VERSION "created by canmatrix"

NS_ :

BS_:

BU_: IPD

BO_ 1948 DIAG_DTCInfo_FDR: 8 Vector__XXX
 SG_ IDTCInfomationFDR : 7|56@0+ (1,0) [0|72057594037927935] "null" IPD

BO_ 1949 DIAG_DTCInfo_ICBAD: 8 IPD
 SG_ IDTCInfomationIPD : 7|56@0+ (1,0) [0|72057594037927935] "null" Vector__XXX

BO_ 1319 DKMM_LHBDCANFD_Event_FrS03: 8 Vector__XXX
 SG_ IAIParkngSpcID : 31|5@0+ (1,0) [0|31] "null" IPD

BO_ 2015 Diag_BKPCANFD_FuncReq: 64 Vector__XXX

BO_ 1845 Diag_BKPCANFD_PhyReq_ICBAD: 64 Vector__XXX

BO_ 1853 Diag_BKPCANFD_PhyResp_ICBAD: 64 IPD

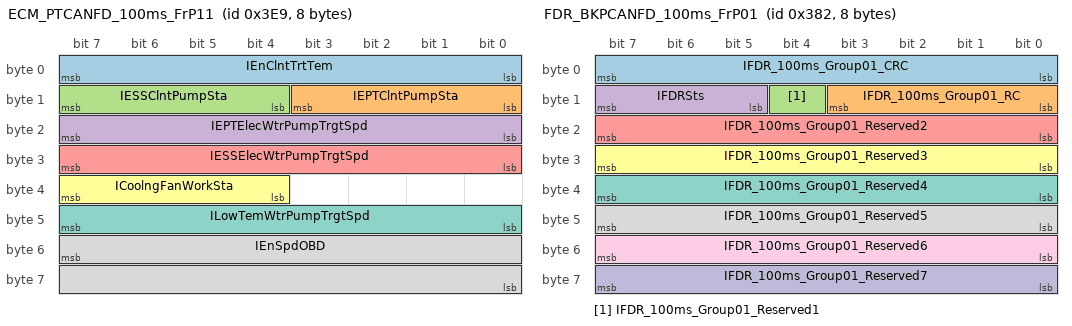
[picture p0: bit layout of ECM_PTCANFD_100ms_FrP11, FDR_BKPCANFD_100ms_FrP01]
BO_ 1001 ECM_PTCANFD_100ms_FrP11: 8 Vector__XXX
 SG_ IEnClntTrtTem : 7|8@0+ (0.5,-40) [-40|87.5] "null" Vector__XXX
 SG_ IEPTClntPumpSta : 11|4@0+ (1,0) [0|15] "null" IPD
 SG_ IESSClntPumpSta : 15|4@0+ (1,0) [0|15] "null" Vector__XXX
 SG_ IEPTElecWtrPumpTrgtSpd : 23|8@0+ (0.4,0) [0|102] "null" Vector__XXX
 SG_ IESSElecWtrPumpTrgtSpd : 31|8@0+ (0.4,0) [0|102] "null" Vector__XXX
 SG_ ICoolngFanWorkSta : 39|4@0+ (1,0) [0|15] "null" Vector__XXX
 SG_ ILowTemWtrPumpTrgtSpd : 47|8@0+ (0.4,0) [0|102] "null" Vector__XXX
 SG_ IEnSpdOBD : 55|16@0+ (0.25,0) [0.00|16383.75] "rpm" Vector__XXX

BO_ 1762 FDR_BKBCANFD_EvtInfo: 8 Vector__XXX
 SG_ IEvtPotclSigFDR : 7|64@0+ (1,0) [0|18446744073709551615] "null" IPD

BO_ 898 FDR_BKPCANFD_100ms_FrP01: 8 Vector__XXX
 SG_ IFDR_100ms_Group01_CRC : 7|8@0+ (1,0) [0|255] "null" IPD
 SG_ IFDR_100ms_Group01_RC : 11|4@0+ (1,0) [0|15] "null" IPD
 SG_ IFDR_100ms_Group01_Reserved1 : 12|1@0+ (1,0) [0|1] "null" IPD
 SG_ IFDRSts : 15|3@0+ (1,0) [0|7] "null" IPD
 SG_ IFDR_100ms_Group01_Reserved2 : 23|8@0+ (1,0) [0|255] "null" IPD
 SG_ IFDR_100ms_Group01_Reserved3 : 31|8@0+ (1,0) [0|255] "null" IPD
 SG_ IFDR_100ms_Group01_Reserved4 : 39|8@0+ (1,0) [0|255] "null" IPD
 SG_ IFDR_100ms_Group01_Reserved5 : 47|8@0+ (1,0) [0|255] "null" IPD
 SG_ IFDR_100ms_Group01_Reserved6 : 55|8@0+ (1,0) [0|255] "null" IPD
 SG_ IFDR_100ms_Group01_Reserved7 : 63|8@0+ (1,0) [0|255] "null" IPD

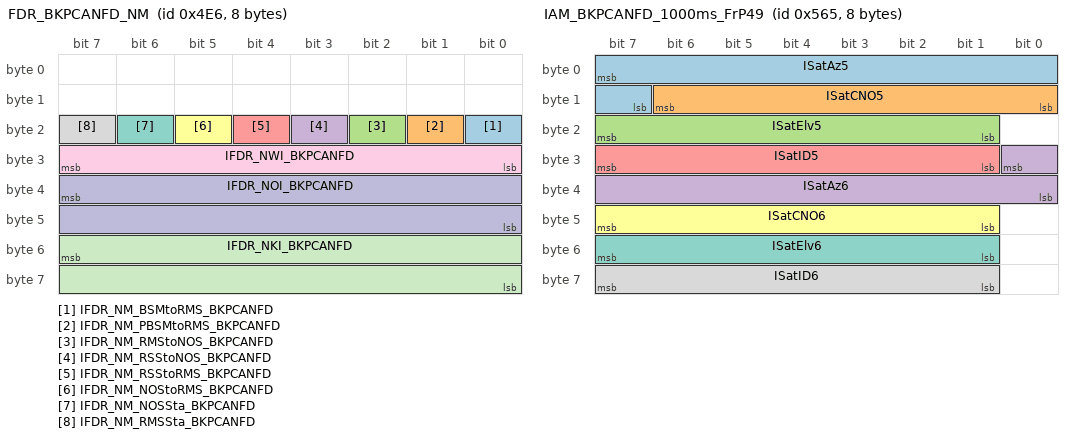
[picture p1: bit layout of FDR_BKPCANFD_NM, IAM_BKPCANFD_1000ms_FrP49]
BO_ 1254 FDR_BKPCANFD_NM: 8 Vector__XXX
 SG_ IFDR_NM_BSMtoRMS_BKPCANFD : 16|1@0+ (1,0) [0|1] "null" IPD
 SG_ IFDR_NM_PBSMtoRMS_BKPCANFD : 17|1@0+ (1,0) [0|1] "null" IPD
 SG_ IFDR_NM_RMStoNOS_BKPCANFD : 18|1@0+ (1,0) [0|1] "null" IPD
 SG_ IFDR_NM_RSStoNOS_BKPCANFD : 19|1@0+ (1,0) [0|1] "null" IPD
 SG_ IFDR_NM_RSStoRMS_BKPCANFD : 20|1@0+ (1,0) [0|1] "null" IPD
 SG_ IFDR_NM_NOStoRMS_BKPCANFD : 21|1@0+ (1,0) [0|1] "null" IPD
 SG_ IFDR_NM_NOSSta_BKPCANFD : 22|1@0+ (1,0) [0|1] "null" IPD
 SG_ IFDR_NM_RMSSta_BKPCANFD : 23|1@0+ (1,0) [0|1] "null" IPD
 SG_ IFDR_NWI_BKPCANFD : 31|8@0+ (1,0) [0|255] "null" IPD
 SG_ IFDR_NOI_BKPCANFD : 39|16@0+ (1,0) [0|65535] "null" IPD
 SG_ IFDR_NKI_BKPCANFD : 55|16@0+ (1,0) [0|65535] "null" IPD

BO_ 139 FDR_SecOC_ComKeyResp: 8 Vector__XXX
 SG_ IFDRTripCtrRstResp : 6|1@0+ (1,0) [0|1] "null" IPD
 SG_ IFDRComKeyEnbResp : 7|1@0+ (1,0) [0|1] "null" IPD

BO_ 958 FVCM_BKPCANFD_100ms_FrP04: 64 IPD
 SG_ IACCConfmSw : 137|2@0+ (1,0) [0|3] "null" Vector__XXX
 SG_ IELKWarning : 191|4@0+ (1,0) [0|15] "null" Vector__XXX
 SG_ IACCDrvrTkovReq : 256|1@0+ (1,0) [0|1] "null" Vector__XXX

BO_ 956 FVCM_BKPCANFD_100ms_FrP05: 64 IPD
 SG_ IPilotSysMsg : 15|4@0+ (1,0) [0|15] "null" Vector__XXX
 SG_ ILane0_C0 : 23|12@0+ (0.00390625,-8) [-8.00000000|7.99609375] "null" Vector__XXX
 SG_ ILane0_C1 : 27|12@0+ (0.00048828125,-1) [-1.00000000000|0.99951171875] "null" Vector__XXX
 SG_ ILane0_C2 : 47|12@0+ (0.000015259,-0.03124285) [-0.031242850|0.031242755] "null" Vector__XXX
 SG_ ILane0_C3 : 51|12@0+ (4.768E-007,-2.3842E-007) [-2.3842E-007|0.00195225758] "null" Vector__XXX
 SG_ ILane1_C0 : 71|12@0+ (0.00390625,-8) [-8.00000000|7.99609375] "null" Vector__XXX
 SG_ ILane1_C1 : 75|12@0+ (0.00048828125,-1) [-1.00000000000|0.99951171875] "null" Vector__XXX
 SG_ ILane1_C2 : 95|12@0+ (0.000015259,-0.03124285) [-0.031242850|0.031242755] "null" Vector__XXX
 SG_ ILane1_C3 : 99|12@0+ (4.768E-007,-2.3842E-007) [-2.3842E-007|0.00195225758] "null" Vector__XXX
 SG_ ILane0_ViewRangeStart : 215|8@0+ (0.25,0) [0.00|63.75] "null" Vector__XXX
 SG_ ILane1_ViewRangeStart : 223|8@0+ (0.25,0) [0.00|63.75] "null" Vector__XXX
 SG_ ILane0_ViewRangeEnd : 247|9@0+ (0.25,0) [0.00|127.75] "null" Vector__XXX
 SG_ ILane1_ViewRangeEnd : 248|9@0+ (0.25,0) [0.00|127.75] "null" Vector__XXX
 SG_ ILane0_ExistPrblty : 254|6@0+ (0.015625,0) [0.000000|0.984375] "null" Vector__XXX
 SG_ ILane1_ExistPrblty : 278|6@0+ (0.015625,0) [0.000000|0.984375] "null" Vector__XXX
 SG_ ILane0_ID : 295|4@0+ (1,0) [0|15] "null" Vector__XXX
 SG_ ILane1_ID : 303|4@0+ (1,0) [0|15] "null" Vector__XXX
 SG_ ITLRMsgReq : 321|2@0+ (1,0) [0|3] "null" Vector__XXX
 SG_ ILane0_location : 327|3@0+ (1,0) [0|7] "null" Vector__XXX
 SG_ ITLRSysSts : 329|2@0+ (1,0) [0|3] "null" Vector__XXX
 SG_ ILane1_location : 332|3@0+ (1,0) [0|7] "null" Vector__XXX
 SG_ ITrgtSpdSrcSts_IPD : 337|2@0+ (1,0) [0|3] "null" Vector__XXX
 SG_ ISLIFWrnngMdResp : 345|2@0+ (1,0) [0|3] "null" Vector__XXX
 SG_ ITLRWarning : 388|3@0+ (1,0) [0|7] "null" Vector__XXX
 SG_ ITLRMdSwDspCmd : 391|3@0+ (1,0) [0|7] "null" Vector__XXX
 SG_ ISpdLmtOfstSetResp : 399|6@0+ (1,-20) [-20|43] "null" Vector__XXX
 SG_ ISLIFAudWrnng_IPD : 472|1@0+ (1,0) [0|1] "null" Vector__XXX
 SG_ ISLIFUpdtIndResp_IPD : 473|1@0+ (1,0) [0|1] "null" Vector__XXX
 SG_ ISLIFUpdtInd_IPD : 500|1@0+ (1,0) [0|1] "null" Vector__XXX
 SG_ ICCSpdVcCmdCnfm : 503|3@0+ (1,0) [0|7] "null" Vector__XXX

BO_ 307 FVCM_BKPCANFD_20ms_FrP02: 16 IPD
 SG_ IFVCM_20ms_Group02_CRC : 7|8@0+ (1,0) [0|255] "null" Vector__XXX
 SG_ IFVCM_20ms_Group02_RC : 11|4@0+ (1,0) [0|15] "null" Vector__XXX
 SG_ IFVCM_20ms_Group02_Reserved1 : 15|4@0+ (1,0) [0|15] "null" Vector__XXX
 SG_ IFVCM_20ms_Group02_Reserved2 : 23|8@0+ (1,0) [0|255] "null" Vector__XXX
 SG_ IFVCM_20ms_Group02_Reserved3 : 31|8@0+ (1,0) [0|255] "null" Vector__XXX
 SG_ IACCDrvrSelTrgtSpd : 39|15@0+ (0.015625,0) [0.000000|511.984375] "ms" Vector__XXX
 SG_ IACCGoNotfr : 40|1@0+ (1,0) [0|1] "null" Vector__XXX
 SG_ IFVCM_20ms_Group02_Reserved4 : 48|1@0+ (1,0) [0|1] "null" Vector__XXX
 SG_ IACCDetObjDistLvl : 51|3@0+ (1,0) [0|7] "null" Vector__XXX
 SG_ IELKSysSts_IPD : 55|4@0+ (1,0) [0|15] "null" Vector__XXX
 SG_ IFVCM_20ms_Group02_Reserved5 : 57|2@0+ (1,0) [0|3] "null" Vector__XXX
 SG_ IACCTJAMdSwDspCmd : 60|3@0+ (1,0) [0|7] "null" Vector__XXX
 SG_ IACCSeldTrgtDistLvl : 63|3@0+ (1,0) [0|7] "null" Vector__XXX
 SG_ IFVCM_20ms_Group02_Reserved6 : 71|8@0+ (1,0) [0|255] "null" Vector__XXX
 SG_ IHandOffStrgWhlDetnSta : 73|2@0+ (1,0) [0|3] "null" Vector__XXX
 SG_ IILCActvnDircnDspCmd : 76|3@0+ (1,0) [0|7] "null" Vector__XXX
 SG_ IFVCM_20ms_Group02_Reserved7 : 79|3@0+ (1,0) [0|7] "null" Vector__XXX
 SG_ IILCSwDspCmd : 81|2@0+ (1,0) [0|3] "null" Vector__XXX
 SG_ IILCSysSts : 84|3@0+ (1,0) [0|7] "null" Vector__XXX
 SG_ IILCActvnVelDspCmd : 87|3@0+ (1,0) [0|7] "null" Vector__XXX
 SG_ IHandOffStrgWhlDetnStaV : 88|1@0+ (1,0) [0|1] "null" Vector__XXX
 SG_ ILDWLKAAudReq : 90|2@0+ (1,0) [0|3] "null" Vector__XXX
 SG_ ILDWAdoWrnngDspCmd : 92|2@0+ (1,0) [0|3] "null" Vector__XXX
 SG_ ILDWLKADspCmd : 95|3@0+ (1,0) [0|7] "null" Vector__XXX
 SG_ IFVCM_20ms_Group02_Reserved8 : 98|3@0+ (1,0) [0|7] "null" Vector__XXX
 SG_ ILKADrvrTkovReq : 99|1@0+ (1,0) [0|1] "null" Vector__XXX
 SG_ ILDWSnstvtLvl : 101|2@0+ (1,0) [0|3] "null" Vector__XXX
 SG_ ILDWLKAHptWrnngDspCmd : 103|2@0+ (1,0) [0|3] "null" Vector__XXX
 SG_ IFVCM_20ms_Group02_Reserved9 : 111|8@0+ (1,0) [0|255] "null" Vector__XXX
 SG_ IFVCM_20ms_Group02_Reserved10 : 114|3@0+ (1,0) [0|7] "null" Vector__XXX
 SG_ IACCMsgReq : 119|5@0+ (1,0) [0|31] "null" Vector__XXX
 SG_ IFVCM_20ms_Group02_Reserved11 : 127|8@0+ (1,0) [0|255] "null" Vector__XXX

BO_ 747 FVCM_BKPCANFD_50ms_FrP03: 12 IPD
 SG_ IFVCM_50ms_Group03_CRC : 7|8@0+ (1,0) [0|255] "null" Vector__XXX
 SG_ IFVCM_50ms_Group03_RC : 11|4@0+ (1,0) [0|15] "null" Vector__XXX
 SG_ IKeepPwrRsnFVCM : 15|4@0+ (1,0) [0|15] "null" Vector__XXX
 SG_ IFVCM_50ms_Group03_Reserved1 : 21|6@0+ (1,0) [0|63] "null" Vector__XXX
 SG_ ITLRTrafficLightsCircleDsp : 23|2@0+ (1,0) [0|3] "null" Vector__XXX
 SG_ IFVCM_50ms_Group03_Reserved2 : 31|8@0+ (1,0) [0|255] "null" Vector__XXX
 SG_ IFVCM_50ms_Group03_Reserved3 : 39|8@0+ (1,0) [0|255] "null" Vector__XXX
 SG_ IFVCM_50ms_Group03_Reserved4 : 47|8@0+ (1,0) [0|255] "null" Vector__XXX
 SG_ IFVCM_50ms_Group03_Reserved5 : 55|8@0+ (1,0) [0|255] "null" Vector__XXX
 SG_ IFVCM_50ms_Group03_Reserved6 : 63|8@0+ (1,0) [0|255] "null" Vector__XXX
 SG_ IFVCM_50ms_Group03_Reserved7 : 71|8@0+ (1,0) [0|255] "null" Vector__XXX
 SG_ IFVCM_50ms_Group03_Reserved8 : 79|8@0+ (1,0) [0|255] "null" Vector__XXX
 SG_ IFVCM_50ms_Group03_Reserved9 : 87|8@0+ (1,0) [0|255] "null" Vector__XXX
 SG_ IFVCM_50ms_Group03_Reserved10 : 95|8@0+ (1,0) [0|255] "null" Vector__XXX

BO_ 1381 IAM_BKPCANFD_1000ms_FrP49: 8 Vector__XXX
 SG_ ISatAz5 : 7|9@0+ (1,0) [0|511] "Degree" IPD
 SG_ ISatCNO5 : 14|7@0+ (1,0) [0|127] "dB" IPD
 SG_ ISatElv5 : 23|7@0+ (1,0) [0|127] "Degree" IPD
 SG_ ISatAz6 : 24|9@0+ (1,0) [0|511] "Degree" IPD
 SG_ ISatID5 : 31|7@0+ (1,0) [0|127] "null" IPD
 SG_ ISatCNO6 : 47|7@0+ (1,0) [0|127] "dB" IPD
 SG_ ISatElv6 : 55|7@0+ (1,0) [0|127] "Degree" IPD
 SG_ ISatID6 : 63|7@0+ (1,0) [0|127] "null" IPD

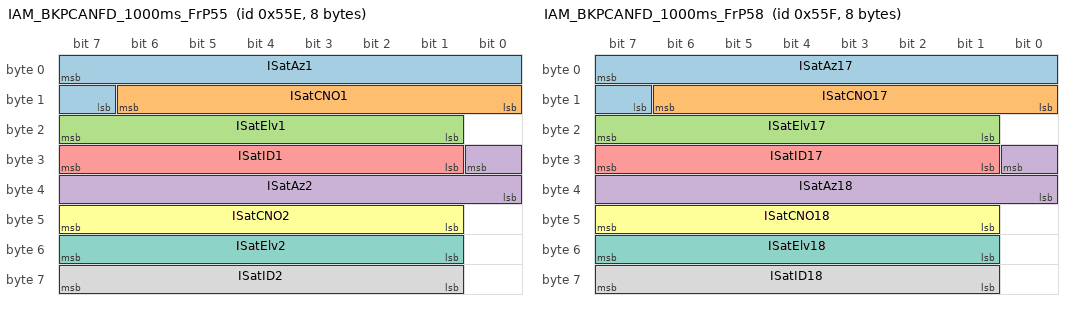
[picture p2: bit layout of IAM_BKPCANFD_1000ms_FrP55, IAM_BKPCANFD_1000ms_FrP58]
BO_ 1374 IAM_BKPCANFD_1000ms_FrP55: 8 Vector__XXX
 SG_ ISatAz1 : 7|9@0+ (1,0) [0|511] "Degree" IPD
 SG_ ISatCNO1 : 14|7@0+ (1,0) [0|127] "dB" IPD
 SG_ ISatElv1 : 23|7@0+ (1,0) [0|127] "Degree" IPD
 SG_ ISatAz2 : 24|9@0+ (1,0) [0|511] "Degree" IPD
 SG_ ISatID1 : 31|7@0+ (1,0) [0|127] "null" IPD
 SG_ ISatCNO2 : 47|7@0+ (1,0) [0|127] "dB" IPD
 SG_ ISatElv2 : 55|7@0+ (1,0) [0|127] "Degree" IPD
 SG_ ISatID2 : 63|7@0+ (1,0) [0|127] "null" IPD

BO_ 1375 IAM_BKPCANFD_1000ms_FrP58: 8 Vector__XXX
 SG_ ISatAz17 : 7|9@0+ (1,0) [0|511] "Degree" IPD
 SG_ ISatCNO17 : 14|7@0+ (1,0) [0|127] "dB" IPD
 SG_ ISatElv17 : 23|7@0+ (1,0) [0|127] "Degree" IPD
 SG_ ISatAz18 : 24|9@0+ (1,0) [0|511] "Degree" IPD
 SG_ ISatID17 : 31|7@0+ (1,0) [0|127] "null" IPD
 SG_ ISatCNO18 : 47|7@0+ (1,0) [0|127] "dB" IPD
 SG_ ISatElv18 : 55|7@0+ (1,0) [0|127] "Degree" IPD
 SG_ ISatID18 : 63|7@0+ (1,0) [0|127] "null" IPD

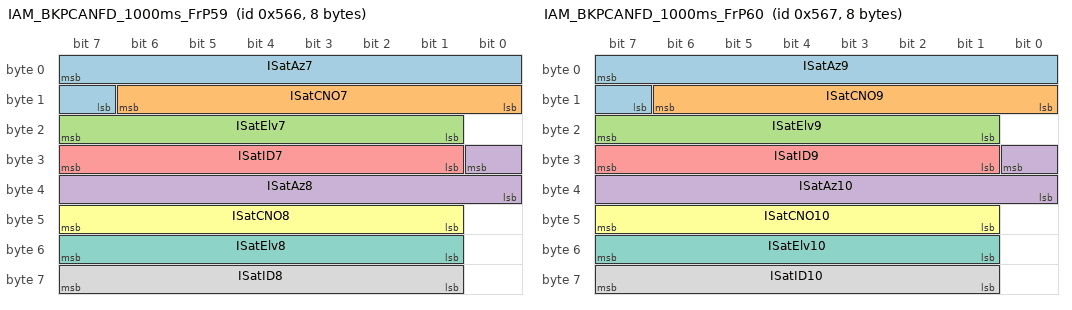
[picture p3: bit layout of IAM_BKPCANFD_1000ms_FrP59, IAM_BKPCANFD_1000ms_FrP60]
BO_ 1382 IAM_BKPCANFD_1000ms_FrP59: 8 Vector__XXX
 SG_ ISatAz7 : 7|9@0+ (1,0) [0|511] "Degree" IPD
 SG_ ISatCNO7 : 14|7@0+ (1,0) [0|127] "dB" IPD
 SG_ ISatElv7 : 23|7@0+ (1,0) [0|127] "Degree" IPD
 SG_ ISatAz8 : 24|9@0+ (1,0) [0|511] "Degree" IPD
 SG_ ISatID7 : 31|7@0+ (1,0) [0|127] "null" IPD
 SG_ ISatCNO8 : 47|7@0+ (1,0) [0|127] "dB" IPD
 SG_ ISatElv8 : 55|7@0+ (1,0) [0|127] "Degree" IPD
 SG_ ISatID8 : 63|7@0+ (1,0) [0|127] "null" IPD

BO_ 1383 IAM_BKPCANFD_1000ms_FrP60: 8 Vector__XXX
 SG_ ISatAz9 : 7|9@0+ (1,0) [0|511] "Degree" IPD
 SG_ ISatCNO9 : 14|7@0+ (1,0) [0|127] "dB" IPD
 SG_ ISatElv9 : 23|7@0+ (1,0) [0|127] "Degree" IPD
 SG_ ISatAz10 : 24|9@0+ (1,0) [0|511] "Degree" IPD
 SG_ ISatID9 : 31|7@0+ (1,0) [0|127] "null" IPD
 SG_ ISatCNO10 : 47|7@0+ (1,0) [0|127] "dB" IPD
 SG_ ISatElv10 : 55|7@0+ (1,0) [0|127] "Degree" IPD
 SG_ ISatID10 : 63|7@0+ (1,0) [0|127] "null" IPD

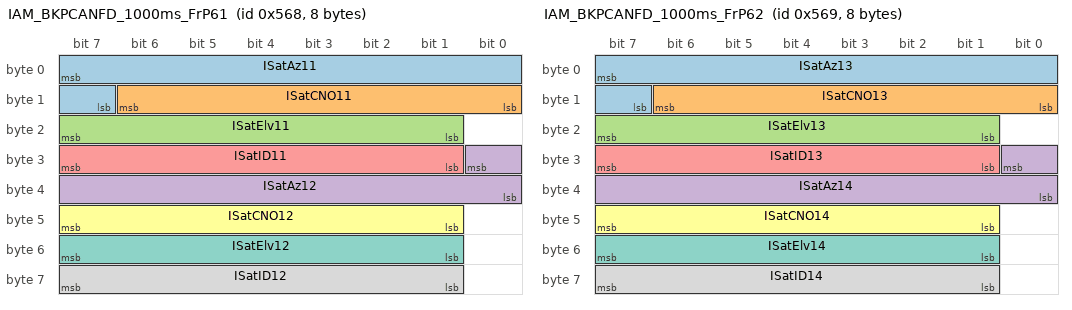
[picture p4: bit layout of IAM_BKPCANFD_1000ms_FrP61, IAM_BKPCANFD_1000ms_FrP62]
BO_ 1384 IAM_BKPCANFD_1000ms_FrP61: 8 Vector__XXX
 SG_ ISatAz11 : 7|9@0+ (1,0) [0|511] "Degree" IPD
 SG_ ISatCNO11 : 14|7@0+ (1,0) [0|127] "dB" IPD
 SG_ ISatElv11 : 23|7@0+ (1,0) [0|127] "Degree" IPD
 SG_ ISatAz12 : 24|9@0+ (1,0) [0|511] "Degree" IPD
 SG_ ISatID11 : 31|7@0+ (1,0) [0|127] "null" IPD
 SG_ ISatCNO12 : 47|7@0+ (1,0) [0|127] "dB" IPD
 SG_ ISatElv12 : 55|7@0+ (1,0) [0|127] "Degree" IPD
 SG_ ISatID12 : 63|7@0+ (1,0) [0|127] "null" IPD

BO_ 1385 IAM_BKPCANFD_1000ms_FrP62: 8 Vector__XXX
 SG_ ISatAz13 : 7|9@0+ (1,0) [0|511] "Degree" IPD
 SG_ ISatCNO13 : 14|7@0+ (1,0) [0|127] "dB" IPD
 SG_ ISatElv13 : 23|7@0+ (1,0) [0|127] "Degree" IPD
 SG_ ISatAz14 : 24|9@0+ (1,0) [0|511] "Degree" IPD
 SG_ ISatID13 : 31|7@0+ (1,0) [0|127] "null" IPD
 SG_ ISatCNO14 : 47|7@0+ (1,0) [0|127] "dB" IPD
 SG_ ISatElv14 : 55|7@0+ (1,0) [0|127] "Degree" IPD
 SG_ ISatID14 : 63|7@0+ (1,0) [0|127] "null" IPD

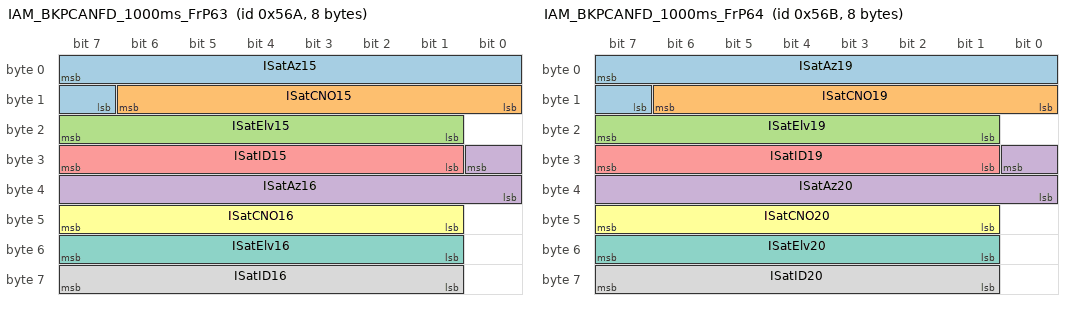
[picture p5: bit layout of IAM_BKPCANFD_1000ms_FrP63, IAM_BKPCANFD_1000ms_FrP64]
BO_ 1386 IAM_BKPCANFD_1000ms_FrP63: 8 Vector__XXX
 SG_ ISatAz15 : 7|9@0+ (1,0) [0|511] "Degree" IPD
 SG_ ISatCNO15 : 14|7@0+ (1,0) [0|127] "dB" IPD
 SG_ ISatElv15 : 23|7@0+ (1,0) [0|127] "Degree" IPD
 SG_ ISatAz16 : 24|9@0+ (1,0) [0|511] "Degree" IPD
 SG_ ISatID15 : 31|7@0+ (1,0) [0|127] "null" IPD
 SG_ ISatCNO16 : 47|7@0+ (1,0) [0|127] "dB" IPD
 SG_ ISatElv16 : 55|7@0+ (1,0) [0|127] "Degree" IPD
 SG_ ISatID16 : 63|7@0+ (1,0) [0|127] "null" IPD

BO_ 1387 IAM_BKPCANFD_1000ms_FrP64: 8 Vector__XXX
 SG_ ISatAz19 : 7|9@0+ (1,0) [0|511] "Degree" IPD
 SG_ ISatCNO19 : 14|7@0+ (1,0) [0|127] "dB" IPD
 SG_ ISatElv19 : 23|7@0+ (1,0) [0|127] "Degree" IPD
 SG_ ISatAz20 : 24|9@0+ (1,0) [0|511] "Degree" IPD
 SG_ ISatID19 : 31|7@0+ (1,0) [0|127] "null" IPD
 SG_ ISatCNO20 : 47|7@0+ (1,0) [0|127] "dB" IPD
 SG_ ISatElv20 : 55|7@0+ (1,0) [0|127] "Degree" IPD
 SG_ ISatID20 : 63|7@0+ (1,0) [0|127] "null" IPD

BO_ 1388 IAM_BKPCANFD_1000ms_FrP65: 8 Vector__XXX
 SG_ ISatNum : 7|7@0+ (1,0) [0|127] "null" IPD
 SG_ ISvGroup : 15|8@0+ (1,0) [0|255] "null" IPD

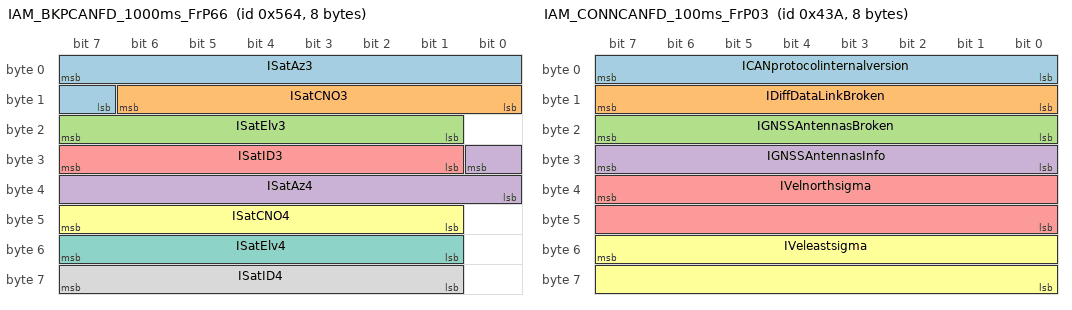
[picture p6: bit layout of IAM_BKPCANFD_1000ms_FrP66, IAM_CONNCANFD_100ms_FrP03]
BO_ 1380 IAM_BKPCANFD_1000ms_FrP66: 8 Vector__XXX
 SG_ ISatAz3 : 7|9@0+ (1,0) [0|511] "Degree" IPD
 SG_ ISatCNO3 : 14|7@0+ (1,0) [0|127] "dB" IPD
 SG_ ISatElv3 : 23|7@0+ (1,0) [0|127] "Degree" IPD
 SG_ ISatAz4 : 24|9@0+ (1,0) [0|511] "Degree" IPD
 SG_ ISatID3 : 31|7@0+ (1,0) [0|127] "null" IPD
 SG_ ISatCNO4 : 47|7@0+ (1,0) [0|127] "dB" IPD
 SG_ ISatElv4 : 55|7@0+ (1,0) [0|127] "Degree" IPD
 SG_ ISatID4 : 63|7@0+ (1,0) [0|127] "null" IPD

BO_ 298 IAM_BKPCANFD_20ms_FrP10: 8 Vector__XXX
 SG_ IP2PExeAvlblV : 14|1@0+ (1,0) [0|1] "null" IPD
 SG_ IP2PExeAvlbl : 15|1@0+ (1,0) [0|1] "null" IPD

BO_ 1082 IAM_CONNCANFD_100ms_FrP03: 8 Vector__XXX
 SG_ ICANprotocolinternalversion : 7|8@0+ (1,0) [0|255] "null" IPD
 SG_ IDiffDataLinkBroken : 15|8@0+ (1,0) [0|255] "null" IPD
 SG_ IGNSSAntennasBroken : 23|8@0+ (1,0) [0|255] "null" IPD
 SG_ IGNSSAntennasInfo : 31|8@0+ (1,0) [0|255] "null" IPD
 SG_ IVelnorthsigma : 39|16@0+ (0.001,0) [0.000|65.535] "null" IPD
 SG_ IVeleastsigma : 55|16@0+ (0.001,0) [0.000|65.535] "null" IPD

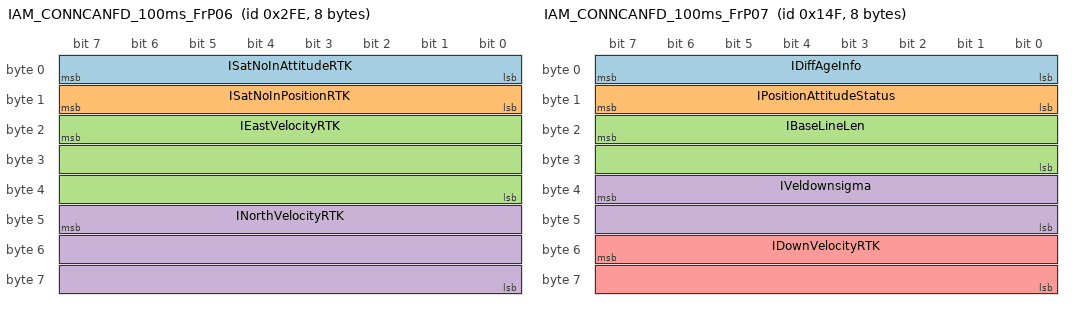
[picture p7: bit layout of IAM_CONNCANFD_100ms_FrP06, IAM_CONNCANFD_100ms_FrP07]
BO_ 766 IAM_CONNCANFD_100ms_FrP06: 8 Vector__XXX
 SG_ ISatNoInAttitudeRTK : 7|8@0+ (1,0) [0|255] "null" IPD
 SG_ ISatNoInPositionRTK : 15|8@0+ (1,0) [0|255] "null" IPD
 SG_ IEastVelocityRTK : 23|24@0- (0.001,0) [-8388.608|8388.607] "null" IPD
 SG_ INorthVelocityRTK : 47|24@0- (0.001,0) [-8388.608|8388.607] "null" IPD

BO_ 335 IAM_CONNCANFD_100ms_FrP07: 8 Vector__XXX
 SG_ IDiffAgeInfo : 7|8@0+ (1,0) [0|255] "null" IPD
 SG_ IPositionAttitudeStatus : 15|8@0+ (1,0) [0|255] "null" IPD
 SG_ IBaseLineLen : 23|16@0+ (0.001,0) [0.000|65.535] "null" IPD
 SG_ IVeldownsigma : 39|16@0+ (0.001,0) [0.000|65.535] "null" IPD
 SG_ IDownVelocityRTK : 55|16@0- (0.001,0) [-32.768|32.767] "null" IPD

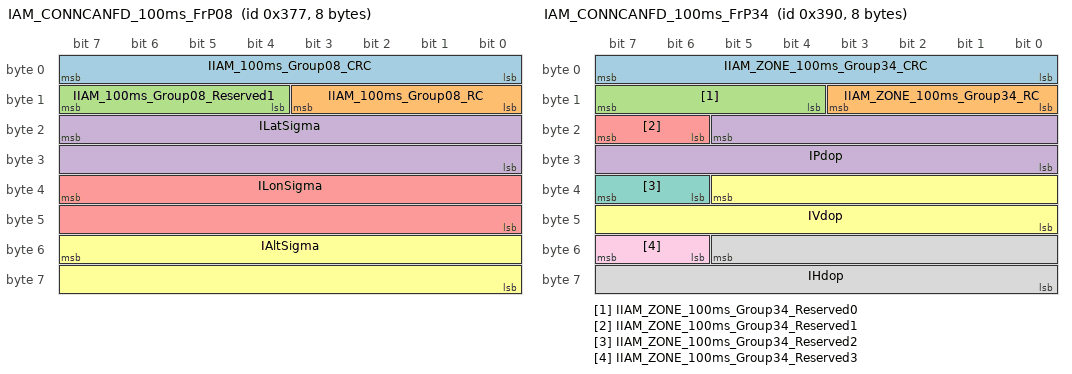
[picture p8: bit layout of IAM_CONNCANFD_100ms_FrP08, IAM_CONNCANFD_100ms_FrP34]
BO_ 887 IAM_CONNCANFD_100ms_FrP08: 8 Vector__XXX
 SG_ IIAM_100ms_Group08_CRC : 7|8@0+ (1,0) [0|255] "null" IPD
 SG_ IIAM_100ms_Group08_RC : 11|4@0+ (1,0) [0|15] "null" IPD
 SG_ IIAM_100ms_Group08_Reserved1 : 15|4@0+ (1,0) [0|15] "null" IPD
 SG_ ILatSigma : 23|16@0+ (0.001,0) [0.000|65.535] "null" IPD
 SG_ ILonSigma : 39|16@0+ (0.001,0) [0.000|65.535] "null" IPD
 SG_ IAltSigma : 55|16@0+ (0.001,0) [0.000|65.535] "null" IPD

BO_ 700 IAM_CONNCANFD_100ms_FrP19: 32 Vector__XXX
 SG_ IIAMtoIPD_Rsrv01 : 1|2@0+ (1,0) [0|3] "null" IPD
 SG_ IIAMtoIPD_Rsrv05 : 4|3@0+ (1,0) [0|7] "null" IPD
 SG_ IIAMtoIPD_Rsrv04 : 7|3@0+ (1,0) [0|7] "null" IPD
 SG_ IIAMtoIPD_Rsrv02 : 9|2@0+ (1,0) [0|3] "null" IPD
 SG_ IIAMtoIPD_Rsrv07 : 12|3@0+ (1,0) [0|7] "null" IPD
 SG_ IIAMtoIPD_Rsrv06 : 15|3@0+ (1,0) [0|7] "null" IPD
 SG_ IIAMtoIPD_Rsrv09 : 19|4@0+ (1,0) [0|15] "null" IPD
 SG_ IIAMtoIPD_Rsrv08 : 23|4@0+ (1,0) [0|15] "null" IPD
 SG_ IIAMtoIPD_Rsrv10 : 31|8@0+ (1,0) [0|255] "null" IPD
 SG_ IIAMtoIPD_Rsrv11 : 39|8@0+ (1,0) [0|255] "null" IPD
 SG_ IIAMtoIPD_Rsrv12 : 47|16@0+ (1,0) [0|65535] "null" IPD
 SG_ IIAMtoIPD_Rsrv03 : 63|2@0+ (1,0) [0|3] "null" IPD
 SG_ IIAMtoIPDResv15 : 71|16@0+ (1,0) [0|65535] "null" IPD
 SG_ IIAMtoIPDResv13 : 127|8@0+ (1,0) [0|255] "null" IPD
 SG_ IIAMtoIPDResv14 : 135|8@0+ (1,0) [0|255] "null" IPD

BO_ 912 IAM_CONNCANFD_100ms_FrP34: 8 Vector__XXX
 SG_ IIAM_ZONE_100ms_Group34_CRC : 7|8@0+ (1,0) [0|255] "null" IPD
 SG_ IIAM_ZONE_100ms_Group34_RC : 11|4@0+ (1,0) [0|15] "null" IPD
 SG_ IIAM_ZONE_100ms_Group34_Reserved0 : 15|4@0+ (1,0) [0|15] "null" IPD
 SG_ IPdop : 21|14@0+ (0.01,0) [0.00|163.83] "null" IPD
 SG_ IIAM_ZONE_100ms_Group34_Reserved1 : 23|2@0+ (1,0) [0|3] "null" IPD
 SG_ IVdop : 37|14@0+ (0.01,0) [0.00|163.83] "null" IPD
 SG_ IIAM_ZONE_100ms_Group34_Reserved2 : 39|2@0+ (1,0) [0|3] "null" IPD
 SG_ IHdop : 53|14@0+ (0.01,0) [0.00|163.83] "null" IPD
 SG_ IIAM_ZONE_100ms_Group34_Reserved3 : 55|2@0+ (1,0) [0|3] "null" IPD

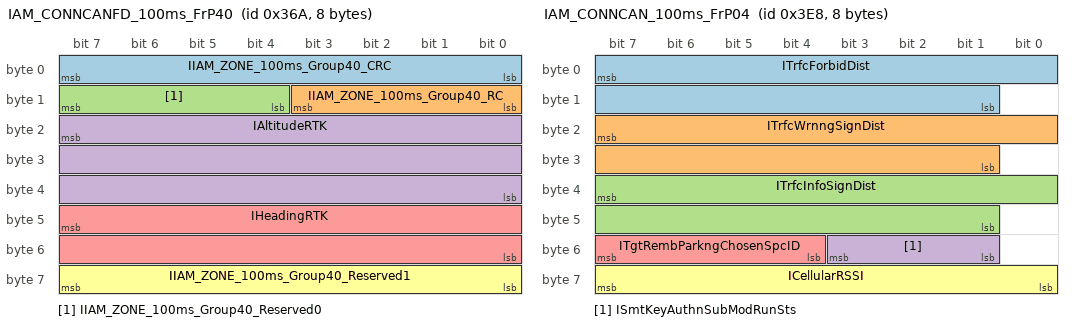
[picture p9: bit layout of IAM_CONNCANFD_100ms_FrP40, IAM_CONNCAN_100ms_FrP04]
BO_ 874 IAM_CONNCANFD_100ms_FrP40: 8 Vector__XXX
 SG_ IIAM_ZONE_100ms_Group40_CRC : 7|8@0+ (1,0) [0|255] "null" IPD
 SG_ IIAM_ZONE_100ms_Group40_RC : 11|4@0+ (1,0) [0|15] "null" IPD
 SG_ IIAM_ZONE_100ms_Group40_Reserved0 : 15|4@0+ (1,0) [0|15] "null" IPD
 SG_ IAltitudeRTK : 23|24@0- (0.001,0) [-8388.608|8388.607] "null" IPD
 SG_ IHeadingRTK : 47|16@0+ (0.01,0) [0.00|655.35] "null" IPD
 SG_ IIAM_ZONE_100ms_Group40_Reserved1 : 63|8@0+ (1,0) [0|255] "null" IPD

BO_ 336 IAM_CONNCANFD_20ms_FrP32: 16 Vector__XXX
 SG_ IIAM_20ms_Group32_CRC : 7|8@0+ (1,0) [0|255] "null" IPD
 SG_ IIAM_20ms_Group32_RC : 11|4@0+ (1,0) [0|15] "null" IPD
 SG_ IRmtParkngAstParkngOutDircnSeln : 15|4@0+ (1,0) [0|15] "null" IPD
 SG_ IRmtParkngAstBtnSts : 16|1@0+ (1,0) [0|1] "null" IPD
 SG_ IVehFwdSwReq : 18|2@0+ (1,0) [0|3] "null" IPD
 SG_ IVehBkwdSwReq : 20|2@0+ (1,0) [0|3] "null" IPD
 SG_ IRmtParkngAstDvcSts : 23|3@0+ (1,0) [0|7] "null" IPD
 SG_ IIAM_20ms_Group32_Reserved1 : 31|8@0+ (1,0) [0|255] "null" IPD
 SG_ IIAM_20ms_Group32_Reserved2 : 39|8@0+ (1,0) [0|255] "null" IPD
 SG_ IIAM_20ms_Group32_Reserved3 : 47|8@0+ (1,0) [0|255] "null" IPD
 SG_ IIAM_20ms_Group32_Reserved4 : 55|8@0+ (1,0) [0|255] "null" IPD
 SG_ IIAM_20ms_Group32_Reserved5 : 63|8@0+ (1,0) [0|255] "null" IPD
 SG_ IIAM_20ms_Group32_Reserved6 : 71|8@0+ (1,0) [0|255] "null" IPD
 SG_ IIAM_20ms_Group32_Reserved7 : 79|8@0+ (1,0) [0|255] "null" IPD
 SG_ IIAM_20ms_Group32_Reserved8 : 87|8@0+ (1,0) [0|255] "null" IPD
 SG_ IIAM_20ms_Group32_Reserved9 : 95|8@0+ (1,0) [0|255] "null" IPD
 SG_ IIAM_20ms_Group32_Reserved10 : 103|8@0+ (1,0) [0|255] "null" IPD
 SG_ IIAM_20ms_Group32_Reserved11 : 111|8@0+ (1,0) [0|255] "null" IPD
 SG_ IIAM_20ms_Group32_Reserved12 : 119|8@0+ (1,0) [0|255] "null" IPD
 SG_ IIAM_20ms_Group32_Reserved13 : 127|8@0+ (1,0) [0|255] "null" IPD

BO_ 89 IAM_CONNCANFD_Event_FrS04: 16 Vector__XXX
 SG_ IPkUpPntID : 6|4@0+ (1,0) [0|15] "null" IPD
 SG_ IIAMReststs : 33|2@0+ (1,0) [0|3] "null" IPD

BO_ 1000 IAM_CONNCAN_100ms_FrP04: 8 Vector__XXX
 SG_ ITrfcForbidDist : 7|15@0+ (0.0156,-256) [-256.0000|255.1652] "null" IPD
 SG_ ITrfcWrnngSignDist : 23|15@0+ (0.0156,-256) [-256.0000|255.1652] "null" IPD
 SG_ ITrfcInfoSignDist : 39|15@0+ (0.0156,-256) [-256.0000|255.1652] "null" IPD
 SG_ ISmtKeyAuthnSubModRunSts : 51|3@0+ (1,0) [0|7] "null" Vector__XXX
 SG_ ITgtRembParkngChosenSpcID : 55|4@0+ (1,0) [0|15] "null" IPD
 SG_ ICellularRSSI : 63|8@0+ (1,-256) [-256|-1] "db" IPD

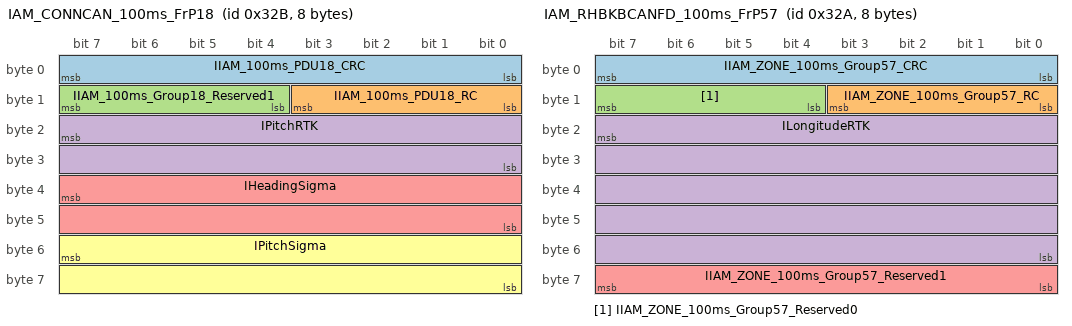
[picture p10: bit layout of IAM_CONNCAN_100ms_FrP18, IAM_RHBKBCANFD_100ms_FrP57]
BO_ 811 IAM_CONNCAN_100ms_FrP18: 8 Vector__XXX
 SG_ IIAM_100ms_PDU18_CRC : 7|8@0+ (1,0) [0|255] "null" IPD
 SG_ IIAM_100ms_PDU18_RC : 11|4@0+ (1,0) [0|15] "null" IPD
 SG_ IIAM_100ms_Group18_Reserved1 : 15|4@0+ (1,0) [0|15] "null" IPD
 SG_ IPitchRTK : 23|16@0- (0.01,0) [-327.68|327.67] "null" IPD
 SG_ IHeadingSigma : 39|16@0+ (0.001,0) [0.000|65.535] "null" IPD
 SG_ IPitchSigma : 55|16@0+ (0.001,0) [0.000|65.535] "null" IPD

BO_ 1358 IAM_CONNCAN_Event_FrS21: 8 Vector__XXX
 SG_ IKeyDeleResp : 43|4@0+ (1,0) [0|15] "null" Vector__XXX
 SG_ IAIParkngReq : 55|8@0+ (1,0) [0|255] "null" IPD

BO_ 810 IAM_RHBKBCANFD_100ms_FrP57: 8 Vector__XXX
 SG_ IIAM_ZONE_100ms_Group57_CRC : 7|8@0+ (1,0) [0|255] "null" IPD
 SG_ IIAM_ZONE_100ms_Group57_RC : 11|4@0+ (1,0) [0|15] "null" IPD
 SG_ IIAM_ZONE_100ms_Group57_Reserved0 : 15|4@0+ (1,0) [0|15] "null" IPD
 SG_ ILongitudeRTK : 23|40@0- (1.0E-009,0) [-549.7558138880|549.7558138870] "null" IPD
 SG_ IIAM_ZONE_100ms_Group57_Reserved1 : 63|8@0+ (1,0) [0|255] "null" IPD

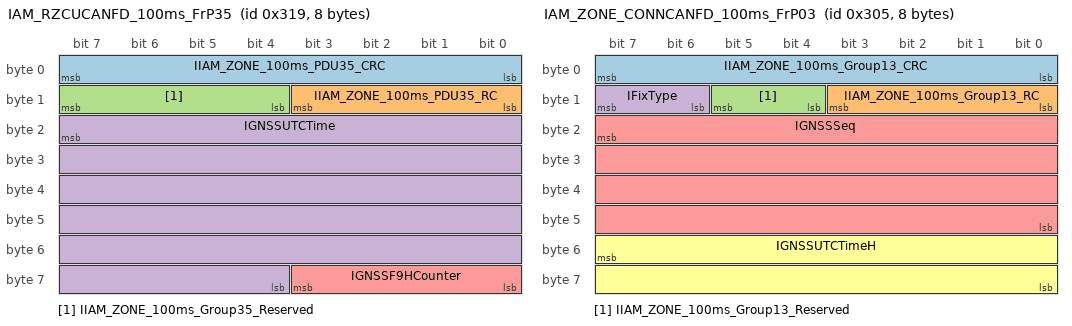
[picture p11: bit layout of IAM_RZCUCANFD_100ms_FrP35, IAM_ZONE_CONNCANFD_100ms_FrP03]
BO_ 793 IAM_RZCUCANFD_100ms_FrP35: 8 Vector__XXX
 SG_ IIAM_ZONE_100ms_PDU35_CRC : 7|8@0+ (1,0) [0|255] "null" IPD
 SG_ IIAM_ZONE_100ms_PDU35_RC : 11|4@0+ (1,0) [0|15] "null" IPD
 SG_ IIAM_ZONE_100ms_Group35_Reserved : 15|4@0+ (1,0) [0|15] "null" IPD
 SG_ IGNSSUTCTime : 23|44@0+ (1,0) [0|17592186044415] "null" IPD
 SG_ IGNSSF9HCounter : 59|4@0+ (1,0) [0|15] "null" IPD

BO_ 773 IAM_ZONE_CONNCANFD_100ms_FrP03: 8 Vector__XXX
 SG_ IIAM_ZONE_100ms_Group13_CRC : 7|8@0+ (1,0) [0|255] "null" IPD
 SG_ IIAM_ZONE_100ms_Group13_RC : 11|4@0+ (1,0) [0|15] "null" IPD
 SG_ IIAM_ZONE_100ms_Group13_Reserved : 13|2@0+ (1,0) [0|3] "null" IPD
 SG_ IFixType : 15|2@0+ (1,0) [0|3] "null" IPD
 SG_ IGNSSSeq : 23|32@0+ (1,0) [0|4294967295] "null" IPD
 SG_ IGNSSUTCTimeH : 55|16@0+ (1,0) [0|65535] "null" IPD

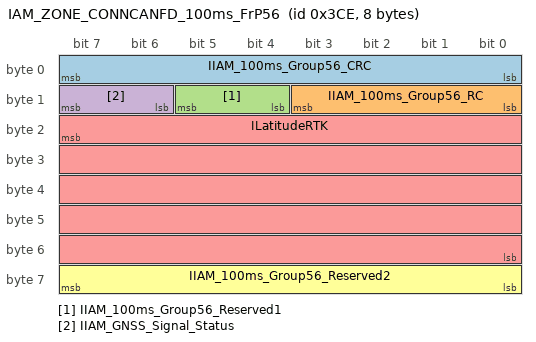
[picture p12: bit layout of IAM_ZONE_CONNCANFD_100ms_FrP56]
BO_ 974 IAM_ZONE_CONNCANFD_100ms_FrP56: 8 Vector__XXX
 SG_ IIAM_100ms_Group56_CRC : 7|8@0+ (1,0) [0|255] "null" IPD
 SG_ IIAM_100ms_Group56_RC : 11|4@0+ (1,0) [0|15] "null" IPD
 SG_ IIAM_100ms_Group56_Reserved1 : 13|2@0+ (1,0) [0|3] "null" IPD
 SG_ IIAM_GNSS_Signal_Status : 15|2@0+ (1,0) [0|3] "null" IPD
 SG_ ILatitudeRTK : 23|40@0- (1.0E-009,0) [-549.7558138880|549.7558138870] "null" IPD
 SG_ IIAM_100ms_Group56_Reserved2 : 63|8@0+ (1,0) [0|255] "null" IPD

BO_ 179 IAM_ZONE_CONNCANFD_Event_FrS01: 48 Vector__XXX
 SG_ IAPPPlnngPathLongdP1 : 7|32@0+ (1.0E-007,0) [0E-008|429.49672950] "null" IPD
 SG_ IAPPPlnngPathLatdP1 : 39|32@0+ (1.0E-007,0) [0E-008|429.49672950] "null" IPD
 SG_ IAPPPlnngPathLongdP2 : 71|32@0+ (1.0E-007,0) [0E-008|429.49672950] "null" IPD
 SG_ IAPPPlnngPathLatdP2 : 103|32@0+ (1.0E-007,0) [0E-008|429.49672950] "null" IPD
 SG_ IAPPPlnngPathLongdP3 : 135|32@0+ (1.0E-007,0) [0E-008|429.49672950] "null" IPD
 SG_ IAPPPlnngPathLatdP3 : 167|32@0+ (1.0E-007,0) [0E-008|429.49672950] "null" IPD
 SG_ IAPPPlnngPathLongdP4 : 199|32@0+ (1.0E-007,0) [0E-008|429.49672950] "null" IPD
 SG_ IAPPPlnngPathLatdP4 : 231|32@0+ (1.0E-007,0) [0E-008|429.49672950] "null" IPD
 SG_ IAPPPlnngPathLongdP5 : 263|32@0+ (1.0E-007,0) [0E-008|429.49672950] "null" IPD
 SG_ IAPPPlnngPathLatdP5 : 295|32@0+ (1.0E-007,0) [0E-008|429.49672950] "null" IPD

BO_ 159 IAM_ZONE_CONNCANFD_Event_FrS02: 48 Vector__XXX
 SG_ IAPPPlnngPathLongdP6 : 7|32@0+ (1.0E-007,0) [0E-008|429.49672950] "null" IPD
 SG_ IAPPPlnngPathLatdP6 : 39|32@0+ (1.0E-007,0) [0E-008|429.49672950] "null" IPD
 SG_ IAPPPlnngPathLongdP7 : 71|32@0+ (1.0E-007,0) [0E-008|429.49672950] "null" IPD
 SG_ IAPPPlnngPathLatdP7 : 103|32@0+ (1.0E-007,0) [0E-008|429.49672950] "null" IPD
 SG_ IAPPPlnngPathLongdP8 : 135|32@0+ (1.0E-007,0) [0E-008|429.49672950] "null" IPD
 SG_ IAPPPlnngPathLatdP8 : 167|32@0+ (1.0E-007,0) [0E-008|429.49672950] "null" IPD
 SG_ IAPPPlnngPathLatdP9 : 199|32@0+ (1.0E-007,0) [0E-008|429.49672950] "null" IPD
 SG_ IAPPPlnngPathLongdP9 : 231|32@0+ (1.0E-007,0) [0E-008|429.49672950] "null" IPD
 SG_ IAPPPlnngPathLongdP10 : 263|32@0+ (1.0E-007,0) [0E-008|429.49672950] "null" IPD
 SG_ IAPPPlnngPathLatdP10 : 295|32@0+ (1.0E-007,0) [0E-008|429.49672950] "null" IPD

BO_ 125 IAM_ZONE_CONNCANFD_Event_FrS03: 16 Vector__XXX
 SG_ ISumnLoctnLatd : 7|32@0+ (1.0E-007,0) [0E-008|429.49672950] "null" IPD
 SG_ IAutodDrvngSysCtrlReq : 39|8@0+ (1,0) [0|255] "null" IPD
 SG_ ISumnLoctnLongd : 47|32@0+ (1.0E-007,0) [0E-008|429.49672950] "null" IPD

BO_ 348 ICBAD_BKPCANFD_100ms_FrP27: 12 IPD
 SG_ IFCWSnstvtLvl : 15|3@0+ (1,0) [0|7] "null" Vector__XXX
 SG_ IAEBDspCmd : 19|2@0+ (1,0) [0|3] "null" Vector__XXX
 SG_ IAEBMsgReq : 23|4@0+ (1,0) [0|15] "null" Vector__XXX
 SG_ IFCWDspCmd : 25|2@0+ (1,0) [0|3] "null" Vector__XXX
 SG_ IFCWSysFltSts : 28|3@0+ (1,0) [0|7] "null" Vector__XXX
 SG_ IFCWrnngSts : 31|3@0+ (1,0) [0|7] "null" Vector__XXX
 SG_ IRembMapBldngQnty : 37|2@0+ (1,0) [0|3] "null" Vector__XXX
 SG_ IRembMapBldngReq : 39|2@0+ (1,0) [0|3] "null" Vector__XXX
 SG_ IRembParkngPrgs : 47|7@0+ (0.01,0) [0.00|1.27] "null" Vector__XXX
 SG_ IMapListResp : 55|10@0+ (1,0) [0|1023] "null" Vector__XXX
 SG_ IAvlblMaps : 68|10@0+ (1,0) [0|1023] "null" Vector__XXX
 SG_ IRembBldMapReq : 72|2@0+ (1,0) [0|3] "null" Vector__XXX
 SG_ IFCTSysFltSts : 81|2@0+ (1,0) [0|3] "null" Vector__XXX
 SG_ IFCTSwSts : 86|3@0+ (1,0) [0|7] "null" Vector__XXX
 SG_ ILFCTWrnng : 92|3@0+ (1,0) [0|7] "null" Vector__XXX
 SG_ IRFCTWrnng : 95|3@0+ (1,0) [0|7] "null" Vector__XXX

BO_ 917 ICBAD_BKPCANFD_100ms_FrP29: 12 IPD
 SG_ IAIPiloTIntervQuit : 47|6@0+ (1,0) [0|63] "null" Vector__XXX
 SG_ IAIParkngDsp : 55|8@0+ (1,0) [0|255] "null" Vector__XXX
 SG_ IAIParkngSts : 63|8@0+ (1,0) [0|255] "null" Vector__XXX

CM_ BU_ IPD "Tbox->IBox->iCD->IAM(20200706)
DRE ->20200915->20201126
-";

BA_DEF_ BO_ "FrameTriggeringName" STRING;
BA_DEF_ BO_ "GenMsgCycleTime" INT 0 65535;
BA_DEF_ BO_ "GenMsgDelayTime" INT 0 65535;
BA_DEF_ BO_ "GenMsgSendType" ENUM  "cyclicX","spontanX","cyclicIfActiveX","spontanWithDelay","cyclicAndSpontanX","cyclicAndSpontanWithDelay","spontanWithRepitition","cyclicIfActiveAndSpontanWD","cyclicIfActiveFast","cyclicWithRepeatOnDemand","none";
BA_DEF_ BO_ "GenMsgStartValue" STRING;
BA_DEF_ BO_ "PduName" STRING;
BA_DEF_ BO_ "VFrameFormat" ENUM  "StandardCAN","ExtendedCAN","reserved","reserved","reserved","reserved","reserved","reserved","reserved","reserved","reserved","reserved","reserved","reserved","StandardCAN_FD","ExtendedCAN_FD";
BA_DEF_ SG_ "CompuMethodName" STRING;
BA_DEF_ SG_ "GenSigStartValue" FLOAT 0 100000000000;
BA_DEF_ SG_ "ISignalName" STRING;
BA_DEF_ SG_ "LongName" STRING;
BA_DEF_ SG_ "SysSignalName" STRING;
BA_DEF_ SG_ "SystemSignalLongSymbol" STRING;
BA_DEF_ BU_ "NWM-Knoten" ENUM  "nein","ja";
BA_DEF_ BU_ "NWM-Stationsadresse" HEX 0 63;
BA_DEF_  "BusType" STRING;
BA_ "NWM-Knoten" BU_ IPD 0;
BA_ "NWM-Stationsadresse" BU_ IPD 0;

BA_ "BusType"   "CAN FD";

BA_ "FrameTriggeringName" BO_ 1948 "DIAG_DTCInfo_FDR";
BA_ "GenMsgSendType" BO_ 1948 1;
BA_ "GenMsgStartValue" BO_ 1948 "0000000000000000";
BA_ "PduName" BO_ 1948 "DIAG_DTCInfo_FDR";
BA_ "VFrameFormat" BO_ 1948 14;
BA_ "FrameTriggeringName" BO_ 1949 "DIAG_DTCInfo_ICBAD";
BA_ "GenMsgSendType" BO_ 1949 1;
BA_ "GenMsgStartValue" BO_ 1949 "0000000000000000";
BA_ "PduName" BO_ 1949 "DIAG_DTCInfo_ICBAD";
BA_ "VFrameFormat" BO_ 1949 14;
BA_ "FrameTriggeringName" BO_ 1319 "DKMM_LHBDCANFD_Event_FrS03";
BA_ "GenMsgDelayTime" BO_ 1319 10;
BA_ "GenMsgSendType" BO_ 1319 1;
BA_ "GenMsgStartValue" BO_ 1319 "0000000000000000";
BA_ "PduName" BO_ 1319 "DKMM_Sporadic_PDU03";
BA_ "VFrameFormat" BO_ 1319 14;
BA_ "FrameTriggeringName" BO_ 2015 "Diag_BKPCANFD_FuncReq_BKPCANFD";
BA_ "GenMsgSendType" BO_ 2015 1;
BA_ "GenMsgStartValue" BO_ 2015 "00000000000000000000000000000000000000000000000000000000000000000000000000000000000000000000000000000000000000000000000000000000";
BA_ "PduName" BO_ 2015 "Diag_BKPCANFD_FuncReq";
BA_ "VFrameFormat" BO_ 2015 14;
BA_ "FrameTriggeringName" BO_ 1845 "Diag_BKPCANFD_PhyReq_ICBAD_BKPCANFD";
BA_ "GenMsgSendType" BO_ 1845 1;
BA_ "GenMsgStartValue" BO_ 1845 "00000000000000000000000000000000000000000000000000000000000000000000000000000000000000000000000000000000000000000000000000000000";
BA_ "PduName" BO_ 1845 "Diag_BKPCANFD_PhyReq_ICBAD";
BA_ "VFrameFormat" BO_ 1845 14;
BA_ "FrameTriggeringName" BO_ 1853 "Diag_BKPCANFD_PhyResp_ICBAD_BKPCANFD";
BA_ "GenMsgSendType" BO_ 1853 1;
BA_ "GenMsgStartValue" BO_ 1853 "00000000000000000000000000000000000000000000000000000000000000000000000000000000000000000000000000000000000000000000000000000000";
BA_ "PduName" BO_ 1853 "Diag_BKPCANFD_PhyResp_ICBAD";
BA_ "VFrameFormat" BO_ 1853 14;
BA_ "FrameTriggeringName" BO_ 1001 "ECM_PTCANFD_100ms_FrP11";
BA_ "GenMsgCycleTime" BO_ 1001 100;
BA_ "GenMsgSendType" BO_ 1001 0;
BA_ "GenMsgStartValue" BO_ 1001 "00fffffff0ff0000";
BA_ "PduName" BO_ 1001 "ECM_100ms_PDU11";
BA_ "VFrameFormat" BO_ 1001 14;
BA_ "FrameTriggeringName" BO_ 1762 "FDR_BKBCANFD_EvtInfo";
BA_ "GenMsgSendType" BO_ 1762 1;
BA_ "GenMsgStartValue" BO_ 1762 "0000000000000000";
BA_ "PduName" BO_ 1762 "FDR_BKBCANFD_EvtInfo";
BA_ "VFrameFormat" BO_ 1762 14;
BA_ "FrameTriggeringName" BO_ 898 "FDR_BKPCANFD_100ms_FrP01";
BA_ "GenMsgCycleTime" BO_ 898 100;
BA_ "GenMsgSendType" BO_ 898 0;
BA_ "GenMsgStartValue" BO_ 898 "0010ffffffffffff";
BA_ "PduName" BO_ 898 "FDR_100ms_PDU01";
BA_ "VFrameFormat" BO_ 898 14;
BA_ "FrameTriggeringName" BO_ 1254 "FDR_BKPCANFD_NM";
BA_ "GenMsgSendType" BO_ 1254 1;
BA_ "GenMsgStartValue" BO_ 1254 "0000000000000000";
BA_ "PduName" BO_ 1254 "NmPDU_BKPCANFD_FDR";
BA_ "VFrameFormat" BO_ 1254 14;
BA_ "FrameTriggeringName" BO_ 139 "FDR_SecOC_ComKeyResp";
BA_ "GenMsgSendType" BO_ 139 1;
BA_ "GenMsgStartValue" BO_ 139 "0000000000000000";
BA_ "PduName" BO_ 139 "FDR_SecOCComKeyResp_PDU01";
BA_ "VFrameFormat" BO_ 139 14;
BA_ "FrameTriggeringName" BO_ 958 "FVCM_BKPCANFD_100ms_FrP04";
BA_ "GenMsgCycleTime" BO_ 958 100;
BA_ "GenMsgSendType" BO_ 958 0;
BA_ "GenMsgStartValue" BO_ 958 "00000000000000000000000000000000000000000000006000000000000000000000000000000000000000000000000000000000000000000000000000000000";
BA_ "PduName" BO_ 958 "FVCM_100ms_PDU04";
BA_ "VFrameFormat" BO_ 958 14;
BA_ "FrameTriggeringName" BO_ 956 "FVCM_BKPCANFD_100ms_FrP05";
BA_ "GenMsgCycleTime" BO_ 956 100;
BA_ "GenMsgSendType" BO_ 956 0;
BA_ "GenMsgStartValue" BO_ 956 "00000000000000000000000000000000000000000000000000000000000000000000000000000000000000000000000000500000000000000000000000000000";
BA_ "PduName" BO_ 956 "FVCM_100ms_PDU05";
BA_ "VFrameFormat" BO_ 956 14;
BA_ "FrameTriggeringName" BO_ 307 "FVCM_BKPCANFD_20ms_FrP02";
BA_ "GenMsgCycleTime" BO_ 307 20;
BA_ "GenMsgSendType" BO_ 307 0;
BA_ "GenMsgStartValue" BO_ 307 "00f0ffff00000163ffe00030a7ff07ff";
BA_ "PduName" BO_ 307 "FVCM_20ms_PDU02";
BA_ "VFrameFormat" BO_ 307 14;
BA_ "FrameTriggeringName" BO_ 747 "FVCM_BKPCANFD_50ms_FrP03";
BA_ "GenMsgCycleTime" BO_ 747 50;
BA_ "GenMsgSendType" BO_ 747 0;
BA_ "GenMsgStartValue" BO_ 747 "00003fffffffffffffffffff";
BA_ "PduName" BO_ 747 "FVCM_50ms_PDU03";
BA_ "VFrameFormat" BO_ 747 14;
BA_ "FrameTriggeringName" BO_ 1381 "IAM_BKPCANFD_1000ms_FrP49";
BA_ "GenMsgCycleTime" BO_ 1381 1000;
BA_ "GenMsgSendType" BO_ 1381 0;
BA_ "GenMsgStartValue" BO_ 1381 "0000000000000000";
BA_ "PduName" BO_ 1381 "IAM_ZONE_1000ms_PDU49";
BA_ "VFrameFormat" BO_ 1381 14;
BA_ "FrameTriggeringName" BO_ 1374 "IAM_BKPCANFD_1000ms_FrP55";
BA_ "GenMsgCycleTime" BO_ 1374 1000;
BA_ "GenMsgSendType" BO_ 1374 0;
BA_ "GenMsgStartValue" BO_ 1374 "0000000000000000";
BA_ "PduName" BO_ 1374 "IAM_ZONE_1000ms_PDU55";
BA_ "VFrameFormat" BO_ 1374 14;
BA_ "FrameTriggeringName" BO_ 1375 "IAM_BKPCANFD_1000ms_FrP58";
BA_ "GenMsgCycleTime" BO_ 1375 1000;
BA_ "GenMsgSendType" BO_ 1375 0;
BA_ "GenMsgStartValue" BO_ 1375 "0000000000000000";
BA_ "PduName" BO_ 1375 "IAM_ZONE_1000ms_PDU58";
BA_ "VFrameFormat" BO_ 1375 14;
BA_ "FrameTriggeringName" BO_ 1382 "IAM_BKPCANFD_1000ms_FrP59";
BA_ "GenMsgCycleTime" BO_ 1382 1000;
BA_ "GenMsgSendType" BO_ 1382 0;
BA_ "GenMsgStartValue" BO_ 1382 "0000000000000000";
BA_ "PduName" BO_ 1382 "IAM_ZONE_1000ms_PDU59";
BA_ "VFrameFormat" BO_ 1382 14;
BA_ "FrameTriggeringName" BO_ 1383 "IAM_BKPCANFD_1000ms_FrP60";
BA_ "GenMsgCycleTime" BO_ 1383 1000;
BA_ "GenMsgSendType" BO_ 1383 0;
BA_ "GenMsgStartValue" BO_ 1383 "0000000000000000";
BA_ "PduName" BO_ 1383 "IAM_ZONE_1000ms_PDU60";
BA_ "VFrameFormat" BO_ 1383 14;
BA_ "FrameTriggeringName" BO_ 1384 "IAM_BKPCANFD_1000ms_FrP61";
BA_ "GenMsgCycleTime" BO_ 1384 1000;
BA_ "GenMsgSendType" BO_ 1384 0;
BA_ "GenMsgStartValue" BO_ 1384 "0000000000000000";
BA_ "PduName" BO_ 1384 "IAM_ZONE_1000ms_PDU61";
BA_ "VFrameFormat" BO_ 1384 14;
BA_ "FrameTriggeringName" BO_ 1385 "IAM_BKPCANFD_1000ms_FrP62";
BA_ "GenMsgCycleTime" BO_ 1385 1000;
BA_ "GenMsgSendType" BO_ 1385 0;
BA_ "GenMsgStartValue" BO_ 1385 "0000000000000000";
BA_ "PduName" BO_ 1385 "IAM_ZONE_1000ms_PDU62";
BA_ "VFrameFormat" BO_ 1385 14;
BA_ "FrameTriggeringName" BO_ 1386 "IAM_BKPCANFD_1000ms_FrP63";
BA_ "GenMsgCycleTime" BO_ 1386 1000;
BA_ "GenMsgSendType" BO_ 1386 0;
BA_ "GenMsgStartValue" BO_ 1386 "0000000000000000";
BA_ "PduName" BO_ 1386 "IAM_ZONE_1000ms_PDU63";
BA_ "VFrameFormat" BO_ 1386 14;
BA_ "FrameTriggeringName" BO_ 1387 "IAM_BKPCANFD_1000ms_FrP64";
BA_ "GenMsgCycleTime" BO_ 1387 1000;
BA_ "GenMsgSendType" BO_ 1387 0;
BA_ "GenMsgStartValue" BO_ 1387 "0000000000000000";
BA_ "PduName" BO_ 1387 "IAM_ZONE_1000ms_PDU64";
BA_ "VFrameFormat" BO_ 1387 14;
BA_ "FrameTriggeringName" BO_ 1388 "IAM_BKPCANFD_1000ms_FrP65";
BA_ "GenMsgCycleTime" BO_ 1388 1000;
BA_ "GenMsgSendType" BO_ 1388 0;
BA_ "GenMsgStartValue" BO_ 1388 "0000000000000000";
BA_ "PduName" BO_ 1388 "IAM_ZONE_1000ms_PDU65";
BA_ "VFrameFormat" BO_ 1388 14;
BA_ "FrameTriggeringName" BO_ 1380 "IAM_BKPCANFD_1000ms_FrP66";
BA_ "GenMsgCycleTime" BO_ 1380 1000;
BA_ "GenMsgSendType" BO_ 1380 0;
BA_ "GenMsgStartValue" BO_ 1380 "0000000000000000";
BA_ "PduName" BO_ 1380 "IAM_ZONE_1000ms_PDU66";
BA_ "VFrameFormat" BO_ 1380 14;
BA_ "FrameTriggeringName" BO_ 298 "IAM_BKPCANFD_20ms_FrP10";
BA_ "GenMsgCycleTime" BO_ 298 20;
BA_ "GenMsgSendType" BO_ 298 0;
BA_ "GenMsgStartValue" BO_ 298 "0000000000000000";
BA_ "PduName" BO_ 298 "IAM_ZONE_20ms_PDU10";
BA_ "VFrameFormat" BO_ 298 14;
BA_ "FrameTriggeringName" BO_ 1082 "IAM_CONNCANFD_100ms_FrP03";
BA_ "GenMsgCycleTime" BO_ 1082 100;
BA_ "GenMsgSendType" BO_ 1082 0;
BA_ "GenMsgStartValue" BO_ 1082 "0000000000000000";
BA_ "PduName" BO_ 1082 "IAM_100ms_PDU03";
BA_ "VFrameFormat" BO_ 1082 14;
BA_ "FrameTriggeringName" BO_ 766 "IAM_CONNCANFD_100ms_FrP06";
BA_ "GenMsgCycleTime" BO_ 766 100;
BA_ "GenMsgSendType" BO_ 766 0;
BA_ "GenMsgStartValue" BO_ 766 "0000000000000000";
BA_ "PduName" BO_ 766 "IAM_100ms_PDU06";
BA_ "VFrameFormat" BO_ 766 14;
BA_ "FrameTriggeringName" BO_ 335 "IAM_CONNCANFD_100ms_FrP07";
BA_ "GenMsgCycleTime" BO_ 335 100;
BA_ "GenMsgSendType" BO_ 335 0;
BA_ "GenMsgStartValue" BO_ 335 "0000000000000000";
BA_ "PduName" BO_ 335 "IAM_100ms_PDU07";
BA_ "VFrameFormat" BO_ 335 14;
BA_ "FrameTriggeringName" BO_ 887 "IAM_CONNCANFD_100ms_FrP08";
BA_ "GenMsgCycleTime" BO_ 887 100;
BA_ "GenMsgSendType" BO_ 887 0;
BA_ "GenMsgStartValue" BO_ 887 "00f0000000000000";
BA_ "PduName" BO_ 887 "IAM_100ms_PDU08";
BA_ "VFrameFormat" BO_ 887 14;
BA_ "FrameTriggeringName" BO_ 700 "IAM_CONNCANFD_100ms_FrP19";
BA_ "GenMsgCycleTime" BO_ 700 100;
BA_ "GenMsgSendType" BO_ 700 0;
BA_ "GenMsgStartValue" BO_ 700 "0000000000000000000000000000000000000000000000000000000000000000";
BA_ "PduName" BO_ 700 "IAM_100ms_PDU19";
BA_ "VFrameFormat" BO_ 700 14;
BA_ "FrameTriggeringName" BO_ 912 "IAM_CONNCANFD_100ms_FrP34";
BA_ "GenMsgCycleTime" BO_ 912 100;
BA_ "GenMsgSendType" BO_ 912 0;
BA_ "GenMsgStartValue" BO_ 912 "00f0c000c000c000";
BA_ "PduName" BO_ 912 "IAM_ZONE_100ms_PDU34";
BA_ "VFrameFormat" BO_ 912 14;
BA_ "FrameTriggeringName" BO_ 874 "IAM_CONNCANFD_100ms_FrP40";
BA_ "GenMsgCycleTime" BO_ 874 100;
BA_ "GenMsgSendType" BO_ 874 0;
BA_ "GenMsgStartValue" BO_ 874 "00f00000000000ff";
BA_ "PduName" BO_ 874 "IAM_ZONE_100ms_PDU40";
BA_ "VFrameFormat" BO_ 874 14;
BA_ "FrameTriggeringName" BO_ 336 "IAM_CONNCANFD_20ms_FrP32";
BA_ "GenMsgCycleTime" BO_ 336 20;
BA_ "GenMsgSendType" BO_ 336 0;
BA_ "GenMsgStartValue" BO_ 336 "000000ffffffffffffffffffffffffff";
BA_ "PduName" BO_ 336 "IAM_20ms_PDU32";
BA_ "VFrameFormat" BO_ 336 14;
BA_ "FrameTriggeringName" BO_ 89 "IAM_CONNCANFD_Event_FrS04";
BA_ "GenMsgSendType" BO_ 89 1;
BA_ "GenMsgStartValue" BO_ 89 "00000000000000000000000000000000";
BA_ "PduName" BO_ 89 "IAM_Sporadic_PDU04";
BA_ "VFrameFormat" BO_ 89 14;
BA_ "FrameTriggeringName" BO_ 1000 "IAM_CONNCAN_100ms_FrP04";
BA_ "GenMsgCycleTime" BO_ 1000 100;
BA_ "GenMsgSendType" BO_ 1000 0;
BA_ "GenMsgStartValue" BO_ 1000 "0000000000000000";
BA_ "PduName" BO_ 1000 "IAM_100ms_PDU04";
BA_ "VFrameFormat" BO_ 1000 14;
BA_ "FrameTriggeringName" BO_ 811 "IAM_CONNCAN_100ms_FrP18";
BA_ "GenMsgCycleTime" BO_ 811 100;
BA_ "GenMsgSendType" BO_ 811 0;
BA_ "GenMsgStartValue" BO_ 811 "00f0000000000000";
BA_ "PduName" BO_ 811 "IAM_100ms_PDU18";
BA_ "VFrameFormat" BO_ 811 14;
BA_ "FrameTriggeringName" BO_ 1358 "IAM_CONNCAN_Event_FrS21";
BA_ "GenMsgSendType" BO_ 1358 1;
BA_ "GenMsgStartValue" BO_ 1358 "0000000000000000";
BA_ "PduName" BO_ 1358 "IAM_Sporadic_PDU21";
BA_ "VFrameFormat" BO_ 1358 14;
BA_ "FrameTriggeringName" BO_ 810 "IAM_RHBKBCANFD_100ms_FrP57";
BA_ "GenMsgCycleTime" BO_ 810 100;
BA_ "GenMsgSendType" BO_ 810 0;
BA_ "GenMsgStartValue" BO_ 810 "00f00000000000ff";
BA_ "PduName" BO_ 810 "IAM_ZONE_100ms_PDU57";
BA_ "VFrameFormat" BO_ 810 14;
BA_ "FrameTriggeringName" BO_ 793 "IAM_RZCUCANFD_100ms_FrP35";
BA_ "GenMsgCycleTime" BO_ 793 100;
BA_ "GenMsgSendType" BO_ 793 0;
BA_ "GenMsgStartValue" BO_ 793 "00f0000000000000";
BA_ "PduName" BO_ 793 "IAM_ZONE_100ms_PDU35";
BA_ "VFrameFormat" BO_ 793 14;
BA_ "FrameTriggeringName" BO_ 773 "IAM_ZONE_CONNCANFD_100ms_FrP03";
BA_ "GenMsgCycleTime" BO_ 773 100;
BA_ "GenMsgSendType" BO_ 773 0;
BA_ "GenMsgStartValue" BO_ 773 "0030000000000000";
BA_ "PduName" BO_ 773 "IAM_ZONE_100ms_PDU13";
BA_ "VFrameFormat" BO_ 773 14;
BA_ "FrameTriggeringName" BO_ 974 "IAM_ZONE_CONNCANFD_100ms_FrP56";
BA_ "GenMsgCycleTime" BO_ 974 100;
BA_ "GenMsgSendType" BO_ 974 0;
BA_ "GenMsgStartValue" BO_ 974 "00300000000000ff";
BA_ "PduName" BO_ 974 "IAM_ZONE_100ms_PDU56";
BA_ "VFrameFormat" BO_ 974 14;
BA_ "FrameTriggeringName" BO_ 179 "IAM_ZONE_CONNCANFD_Event_FrS01";
BA_ "GenMsgSendType" BO_ 179 1;
BA_ "GenMsgStartValue" BO_ 179 "000000000000000000000000000000000000000000000000000000000000000000000000000000000000000000000000";
BA_ "PduName" BO_ 179 "IAM_ZONE_Sporadic_PDU01";
BA_ "VFrameFormat" BO_ 179 14;
BA_ "FrameTriggeringName" BO_ 159 "IAM_ZONE_CONNCANFD_Event_FrS02";
BA_ "GenMsgSendType" BO_ 159 1;
BA_ "GenMsgStartValue" BO_ 159 "000000000000000000000000000000000000000000000000000000000000000000000000000000000000000000000000";
BA_ "PduName" BO_ 159 "IAM_ZONE_Sporadic_PDU02";
BA_ "VFrameFormat" BO_ 159 14;
BA_ "FrameTriggeringName" BO_ 125 "IAM_ZONE_CONNCANFD_Event_FrS03";
BA_ "GenMsgSendType" BO_ 125 1;
BA_ "GenMsgStartValue" BO_ 125 "00000000000000000000000000000000";
BA_ "PduName" BO_ 125 "IAM_ZONE_Sporadic_PDU03";
BA_ "VFrameFormat" BO_ 125 14;
BA_ "FrameTriggeringName" BO_ 348 "ICBAD_BKPCANFD_100ms_FrP27";
BA_ "GenMsgCycleTime" BO_ 348 100;
BA_ "GenMsgSendType" BO_ 348 0;
BA_ "GenMsgStartValue" BO_ 348 "004008020000000000001000";
BA_ "PduName" BO_ 348 "ICBAD_100ms_PDU27";
BA_ "VFrameFormat" BO_ 348 14;
BA_ "FrameTriggeringName" BO_ 917 "ICBAD_BKPCANFD_100ms_FrP29";
BA_ "GenMsgCycleTime" BO_ 917 100;
BA_ "GenMsgSendType" BO_ 917 0;
BA_ "GenMsgStartValue" BO_ 917 "000000000000000000000000";
BA_ "PduName" BO_ 917 "ICBAD_100ms_PDU29";
BA_ "VFrameFormat" BO_ 917 14;

BA_ "CompuMethodName" SG_ 1948 IDTCInfomationFDR "DTCInfomationFDR";
BA_ "ISignalName" SG_ 1948 IDTCInfomationFDR "IDTCInfomationFDR";
BA_ "LongName" SG_ 1948 IDTCInfomationFDR "Diagnostic Trouble Code Information FDR";
BA_ "SysSignalName" SG_ 1948 IDTCInfomationFDR "DTCInfomationFDR";
BA_ "CompuMethodName" SG_ 1949 IDTCInfomationIPD "DTCInfomationIPD";
BA_ "ISignalName" SG_ 1949 IDTCInfomationIPD "IDTCInfomationIPD";
BA_ "LongName" SG_ 1949 IDTCInfomationIPD "DTC Infomation IPD";
BA_ "SysSignalName" SG_ 1949 IDTCInfomationIPD "DTCInfomationIPD";
BA_ "CompuMethodName" SG_ 1319 IAIParkngSpcID "AIParkngSpcID";
BA_ "ISignalName" SG_ 1319 IAIParkngSpcID "IAIParkngSpcID";
BA_ "LongName" SG_ 1319 IAIParkngSpcID "AI_Parking_Space_ID";
BA_ "SysSignalName" SG_ 1319 IAIParkngSpcID "AIParkngSpcID";
BA_ "CompuMethodName" SG_ 1001 IEnClntTrtTem "EnClntTrtTem";
BA_ "ISignalName" SG_ 1001 IEnClntTrtTem "IEnClntTrtTem";
BA_ "LongName" SG_ 1001 IEnClntTrtTem "Engine Coolant Target Temp";
BA_ "SysSignalName" SG_ 1001 IEnClntTrtTem "EnClntTrtTem";
BA_ "CompuMethodName" SG_ 1001 IEPTClntPumpSta "EPTClntPumpSta";
BA_ "GenSigStartValue" SG_ 1001 IEPTClntPumpSta 15;
BA_ "ISignalName" SG_ 1001 IEPTClntPumpSta "IEPTClntPumpSta";
BA_ "LongName" SG_ 1001 IEPTClntPumpSta "EPT ClntPump Work Status";
BA_ "SysSignalName" SG_ 1001 IEPTClntPumpSta "EPTClntPumpSta";
BA_ "CompuMethodName" SG_ 1001 IESSClntPumpSta "ESSClntPumpSta";
BA_ "GenSigStartValue" SG_ 1001 IESSClntPumpSta 15;
BA_ "ISignalName" SG_ 1001 IESSClntPumpSta "IESSClntPumpSta";
BA_ "LongName" SG_ 1001 IESSClntPumpSta "ESSClntPump Work Status";
BA_ "SysSignalName" SG_ 1001 IESSClntPumpSta "ESSClntPumpSta";
BA_ "CompuMethodName" SG_ 1001 IEPTElecWtrPumpTrgtSpd "EPTElecWtrPumpTrgtSpd";
BA_ "GenSigStartValue" SG_ 1001 IEPTElecWtrPumpTrgtSpd 255;
BA_ "ISignalName" SG_ 1001 IEPTElecWtrPumpTrgtSpd "IEPTElecWtrPumpTrgtSpd";
BA_ "LongName" SG_ 1001 IEPTElecWtrPumpTrgtSpd "Ept Electric Water Pump Target Speed";
BA_ "SysSignalName" SG_ 1001 IEPTElecWtrPumpTrgtSpd "EPTElecWtrPumpTrgtSpd";
BA_ "CompuMethodName" SG_ 1001 IESSElecWtrPumpTrgtSpd "ESSElecWtrPumpTrgtSpd";
BA_ "GenSigStartValue" SG_ 1001 IESSElecWtrPumpTrgtSpd 255;
BA_ "ISignalName" SG_ 1001 IESSElecWtrPumpTrgtSpd "IESSElecWtrPumpTrgtSpd";
BA_ "LongName" SG_ 1001 IESSElecWtrPumpTrgtSpd "Ess Electric Water Pump Target Speed";
BA_ "SysSignalName" SG_ 1001 IESSElecWtrPumpTrgtSpd "ESSElecWtrPumpTrgtSpd";
BA_ "CompuMethodName" SG_ 1001 ICoolngFanWorkSta "CoolngFanWorkSta";
BA_ "GenSigStartValue" SG_ 1001 ICoolngFanWorkSta 15;
BA_ "ISignalName" SG_ 1001 ICoolngFanWorkSta "ICoolngFanWorkSta";
BA_ "LongName" SG_ 1001 ICoolngFanWorkSta "Cooling Fan Work Status";
BA_ "SysSignalName" SG_ 1001 ICoolngFanWorkSta "CoolngFanWorkSta";
BA_ "CompuMethodName" SG_ 1001 ILowTemWtrPumpTrgtSpd "LowTemWtrPumpTrgtSpd";
BA_ "GenSigStartValue" SG_ 1001 ILowTemWtrPumpTrgtSpd 255;
BA_ "ISignalName" SG_ 1001 ILowTemWtrPumpTrgtSpd "ILowTemWtrPumpTrgtSpd";
BA_ "LongName" SG_ 1001 ILowTemWtrPumpTrgtSpd "ECM Ept Electric Water Pump Target Speed";
BA_ "SysSignalName" SG_ 1001 ILowTemWtrPumpTrgtSpd "LowTemWtrPumpTrgtSpd";
BA_ "CompuMethodName" SG_ 1001 IEnSpdOBD "EnSpdOBD";
BA_ "ISignalName" SG_ 1001 IEnSpdOBD "IEnSpdOBD";
BA_ "LongName" SG_ 1001 IEnSpdOBD "Engine Speed On Board Diagnostics";
BA_ "SysSignalName" SG_ 1001 IEnSpdOBD "EnSpdOBD";
BA_ "CompuMethodName" SG_ 1762 IEvtPotclSigFDR "EvtPotclSigFDR";
BA_ "ISignalName" SG_ 1762 IEvtPotclSigFDR "IEvtPotclSigFDR";
BA_ "LongName" SG_ 1762 IEvtPotclSigFDR "Event_Protocol_Signal_FDR";
BA_ "SysSignalName" SG_ 1762 IEvtPotclSigFDR "EvtPotclSigFDR";
BA_ "CompuMethodName" SG_ 898 IFDR_100ms_Group01_CRC "FDR_100ms_Group01_CRC";
BA_ "ISignalName" SG_ 898 IFDR_100ms_Group01_CRC "IFDR_100ms_Group01_CRC";
BA_ "SysSignalName" SG_ 898 IFDR_100ms_Group01_CRC "FDR_100ms_Group01_CRC";
BA_ "CompuMethodName" SG_ 898 IFDR_100ms_Group01_RC "FDR_100ms_Group01_RC";
BA_ "ISignalName" SG_ 898 IFDR_100ms_Group01_RC "IFDR_100ms_Group01_RC";
BA_ "SysSignalName" SG_ 898 IFDR_100ms_Group01_RC "FDR_100ms_Group01_RC";
BA_ "CompuMethodName" SG_ 898 IFDR_100ms_Group01_Reserved1 "FDR_100ms_Group01_Reserved1";
BA_ "GenSigStartValue" SG_ 898 IFDR_100ms_Group01_Reserved1 1;
BA_ "ISignalName" SG_ 898 IFDR_100ms_Group01_Reserved1 "IFDR_100ms_Group01_Reserved1";
BA_ "SysSignalName" SG_ 898 IFDR_100ms_Group01_Reserved1 "FDR_100ms_Group01_Reserved1";
BA_ "CompuMethodName" SG_ 898 IFDRSts "FDRSts";
BA_ "ISignalName" SG_ 898 IFDRSts "IFDRSts";
BA_ "LongName" SG_ 898 IFDRSts "FDR Status";
BA_ "SysSignalName" SG_ 898 IFDRSts "FDRSts";
BA_ "CompuMethodName" SG_ 898 IFDR_100ms_Group01_Reserved2 "FDR_100ms_Group01_Reserved2";
BA_ "GenSigStartValue" SG_ 898 IFDR_100ms_Group01_Reserved2 255;
BA_ "ISignalName" SG_ 898 IFDR_100ms_Group01_Reserved2 "IFDR_100ms_Group01_Reserved2";
BA_ "SysSignalName" SG_ 898 IFDR_100ms_Group01_Reserved2 "FDR_100ms_Group01_Reserved2";
BA_ "CompuMethodName" SG_ 898 IFDR_100ms_Group01_Reserved3 "FDR_100ms_Group01_Reserved3";
BA_ "GenSigStartValue" SG_ 898 IFDR_100ms_Group01_Reserved3 255;
BA_ "ISignalName" SG_ 898 IFDR_100ms_Group01_Reserved3 "IFDR_100ms_Group01_Reserved3";
BA_ "SysSignalName" SG_ 898 IFDR_100ms_Group01_Reserved3 "FDR_100ms_Group01_Reserved3";
BA_ "CompuMethodName" SG_ 898 IFDR_100ms_Group01_Reserved4 "FDR_100ms_Group01_Reserved4";
BA_ "GenSigStartValue" SG_ 898 IFDR_100ms_Group01_Reserved4 255;
BA_ "ISignalName" SG_ 898 IFDR_100ms_Group01_Reserved4 "IFDR_100ms_Group01_Reserved4";
BA_ "SysSignalName" SG_ 898 IFDR_100ms_Group01_Reserved4 "FDR_100ms_Group01_Reserved4";
BA_ "CompuMethodName" SG_ 898 IFDR_100ms_Group01_Reserved5 "FDR_100ms_Group01_Reserved5";
BA_ "GenSigStartValue" SG_ 898 IFDR_100ms_Group01_Reserved5 255;
BA_ "ISignalName" SG_ 898 IFDR_100ms_Group01_Reserved5 "IFDR_100ms_Group01_Reserved5";
BA_ "SysSignalName" SG_ 898 IFDR_100ms_Group01_Reserved5 "FDR_100ms_Group01_Reserved5";
BA_ "CompuMethodName" SG_ 898 IFDR_100ms_Group01_Reserved6 "FDR_100ms_Group01_Reserved6";
BA_ "GenSigStartValue" SG_ 898 IFDR_100ms_Group01_Reserved6 255;
BA_ "ISignalName" SG_ 898 IFDR_100ms_Group01_Reserved6 "IFDR_100ms_Group01_Reserved6";
BA_ "SysSignalName" SG_ 898 IFDR_100ms_Group01_Reserved6 "FDR_100ms_Group01_Reserved6";
BA_ "CompuMethodName" SG_ 898 IFDR_100ms_Group01_Reserved7 "FDR_100ms_Group01_Reserved7";
BA_ "GenSigStartValue" SG_ 898 IFDR_100ms_Group01_Reserved7 255;
BA_ "ISignalName" SG_ 898 IFDR_100ms_Group01_Reserved7 "IFDR_100ms_Group01_Reserved7";
BA_ "SysSignalName" SG_ 898 IFDR_100ms_Group01_Reserved7 "FDR_100ms_Group01_Reserved7";
BA_ "CompuMethodName" SG_ 1254 IFDR_NM_BSMtoRMS_BKPCANFD "FDR_NM_BSMtoRMS_BKPCANFD";
BA_ "ISignalName" SG_ 1254 IFDR_NM_BSMtoRMS_BKPCANFD "IFDR_NM_BSMtoRMS_BKPCANFD";
BA_ "LongName" SG_ 1254 IFDR_NM_BSMtoRMS_BKPCANFD "FDR NM BSMtoRMS BKPCANFD";
BA_ "SysSignalName" SG_ 1254 IFDR_NM_BSMtoRMS_BKPCANFD "FDR_NM_BSMtoRMS_BKPCANFD";
BA_ "CompuMethodName" SG_ 1254 IFDR_NM_PBSMtoRMS_BKPCANFD "FDR_NM_PBSMtoRMS_BKPCANFD";
BA_ "ISignalName" SG_ 1254 IFDR_NM_PBSMtoRMS_BKPCANFD "IFDR_NM_PBSMtoRMS_BKPCANFD";
BA_ "LongName" SG_ 1254 IFDR_NM_PBSMtoRMS_BKPCANFD "FDR NM PBSMtoRMS BKPCANFD";
BA_ "SysSignalName" SG_ 1254 IFDR_NM_PBSMtoRMS_BKPCANFD "FDR_NM_PBSMtoRMS_BKPCANFD";
BA_ "CompuMethodName" SG_ 1254 IFDR_NM_RMStoNOS_BKPCANFD "FDR_NM_RMStoNOS_BKPCANFD";
BA_ "ISignalName" SG_ 1254 IFDR_NM_RMStoNOS_BKPCANFD "IFDR_NM_RMStoNOS_BKPCANFD";
BA_ "LongName" SG_ 1254 IFDR_NM_RMStoNOS_BKPCANFD "FDR NM RMStoNOS BKPCANFD";
BA_ "SysSignalName" SG_ 1254 IFDR_NM_RMStoNOS_BKPCANFD "FDR_NM_RMStoNOS_BKPCANFD";
BA_ "CompuMethodName" SG_ 1254 IFDR_NM_RSStoNOS_BKPCANFD "FDR_NM_RSStoNOS_BKPCANFD";
BA_ "ISignalName" SG_ 1254 IFDR_NM_RSStoNOS_BKPCANFD "IFDR_NM_RSStoNOS_BKPCANFD";
BA_ "LongName" SG_ 1254 IFDR_NM_RSStoNOS_BKPCANFD "FDR NM RSStoNOS BKPCANFD";
BA_ "SysSignalName" SG_ 1254 IFDR_NM_RSStoNOS_BKPCANFD "FDR_NM_RSStoNOS_BKPCANFD";
BA_ "CompuMethodName" SG_ 1254 IFDR_NM_RSStoRMS_BKPCANFD "FDR_NM_RSStoRMS_BKPCANFD";
BA_ "ISignalName" SG_ 1254 IFDR_NM_RSStoRMS_BKPCANFD "IFDR_NM_RSStoRMS_BKPCANFD";
BA_ "LongName" SG_ 1254 IFDR_NM_RSStoRMS_BKPCANFD "FDR NM RSStoRMS BKPCANFD";
BA_ "SysSignalName" SG_ 1254 IFDR_NM_RSStoRMS_BKPCANFD "FDR_NM_RSStoRMS_BKPCANFD";
BA_ "CompuMethodName" SG_ 1254 IFDR_NM_NOStoRMS_BKPCANFD "FDR_NM_NOStoRMS_BKPCANFD";
BA_ "ISignalName" SG_ 1254 IFDR_NM_NOStoRMS_BKPCANFD "IFDR_NM_NOStoRMS_BKPCANFD";
BA_ "LongName" SG_ 1254 IFDR_NM_NOStoRMS_BKPCANFD "FDR NM NOStoRMS BKPCANFD";
BA_ "SysSignalName" SG_ 1254 IFDR_NM_NOStoRMS_BKPCANFD "FDR_NM_NOStoRMS_BKPCANFD";
BA_ "CompuMethodName" SG_ 1254 IFDR_NM_NOSSta_BKPCANFD "FDR_NM_NOSSta_BKPCANFD";
BA_ "ISignalName" SG_ 1254 IFDR_NM_NOSSta_BKPCANFD "IFDR_NM_NOSSta_BKPCANFD";
BA_ "LongName" SG_ 1254 IFDR_NM_NOSSta_BKPCANFD "FDR NM NOSSta BKPCANFD";
BA_ "SysSignalName" SG_ 1254 IFDR_NM_NOSSta_BKPCANFD "FDR_NM_NOSSta_BKPCANFD";
BA_ "CompuMethodName" SG_ 1254 IFDR_NM_RMSSta_BKPCANFD "FDR_NM_RMSSta_BKPCANFD";
BA_ "ISignalName" SG_ 1254 IFDR_NM_RMSSta_BKPCANFD "IFDR_NM_RMSSta_BKPCANFD";
BA_ "LongName" SG_ 1254 IFDR_NM_RMSSta_BKPCANFD "FDR NM RMSSta BKPCANFD";
BA_ "SysSignalName" SG_ 1254 IFDR_NM_RMSSta_BKPCANFD "FDR_NM_RMSSta_BKPCANFD";
BA_ "CompuMethodName" SG_ 1254 IFDR_NWI_BKPCANFD "FDR_NWI_BKPCANFD";
BA_ "ISignalName" SG_ 1254 IFDR_NWI_BKPCANFD "IFDR_NWI_BKPCANFD";
BA_ "LongName" SG_ 1254 IFDR_NWI_BKPCANFD "FDR BKPCANFD Network_Wakeup_Indication";
BA_ "SysSignalName" SG_ 1254 IFDR_NWI_BKPCANFD "FDR_NWI_BKPCANFD";
BA_ "CompuMethodName" SG_ 1254 IFDR_NOI_BKPCANFD "FDR_NOI_BKPCANFD";
BA_ "ISignalName" SG_ 1254 IFDR_NOI_BKPCANFD "IFDR_NOI_BKPCANFD";
BA_ "LongName" SG_ 1254 IFDR_NOI_BKPCANFD "FDR BKPCANFD Network Operation Indication";
BA_ "SysSignalName" SG_ 1254 IFDR_NOI_BKPCANFD "FDR_NOI_BKPCANFD";
BA_ "CompuMethodName" SG_ 1254 IFDR_NKI_BKPCANFD "FDR_NKI_BKPCANFD";
BA_ "ISignalName" SG_ 1254 IFDR_NKI_BKPCANFD "IFDR_NKI_BKPCANFD";
BA_ "LongName" SG_ 1254 IFDR_NKI_BKPCANFD "Front Detection Radar Network Keep Indication";
BA_ "SysSignalName" SG_ 1254 IFDR_NKI_BKPCANFD "FDR_NKI_BKPCANFD";
BA_ "CompuMethodName" SG_ 139 IFDRTripCtrRstResp "FDRTripCtrRstResp";
BA_ "ISignalName" SG_ 139 IFDRTripCtrRstResp "IFDRTripCtrRstResp";
BA_ "LongName" SG_ 139 IFDRTripCtrRstResp "Fdr Trip Counter Reset Response";
BA_ "SysSignalName" SG_ 139 IFDRTripCtrRstResp "FDRTripCtrRstResp";
BA_ "CompuMethodName" SG_ 139 IFDRComKeyEnbResp "FDRComKeyEnbResp";
BA_ "ISignalName" SG_ 139 IFDRComKeyEnbResp "IFDRComKeyEnbResp";
BA_ "LongName" SG_ 139 IFDRComKeyEnbResp "Fdr Communication Key Enable Response";
BA_ "SysSignalName" SG_ 139 IFDRComKeyEnbResp "FDRComKeyEnbResp";
BA_ "CompuMethodName" SG_ 958 IACCConfmSw "ACCConfmSw";
BA_ "ISignalName" SG_ 958 IACCConfmSw "IACCConfmSw";
BA_ "LongName" SG_ 958 IACCConfmSw "ACC confirm  switch";
BA_ "SysSignalName" SG_ 958 IACCConfmSw "ACCConfmSw";
BA_ "CompuMethodName" SG_ 958 IELKWarning "ELKWarning";
BA_ "GenSigStartValue" SG_ 958 IELKWarning 6;
BA_ "ISignalName" SG_ 958 IELKWarning "IELKWarning";
BA_ "LongName" SG_ 958 IELKWarning "ELK Warning";
BA_ "SysSignalName" SG_ 958 IELKWarning "ELKWarning";
BA_ "CompuMethodName" SG_ 958 IACCDrvrTkovReq "ACCDrvrTkovReq";
BA_ "ISignalName" SG_ 958 IACCDrvrTkovReq "IACCDrvrTkovReq";
BA_ "LongName" SG_ 958 IACCDrvrTkovReq "Adaptive_Cruise_Control_Driver_Takeover_Request";
BA_ "SysSignalName" SG_ 958 IACCDrvrTkovReq "ACCDrvrTkovReq";
BA_ "CompuMethodName" SG_ 956 IPilotSysMsg "PilotSysMsg";
BA_ "ISignalName" SG_ 956 IPilotSysMsg "IPilotSysMsg";
BA_ "LongName" SG_ 956 IPilotSysMsg "Pilot System Message";
BA_ "SysSignalName" SG_ 956 IPilotSysMsg "PilotSysMsg";
BA_ "CompuMethodName" SG_ 956 ILane0_C0 "Lane0_C0";
BA_ "ISignalName" SG_ 956 ILane0_C0 "ILane0_C0";
BA_ "LongName" SG_ 956 ILane0_C0 "Lane_0_Curve_Parameter_C0";
BA_ "SysSignalName" SG_ 956 ILane0_C0 "Lane0_C0";
BA_ "CompuMethodName" SG_ 956 ILane0_C1 "Lane0_C1";
BA_ "ISignalName" SG_ 956 ILane0_C1 "ILane0_C1";
BA_ "LongName" SG_ 956 ILane0_C1 "Lane_0_Curve_Parameter_C1";
BA_ "SysSignalName" SG_ 956 ILane0_C1 "Lane0_C1";
BA_ "CompuMethodName" SG_ 956 ILane0_C2 "Lane0_C2";
BA_ "ISignalName" SG_ 956 ILane0_C2 "ILane0_C2";
BA_ "LongName" SG_ 956 ILane0_C2 "Lane_0_Curve_Parameter_C2";
BA_ "SysSignalName" SG_ 956 ILane0_C2 "Lane0_C2";
BA_ "CompuMethodName" SG_ 956 ILane0_C3 "Lane0_C3";
BA_ "ISignalName" SG_ 956 ILane0_C3 "ILane0_C3";
BA_ "LongName" SG_ 956 ILane0_C3 "Lane_0_Curve_Parameter_C3";
BA_ "SysSignalName" SG_ 956 ILane0_C3 "Lane0_C3";
BA_ "CompuMethodName" SG_ 956 ILane1_C0 "Lane1_C0";
BA_ "ISignalName" SG_ 956 ILane1_C0 "ILane1_C0";
BA_ "LongName" SG_ 956 ILane1_C0 "Lane_1_Curve_Parameter_C0";
BA_ "SysSignalName" SG_ 956 ILane1_C0 "Lane1_C0";
BA_ "CompuMethodName" SG_ 956 ILane1_C1 "Lane1_C1";
BA_ "ISignalName" SG_ 956 ILane1_C1 "ILane1_C1";
BA_ "LongName" SG_ 956 ILane1_C1 "Lane_1_Curve_Parameter_C1";
BA_ "SysSignalName" SG_ 956 ILane1_C1 "Lane1_C1";
BA_ "CompuMethodName" SG_ 956 ILane1_C2 "Lane1_C2";
BA_ "ISignalName" SG_ 956 ILane1_C2 "ILane1_C2";
BA_ "LongName" SG_ 956 ILane1_C2 "Lane_1_Curve_Parameter_C2";
BA_ "SysSignalName" SG_ 956 ILane1_C2 "Lane1_C2";
BA_ "CompuMethodName" SG_ 956 ILane1_C3 "Lane1_C3";
BA_ "ISignalName" SG_ 956 ILane1_C3 "ILane1_C3";
BA_ "LongName" SG_ 956 ILane1_C3 "Lane_1_Curve_Parameter_C3";
BA_ "SysSignalName" SG_ 956 ILane1_C3 "Lane1_C3";
BA_ "CompuMethodName" SG_ 956 ILane0_ViewRangeStart "Lane0_ViewRangeStart";
BA_ "ISignalName" SG_ 956 ILane0_ViewRangeStart "ILane0_ViewRangeStart";
BA_ "LongName" SG_ 956 ILane0_ViewRangeStart "Lane_0_Curve_Longitudinal_Distance_Start";
BA_ "SysSignalName" SG_ 956 ILane0_ViewRangeStart "Lane0_ViewRangeStart";
BA_ "CompuMethodName" SG_ 956 ILane1_ViewRangeStart "Lane1_ViewRangeStart";
BA_ "ISignalName" SG_ 956 ILane1_ViewRangeStart "ILane1_ViewRangeStart";
BA_ "LongName" SG_ 956 ILane1_ViewRangeStart "Lane_1_Curve_Longitudinal_Distance_Start";
BA_ "SysSignalName" SG_ 956 ILane1_ViewRangeStart "Lane1_ViewRangeStart";
BA_ "CompuMethodName" SG_ 956 ILane0_ViewRangeEnd "Lane0_ViewRangeEnd";
BA_ "ISignalName" SG_ 956 ILane0_ViewRangeEnd "ILane0_ViewRangeEnd";
BA_ "LongName" SG_ 956 ILane0_ViewRangeEnd "Lane_0_Curve_Longitudinal_Distance_Stop";
BA_ "SysSignalName" SG_ 956 ILane0_ViewRangeEnd "Lane0_ViewRangeEnd";
BA_ "CompuMethodName" SG_ 956 ILane1_ViewRangeEnd "Lane1_ViewRangeEnd";
BA_ "ISignalName" SG_ 956 ILane1_ViewRangeEnd "ILane1_ViewRangeEnd";
BA_ "LongName" SG_ 956 ILane1_ViewRangeEnd "Lane_1_Curve_Longitudinal_Distance_Stop";
BA_ "SysSignalName" SG_ 956 ILane1_ViewRangeEnd "Lane1_ViewRangeEnd";
BA_ "CompuMethodName" SG_ 956 ILane0_ExistPrblty "Lane0_ExistPrblty";
BA_ "ISignalName" SG_ 956 ILane0_ExistPrblty "ILane0_ExistPrblty";
BA_ "LongName" SG_ 956 ILane0_ExistPrblty "Lane_0_Exist_Probability";
BA_ "SysSignalName" SG_ 956 ILane0_ExistPrblty "Lane0_ExistPrblty";
BA_ "CompuMethodName" SG_ 956 ILane1_ExistPrblty "Lane1_ExistPrblty";
BA_ "ISignalName" SG_ 956 ILane1_ExistPrblty "ILane1_ExistPrblty";
BA_ "LongName" SG_ 956 ILane1_ExistPrblty "Lane_1_Exist_Probability";
BA_ "SysSignalName" SG_ 956 ILane1_ExistPrblty "Lane1_ExistPrblty";
BA_ "CompuMethodName" SG_ 956 ILane0_ID "Lane0_ID";
BA_ "ISignalName" SG_ 956 ILane0_ID "ILane0_ID";
BA_ "LongName" SG_ 956 ILane0_ID "Lane_0_Identifier";
BA_ "SysSignalName" SG_ 956 ILane0_ID "Lane0_ID";
BA_ "CompuMethodName" SG_ 956 ILane1_ID "Lane1_ID";
BA_ "ISignalName" SG_ 956 ILane1_ID "ILane1_ID";
BA_ "LongName" SG_ 956 ILane1_ID "Lane_1_Identifier";
BA_ "SysSignalName" SG_ 956 ILane1_ID "Lane1_ID";
BA_ "CompuMethodName" SG_ 956 ITLRMsgReq "TLRMsgReq";
BA_ "ISignalName" SG_ 956 ITLRMsgReq "ITLRMsgReq";
BA_ "LongName" SG_ 956 ITLRMsgReq "Traffic_lights_recognition_Message_Request";
BA_ "SysSignalName" SG_ 956 ITLRMsgReq "TLRMsgReq";
BA_ "CompuMethodName" SG_ 956 ILane0_location "Lane0_location";
BA_ "ISignalName" SG_ 956 ILane0_location "ILane0_location";
BA_ "LongName" SG_ 956 ILane0_location "Lane_0_Position";
BA_ "SysSignalName" SG_ 956 ILane0_location "Lane0_location";
BA_ "CompuMethodName" SG_ 956 ITLRSysSts "TLRSysSts";
BA_ "ISignalName" SG_ 956 ITLRSysSts "ITLRSysSts";
BA_ "LongName" SG_ 956 ITLRSysSts "Traffic_lights_recognition_System_Status";
BA_ "SysSignalName" SG_ 956 ITLRSysSts "TLRSysSts";
BA_ "CompuMethodName" SG_ 956 ILane1_location "Lane1_location";
BA_ "ISignalName" SG_ 956 ILane1_location "ILane1_location";
BA_ "LongName" SG_ 956 ILane1_location "Lane_1_Position";
BA_ "SysSignalName" SG_ 956 ILane1_location "Lane1_location";
BA_ "CompuMethodName" SG_ 956 ITrgtSpdSrcSts_IPD "TrgtSpdSrcSts_IPD";
BA_ "ISignalName" SG_ 956 ITrgtSpdSrcSts_IPD "ITrgtSpdSrcSts_IPD";
BA_ "LongName" SG_ 956 ITrgtSpdSrcSts_IPD "Target Speed Source Status";
BA_ "SysSignalName" SG_ 956 ITrgtSpdSrcSts_IPD "TrgtSpdSrcSts_IPD";
BA_ "CompuMethodName" SG_ 956 ISLIFWrnngMdResp "SLIFWrnngMdResp";
BA_ "ISignalName" SG_ 956 ISLIFWrnngMdResp "ISLIFWrnngMdResp";
BA_ "LongName" SG_ 956 ISLIFWrnngMdResp "Speed Limit Information Function Warning Mode Response";
BA_ "SysSignalName" SG_ 956 ISLIFWrnngMdResp "SLIFWrnngMdResp";
BA_ "CompuMethodName" SG_ 956 ITLRWarning "TLRWarning";
BA_ "ISignalName" SG_ 956 ITLRWarning "ITLRWarning";
BA_ "LongName" SG_ 956 ITLRWarning "Traffic_lights_recognition_Warning";
BA_ "SysSignalName" SG_ 956 ITLRWarning "TLRWarning";
BA_ "CompuMethodName" SG_ 956 ITLRMdSwDspCmd "TLRMdSwDspCmd";
BA_ "ISignalName" SG_ 956 ITLRMdSwDspCmd "ITLRMdSwDspCmd";
BA_ "LongName" SG_ 956 ITLRMdSwDspCmd "Traffic_lights_recognition_Mode_Switch_Display_Command";
BA_ "SysSignalName" SG_ 956 ITLRMdSwDspCmd "TLRMdSwDspCmd";
BA_ "CompuMethodName" SG_ 956 ISpdLmtOfstSetResp "SpdLmtOfstSetResp";
BA_ "GenSigStartValue" SG_ 956 ISpdLmtOfstSetResp 20;
BA_ "ISignalName" SG_ 956 ISpdLmtOfstSetResp "ISpdLmtOfstSetResp";
BA_ "LongName" SG_ 956 ISpdLmtOfstSetResp "Speed Limit Offset Set Response";
BA_ "SysSignalName" SG_ 956 ISpdLmtOfstSetResp "SpdLmtOfstSetResp";
BA_ "CompuMethodName" SG_ 956 ISLIFAudWrnng_IPD "SLIFAudWrnng_IPD";
BA_ "ISignalName" SG_ 956 ISLIFAudWrnng_IPD "ISLIFAudWrnng_IPD";
BA_ "LongName" SG_ 956 ISLIFAudWrnng_IPD "Speed Limit Information Function Audible Warning";
BA_ "SysSignalName" SG_ 956 ISLIFAudWrnng_IPD "SLIFAudWrnng_IPD";
BA_ "CompuMethodName" SG_ 956 ISLIFUpdtIndResp_IPD "SLIFUpdtIndResp_IPD";
BA_ "ISignalName" SG_ 956 ISLIFUpdtIndResp_IPD "ISLIFUpdtIndResp_IPD";
BA_ "LongName" SG_ 956 ISLIFUpdtIndResp_IPD "Speed Limit Information Function Update Indication Response";
BA_ "SysSignalName" SG_ 956 ISLIFUpdtIndResp_IPD "SLIFUpdtIndResp_IPD";
BA_ "CompuMethodName" SG_ 956 ISLIFUpdtInd_IPD "SLIFUpdtInd_IPD";
BA_ "ISignalName" SG_ 956 ISLIFUpdtInd_IPD "ISLIFUpdtInd_IPD";
BA_ "LongName" SG_ 956 ISLIFUpdtInd_IPD "Speed Limit Information Function Update Indication";
BA_ "SysSignalName" SG_ 956 ISLIFUpdtInd_IPD "SLIFUpdtInd_IPD";
BA_ "CompuMethodName" SG_ 956 ICCSpdVcCmdCnfm "CCSpdVcCmdCnfm";
BA_ "ISignalName" SG_ 956 ICCSpdVcCmdCnfm "ICCSpdVcCmdCnfm";
BA_ "LongName" SG_ 956 ICCSpdVcCmdCnfm "Cruise_Control_Speed_Voice_Command_Confirm";
BA_ "SysSignalName" SG_ 956 ICCSpdVcCmdCnfm "CCSpdVcCmdCnfm";
BA_ "CompuMethodName" SG_ 307 IFVCM_20ms_Group02_CRC "FVCM_20ms_Group02_CRC";
BA_ "ISignalName" SG_ 307 IFVCM_20ms_Group02_CRC "IFVCM_20ms_Group02_CRC";
BA_ "SysSignalName" SG_ 307 IFVCM_20ms_Group02_CRC "FVCM_20ms_Group02_CRC";
BA_ "CompuMethodName" SG_ 307 IFVCM_20ms_Group02_RC "FVCM_20ms_Group02_RC";
BA_ "ISignalName" SG_ 307 IFVCM_20ms_Group02_RC "IFVCM_20ms_Group02_RC";
BA_ "SysSignalName" SG_ 307 IFVCM_20ms_Group02_RC "FVCM_20ms_Group02_RC";
BA_ "CompuMethodName" SG_ 307 IFVCM_20ms_Group02_Reserved1 "FVCM_20ms_Group02_Reserved1";
BA_ "GenSigStartValue" SG_ 307 IFVCM_20ms_Group02_Reserved1 15;
BA_ "ISignalName" SG_ 307 IFVCM_20ms_Group02_Reserved1 "IFVCM_20ms_Group02_Reserved1";
BA_ "SysSignalName" SG_ 307 IFVCM_20ms_Group02_Reserved1 "FVCM_20ms_Group02_Reserved1";
BA_ "CompuMethodName" SG_ 307 IFVCM_20ms_Group02_Reserved2 "FVCM_20ms_Group02_Reserved2";
BA_ "GenSigStartValue" SG_ 307 IFVCM_20ms_Group02_Reserved2 255;
BA_ "ISignalName" SG_ 307 IFVCM_20ms_Group02_Reserved2 "IFVCM_20ms_Group02_Reserved2";
BA_ "SysSignalName" SG_ 307 IFVCM_20ms_Group02_Reserved2 "FVCM_20ms_Group02_Reserved2";
BA_ "CompuMethodName" SG_ 307 IFVCM_20ms_Group02_Reserved3 "FVCM_20ms_Group02_Reserved3";
BA_ "GenSigStartValue" SG_ 307 IFVCM_20ms_Group02_Reserved3 255;
BA_ "ISignalName" SG_ 307 IFVCM_20ms_Group02_Reserved3 "IFVCM_20ms_Group02_Reserved3";
BA_ "SysSignalName" SG_ 307 IFVCM_20ms_Group02_Reserved3 "FVCM_20ms_Group02_Reserved3";
BA_ "CompuMethodName" SG_ 307 IACCDrvrSelTrgtSpd "ACCDrvrSelTrgtSpd";
BA_ "ISignalName" SG_ 307 IACCDrvrSelTrgtSpd "IACCDrvrSelTrgtSpd";
BA_ "LongName" SG_ 307 IACCDrvrSelTrgtSpd "Adaptive_Cruise_Control_Driver_Select_Target_Speed";
BA_ "SysSignalName" SG_ 307 IACCDrvrSelTrgtSpd "ACCDrvrSelTrgtSpd";
BA_ "CompuMethodName" SG_ 307 IACCGoNotfr "ACCGoNotfr";
BA_ "ISignalName" SG_ 307 IACCGoNotfr "IACCGoNotfr";
BA_ "LongName" SG_ 307 IACCGoNotfr "Adaptive_Cruise_Control_Go_Notifier";
BA_ "SysSignalName" SG_ 307 IACCGoNotfr "ACCGoNotfr";
BA_ "CompuMethodName" SG_ 307 IFVCM_20ms_Group02_Reserved4 "FVCM_20ms_Group02_Reserved4";
BA_ "GenSigStartValue" SG_ 307 IFVCM_20ms_Group02_Reserved4 1;
BA_ "ISignalName" SG_ 307 IFVCM_20ms_Group02_Reserved4 "IFVCM_20ms_Group02_Reserved4";
BA_ "SysSignalName" SG_ 307 IFVCM_20ms_Group02_Reserved4 "FVCM_20ms_Group02_Reserved4";
BA_ "CompuMethodName" SG_ 307 IACCDetObjDistLvl "ACCDetObjDistLvl";
BA_ "ISignalName" SG_ 307 IACCDetObjDistLvl "IACCDetObjDistLvl";
BA_ "LongName" SG_ 307 IACCDetObjDistLvl "Adaptive Cruise Control Detected Object Distance Level";
BA_ "SysSignalName" SG_ 307 IACCDetObjDistLvl "ACCDetObjDistLvl";
BA_ "CompuMethodName" SG_ 307 IELKSysSts_IPD "ELKSysSts_IPD";
BA_ "ISignalName" SG_ 307 IELKSysSts_IPD "IELKSysSts_IPD";
BA_ "LongName" SG_ 307 IELKSysSts_IPD "ELK System status";
BA_ "SysSignalName" SG_ 307 IELKSysSts_IPD "ELKSysSts_IPD";
BA_ "CompuMethodName" SG_ 307 IFVCM_20ms_Group02_Reserved5 "FVCM_20ms_Group02_Reserved5";
BA_ "GenSigStartValue" SG_ 307 IFVCM_20ms_Group02_Reserved5 3;
BA_ "ISignalName" SG_ 307 IFVCM_20ms_Group02_Reserved5 "IFVCM_20ms_Group02_Reserved5";
BA_ "SysSignalName" SG_ 307 IFVCM_20ms_Group02_Reserved5 "FVCM_20ms_Group02_Reserved5";
BA_ "CompuMethodName" SG_ 307 IACCTJAMdSwDspCmd "ACCTJAMdSwDspCmd";
BA_ "ISignalName" SG_ 307 IACCTJAMdSwDspCmd "IACCTJAMdSwDspCmd";
BA_ "LongName" SG_ 307 IACCTJAMdSwDspCmd "Adaptive_Cruise_Control_Traffic_Jam_Assist_Mode_Switch_Display_Command";
BA_ "SysSignalName" SG_ 307 IACCTJAMdSwDspCmd "ACCTJAMdSwDspCmd";
BA_ "CompuMethodName" SG_ 307 IACCSeldTrgtDistLvl "ACCSeldTrgtDistLvl";
BA_ "GenSigStartValue" SG_ 307 IACCSeldTrgtDistLvl 3;
BA_ "ISignalName" SG_ 307 IACCSeldTrgtDistLvl "IACCSeldTrgtDistLvl";
BA_ "LongName" SG_ 307 IACCSeldTrgtDistLvl "Adaptive_Cruise_Control_Selected_Target_Distance_Level";
BA_ "SysSignalName" SG_ 307 IACCSeldTrgtDistLvl "ACCSeldTrgtDistLvl";
BA_ "CompuMethodName" SG_ 307 IFVCM_20ms_Group02_Reserved6 "FVCM_20ms_Group02_Reserved6";
BA_ "GenSigStartValue" SG_ 307 IFVCM_20ms_Group02_Reserved6 255;
BA_ "ISignalName" SG_ 307 IFVCM_20ms_Group02_Reserved6 "IFVCM_20ms_Group02_Reserved6";
BA_ "SysSignalName" SG_ 307 IFVCM_20ms_Group02_Reserved6 "FVCM_20ms_Group02_Reserved6";
BA_ "CompuMethodName" SG_ 307 IHandOffStrgWhlDetnSta "HandOffStrgWhlDetnSta";
BA_ "ISignalName" SG_ 307 IHandOffStrgWhlDetnSta "IHandOffStrgWhlDetnSta";
BA_ "LongName" SG_ 307 IHandOffStrgWhlDetnSta "Hand_Off_Steering_Wheel_Detection_State";
BA_ "SysSignalName" SG_ 307 IHandOffStrgWhlDetnSta "HandOffStrgWhlDetnSta";
BA_ "CompuMethodName" SG_ 307 IILCActvnDircnDspCmd "ILCActvnDircnDspCmd";
BA_ "ISignalName" SG_ 307 IILCActvnDircnDspCmd "IILCActvnDircnDspCmd";
BA_ "LongName" SG_ 307 IILCActvnDircnDspCmd "Intelligent_Lateral_Control_Activation_Direction_Display_Command";
BA_ "SysSignalName" SG_ 307 IILCActvnDircnDspCmd "ILCActvnDircnDspCmd";
BA_ "CompuMethodName" SG_ 307 IFVCM_20ms_Group02_Reserved7 "FVCM_20ms_Group02_Reserved7";
BA_ "GenSigStartValue" SG_ 307 IFVCM_20ms_Group02_Reserved7 7;
BA_ "ISignalName" SG_ 307 IFVCM_20ms_Group02_Reserved7 "IFVCM_20ms_Group02_Reserved7";
BA_ "SysSignalName" SG_ 307 IFVCM_20ms_Group02_Reserved7 "FVCM_20ms_Group02_Reserved7";
BA_ "CompuMethodName" SG_ 307 IILCSwDspCmd "ILCSwDspCmd";
BA_ "ISignalName" SG_ 307 IILCSwDspCmd "IILCSwDspCmd";
BA_ "LongName" SG_ 307 IILCSwDspCmd "Intelligent_Lateral_Control_Switch_Display_Command";
BA_ "SysSignalName" SG_ 307 IILCSwDspCmd "ILCSwDspCmd";
BA_ "CompuMethodName" SG_ 307 IILCSysSts "ILCSysSts";
BA_ "ISignalName" SG_ 307 IILCSysSts "IILCSysSts";
BA_ "LongName" SG_ 307 IILCSysSts "Intelligent_Lateral_Control_System_Status";
BA_ "SysSignalName" SG_ 307 IILCSysSts "ILCSysSts";
BA_ "CompuMethodName" SG_ 307 IILCActvnVelDspCmd "ILCActvnVelDspCmd";
BA_ "ISignalName" SG_ 307 IILCActvnVelDspCmd "IILCActvnVelDspCmd";
BA_ "LongName" SG_ 307 IILCActvnVelDspCmd "Intelligent_Longitudinal_Control_Activation_Velocity_Display_Command";
BA_ "SysSignalName" SG_ 307 IILCActvnVelDspCmd "ILCActvnVelDspCmd";
BA_ "CompuMethodName" SG_ 307 IHandOffStrgWhlDetnStaV "HandOffStrgWhlDetnStaV";
BA_ "ISignalName" SG_ 307 IHandOffStrgWhlDetnStaV "IHandOffStrgWhlDetnStaV";
BA_ "LongName" SG_ 307 IHandOffStrgWhlDetnStaV "Hand Off Steering Wheel Detection State Validity";
BA_ "SysSignalName" SG_ 307 IHandOffStrgWhlDetnStaV "HandOffStrgWhlDetnStaV";
BA_ "CompuMethodName" SG_ 307 ILDWLKAAudReq "LDWLKAAudReq";
BA_ "ISignalName" SG_ 307 ILDWLKAAudReq "ILDWLKAAudReq";
BA_ "LongName" SG_ 307 ILDWLKAAudReq "Lane_Departure_Warning_Lane_Keeping_Assist_Audible_Request";
BA_ "SysSignalName" SG_ 307 ILDWLKAAudReq "LDWLKAAudReq";
BA_ "CompuMethodName" SG_ 307 ILDWAdoWrnngDspCmd "LDWAdoWrnngDspCmd";
BA_ "GenSigStartValue" SG_ 307 ILDWAdoWrnngDspCmd 2;
BA_ "ISignalName" SG_ 307 ILDWAdoWrnngDspCmd "ILDWAdoWrnngDspCmd";
BA_ "LongName" SG_ 307 ILDWAdoWrnngDspCmd "Lane_Departure_Warning_Audio_Warning_Display_Command";
BA_ "SysSignalName" SG_ 307 ILDWAdoWrnngDspCmd "LDWAdoWrnngDspCmd";
BA_ "CompuMethodName" SG_ 307 ILDWLKADspCmd "LDWLKADspCmd";
BA_ "GenSigStartValue" SG_ 307 ILDWLKADspCmd 1;
BA_ "ISignalName" SG_ 307 ILDWLKADspCmd "ILDWLKADspCmd";
BA_ "LongName" SG_ 307 ILDWLKADspCmd "Lane_Departure_Warning_Lane_Keeping_Assist_Display_Command";
BA_ "SysSignalName" SG_ 307 ILDWLKADspCmd "LDWLKADspCmd";
BA_ "CompuMethodName" SG_ 307 IFVCM_20ms_Group02_Reserved8 "FVCM_20ms_Group02_Reserved8";
BA_ "GenSigStartValue" SG_ 307 IFVCM_20ms_Group02_Reserved8 7;
BA_ "ISignalName" SG_ 307 IFVCM_20ms_Group02_Reserved8 "IFVCM_20ms_Group02_Reserved8";
BA_ "SysSignalName" SG_ 307 IFVCM_20ms_Group02_Reserved8 "FVCM_20ms_Group02_Reserved8";
BA_ "CompuMethodName" SG_ 307 ILKADrvrTkovReq "LKADrvrTkovReq";
BA_ "ISignalName" SG_ 307 ILKADrvrTkovReq "ILKADrvrTkovReq";
BA_ "LongName" SG_ 307 ILKADrvrTkovReq "Lane_Keeping_Assist_Driver_Takeover_Request";
BA_ "SysSignalName" SG_ 307 ILKADrvrTkovReq "LKADrvrTkovReq";
BA_ "CompuMethodName" SG_ 307 ILDWSnstvtLvl "LDWSnstvtLvl";
BA_ "GenSigStartValue" SG_ 307 ILDWSnstvtLvl 2;
BA_ "ISignalName" SG_ 307 ILDWSnstvtLvl "ILDWSnstvtLvl";
BA_ "LongName" SG_ 307 ILDWSnstvtLvl "Lane_Departure_Warning_Sensitivity_Level";
BA_ "SysSignalName" SG_ 307 ILDWSnstvtLvl "LDWSnstvtLvl";
BA_ "CompuMethodName" SG_ 307 ILDWLKAHptWrnngDspCmd "LDWLKAHptWrnngDspCmd";
BA_ "GenSigStartValue" SG_ 307 ILDWLKAHptWrnngDspCmd 2;
BA_ "ISignalName" SG_ 307 ILDWLKAHptWrnngDspCmd "ILDWLKAHptWrnngDspCmd";
BA_ "LongName" SG_ 307 ILDWLKAHptWrnngDspCmd "Lane_Departure_Warning_Lane_Keeping_Assist_Haptic_Warning_Display_Command";
BA_ "SysSignalName" SG_ 307 ILDWLKAHptWrnngDspCmd "LDWLKAHptWrnngDspCmd";
BA_ "CompuMethodName" SG_ 307 IFVCM_20ms_Group02_Reserved9 "FVCM_20ms_Group02_Reserved9";
BA_ "GenSigStartValue" SG_ 307 IFVCM_20ms_Group02_Reserved9 255;
BA_ "ISignalName" SG_ 307 IFVCM_20ms_Group02_Reserved9 "IFVCM_20ms_Group02_Reserved9";
BA_ "SysSignalName" SG_ 307 IFVCM_20ms_Group02_Reserved9 "FVCM_20ms_Group02_Reserved9";
BA_ "CompuMethodName" SG_ 307 IFVCM_20ms_Group02_Reserved10 "FVCM_20ms_Group02_Reserved10";
BA_ "GenSigStartValue" SG_ 307 IFVCM_20ms_Group02_Reserved10 7;
BA_ "ISignalName" SG_ 307 IFVCM_20ms_Group02_Reserved10 "IFVCM_20ms_Group02_Reserved10";
BA_ "SysSignalName" SG_ 307 IFVCM_20ms_Group02_Reserved10 "FVCM_20ms_Group02_Reserved10";
BA_ "CompuMethodName" SG_ 307 IACCMsgReq "ACCMsgReq";
BA_ "ISignalName" SG_ 307 IACCMsgReq "IACCMsgReq";
BA_ "LongName" SG_ 307 IACCMsgReq "Adaptive_Cruise_Control_Message_Request";
BA_ "SysSignalName" SG_ 307 IACCMsgReq "ACCMsgReq";
BA_ "CompuMethodName" SG_ 307 IFVCM_20ms_Group02_Reserved11 "FVCM_20ms_Group02_Reserved11";
BA_ "GenSigStartValue" SG_ 307 IFVCM_20ms_Group02_Reserved11 255;
BA_ "ISignalName" SG_ 307 IFVCM_20ms_Group02_Reserved11 "IFVCM_20ms_Group02_Reserved11";
BA_ "SysSignalName" SG_ 307 IFVCM_20ms_Group02_Reserved11 "FVCM_20ms_Group02_Reserved11";
BA_ "CompuMethodName" SG_ 747 IFVCM_50ms_Group03_CRC "FVCM_50ms_Group03_CRC";
BA_ "ISignalName" SG_ 747 IFVCM_50ms_Group03_CRC "IFVCM_50ms_Group03_CRC";
BA_ "LongName" SG_ 747 IFVCM_50ms_Group03_CRC "FVCM_50ms_Group03_CRC";
BA_ "SysSignalName" SG_ 747 IFVCM_50ms_Group03_CRC "FVCM_50ms_Group03_CRC";
BA_ "CompuMethodName" SG_ 747 IFVCM_50ms_Group03_RC "FVCM_50ms_Group03_RC";
BA_ "ISignalName" SG_ 747 IFVCM_50ms_Group03_RC "IFVCM_50ms_Group03_RC";
BA_ "LongName" SG_ 747 IFVCM_50ms_Group03_RC "FVCM_50ms_Group03_RC";
BA_ "SysSignalName" SG_ 747 IFVCM_50ms_Group03_RC "FVCM_50ms_Group03_RC";
BA_ "CompuMethodName" SG_ 747 IKeepPwrRsnFVCM "KeepPwrRsnFVCM";
BA_ "ISignalName" SG_ 747 IKeepPwrRsnFVCM "IKeepPwrRsnFVCM";
BA_ "LongName" SG_ 747 IKeepPwrRsnFVCM "Keep Power Reason FVCM";
BA_ "SysSignalName" SG_ 747 IKeepPwrRsnFVCM "KeepPwrRsnFVCM";
BA_ "CompuMethodName" SG_ 747 IFVCM_50ms_Group03_Reserved1 "FVCM_50ms_Group03_Reserved1";
BA_ "GenSigStartValue" SG_ 747 IFVCM_50ms_Group03_Reserved1 63;
BA_ "ISignalName" SG_ 747 IFVCM_50ms_Group03_Reserved1 "IFVCM_50ms_Group03_Reserved1";
BA_ "SysSignalName" SG_ 747 IFVCM_50ms_Group03_Reserved1 "FVCM_50ms_Group03_Reserved1";
BA_ "CompuMethodName" SG_ 747 ITLRTrafficLightsCircleDsp "TLRTrafficLightsCircleDsp";
BA_ "ISignalName" SG_ 747 ITLRTrafficLightsCircleDsp "ITLRTrafficLightsCircleDsp";
BA_ "LongName" SG_ 747 ITLRTrafficLightsCircleDsp "Traffic_lights_status_circle_display";
BA_ "SysSignalName" SG_ 747 ITLRTrafficLightsCircleDsp "TLRTrafficLightsCircleDsp";
BA_ "CompuMethodName" SG_ 747 IFVCM_50ms_Group03_Reserved2 "FVCM_50ms_Group03_Reserved2";
BA_ "GenSigStartValue" SG_ 747 IFVCM_50ms_Group03_Reserved2 255;
BA_ "ISignalName" SG_ 747 IFVCM_50ms_Group03_Reserved2 "IFVCM_50ms_Group03_Reserved2";
BA_ "SysSignalName" SG_ 747 IFVCM_50ms_Group03_Reserved2 "FVCM_50ms_Group03_Reserved2";
BA_ "CompuMethodName" SG_ 747 IFVCM_50ms_Group03_Reserved3 "FVCM_50ms_Group03_Reserved3";
BA_ "GenSigStartValue" SG_ 747 IFVCM_50ms_Group03_Reserved3 255;
BA_ "ISignalName" SG_ 747 IFVCM_50ms_Group03_Reserved3 "IFVCM_50ms_Group03_Reserved3";
BA_ "SysSignalName" SG_ 747 IFVCM_50ms_Group03_Reserved3 "FVCM_50ms_Group03_Reserved3";
BA_ "CompuMethodName" SG_ 747 IFVCM_50ms_Group03_Reserved4 "FVCM_50ms_Group03_Reserved4";
BA_ "GenSigStartValue" SG_ 747 IFVCM_50ms_Group03_Reserved4 255;
BA_ "ISignalName" SG_ 747 IFVCM_50ms_Group03_Reserved4 "IFVCM_50ms_Group03_Reserved4";
BA_ "SysSignalName" SG_ 747 IFVCM_50ms_Group03_Reserved4 "FVCM_50ms_Group03_Reserved4";
BA_ "CompuMethodName" SG_ 747 IFVCM_50ms_Group03_Reserved5 "FVCM_50ms_Group03_Reserved5";
BA_ "GenSigStartValue" SG_ 747 IFVCM_50ms_Group03_Reserved5 255;
BA_ "ISignalName" SG_ 747 IFVCM_50ms_Group03_Reserved5 "IFVCM_50ms_Group03_Reserved5";
BA_ "SysSignalName" SG_ 747 IFVCM_50ms_Group03_Reserved5 "FVCM_50ms_Group03_Reserved5";
BA_ "CompuMethodName" SG_ 747 IFVCM_50ms_Group03_Reserved6 "FVCM_50ms_Group03_Reserved6";
BA_ "GenSigStartValue" SG_ 747 IFVCM_50ms_Group03_Reserved6 255;
BA_ "ISignalName" SG_ 747 IFVCM_50ms_Group03_Reserved6 "IFVCM_50ms_Group03_Reserved6";
BA_ "SysSignalName" SG_ 747 IFVCM_50ms_Group03_Reserved6 "FVCM_50ms_Group03_Reserved6";
BA_ "CompuMethodName" SG_ 747 IFVCM_50ms_Group03_Reserved7 "FVCM_50ms_Group03_Reserved7";
BA_ "GenSigStartValue" SG_ 747 IFVCM_50ms_Group03_Reserved7 255;
BA_ "ISignalName" SG_ 747 IFVCM_50ms_Group03_Reserved7 "IFVCM_50ms_Group03_Reserved7";
BA_ "SysSignalName" SG_ 747 IFVCM_50ms_Group03_Reserved7 "FVCM_50ms_Group03_Reserved7";
BA_ "CompuMethodName" SG_ 747 IFVCM_50ms_Group03_Reserved8 "FVCM_50ms_Group03_Reserved8";
BA_ "GenSigStartValue" SG_ 747 IFVCM_50ms_Group03_Reserved8 255;
BA_ "ISignalName" SG_ 747 IFVCM_50ms_Group03_Reserved8 "IFVCM_50ms_Group03_Reserved8";
BA_ "SysSignalName" SG_ 747 IFVCM_50ms_Group03_Reserved8 "FVCM_50ms_Group03_Reserved8";
BA_ "CompuMethodName" SG_ 747 IFVCM_50ms_Group03_Reserved9 "FVCM_50ms_Group03_Reserved9";
BA_ "GenSigStartValue" SG_ 747 IFVCM_50ms_Group03_Reserved9 255;
BA_ "ISignalName" SG_ 747 IFVCM_50ms_Group03_Reserved9 "IFVCM_50ms_Group03_Reserved9";
BA_ "SysSignalName" SG_ 747 IFVCM_50ms_Group03_Reserved9 "FVCM_50ms_Group03_Reserved9";
BA_ "CompuMethodName" SG_ 747 IFVCM_50ms_Group03_Reserved10 "FVCM_50ms_Group03_Reserved10";
BA_ "GenSigStartValue" SG_ 747 IFVCM_50ms_Group03_Reserved10 255;
BA_ "ISignalName" SG_ 747 IFVCM_50ms_Group03_Reserved10 "IFVCM_50ms_Group03_Reserved10";
BA_ "SysSignalName" SG_ 747 IFVCM_50ms_Group03_Reserved10 "FVCM_50ms_Group03_Reserved10";
BA_ "CompuMethodName" SG_ 1381 ISatAz5 "SatAz5";
BA_ "ISignalName" SG_ 1381 ISatAz5 "ISatAz5";
BA_ "LongName" SG_ 1381 ISatAz5 "Satellite5 Azimuth Angle";
BA_ "SysSignalName" SG_ 1381 ISatAz5 "SatAz5";
BA_ "CompuMethodName" SG_ 1381 ISatCNO5 "SatCNO5";
BA_ "ISignalName" SG_ 1381 ISatCNO5 "ISatCNO5";
BA_ "LongName" SG_ 1381 ISatCNO5 "Satellite5 Cno";
BA_ "SysSignalName" SG_ 1381 ISatCNO5 "SatCNO5";
BA_ "CompuMethodName" SG_ 1381 ISatElv5 "SatElv5";
BA_ "ISignalName" SG_ 1381 ISatElv5 "ISatElv5";
BA_ "LongName" SG_ 1381 ISatElv5 "Satellite5 Elevation Angle";
BA_ "SysSignalName" SG_ 1381 ISatElv5 "SatElv5";
BA_ "CompuMethodName" SG_ 1381 ISatAz6 "SatAz6";
BA_ "ISignalName" SG_ 1381 ISatAz6 "ISatAz6";
BA_ "LongName" SG_ 1381 ISatAz6 "Satellite6 Azimuth Angle";
BA_ "SysSignalName" SG_ 1381 ISatAz6 "SatAz6";
BA_ "CompuMethodName" SG_ 1381 ISatID5 "SatID5";
BA_ "ISignalName" SG_ 1381 ISatID5 "ISatID5";
BA_ "LongName" SG_ 1381 ISatID5 "Satellite5 Id";
BA_ "SysSignalName" SG_ 1381 ISatID5 "SatID5";
BA_ "CompuMethodName" SG_ 1381 ISatCNO6 "SatCNO6";
BA_ "ISignalName" SG_ 1381 ISatCNO6 "ISatCNO6";
BA_ "LongName" SG_ 1381 ISatCNO6 "Satellite6 Cno";
BA_ "SysSignalName" SG_ 1381 ISatCNO6 "SatCNO6";
BA_ "CompuMethodName" SG_ 1381 ISatElv6 "SatElv6";
BA_ "ISignalName" SG_ 1381 ISatElv6 "ISatElv6";
BA_ "LongName" SG_ 1381 ISatElv6 "Satellite6 Elevation Angle";
BA_ "SysSignalName" SG_ 1381 ISatElv6 "SatElv6";
BA_ "CompuMethodName" SG_ 1381 ISatID6 "SatID6";
BA_ "ISignalName" SG_ 1381 ISatID6 "ISatID6";
BA_ "LongName" SG_ 1381 ISatID6 "Satellite6 Id";
BA_ "SysSignalName" SG_ 1381 ISatID6 "SatID6";
BA_ "CompuMethodName" SG_ 1374 ISatAz1 "SatAz1";
BA_ "ISignalName" SG_ 1374 ISatAz1 "ISatAz1";
BA_ "LongName" SG_ 1374 ISatAz1 "Satellite1 Azimuth Angle";
BA_ "SysSignalName" SG_ 1374 ISatAz1 "SatAz1";
BA_ "CompuMethodName" SG_ 1374 ISatCNO1 "SatCNO1";
BA_ "ISignalName" SG_ 1374 ISatCNO1 "ISatCNO1";
BA_ "LongName" SG_ 1374 ISatCNO1 "Satellite1 Cno";
BA_ "SysSignalName" SG_ 1374 ISatCNO1 "SatCNO1";
BA_ "CompuMethodName" SG_ 1374 ISatElv1 "SatElv1";
BA_ "ISignalName" SG_ 1374 ISatElv1 "ISatElv1";
BA_ "LongName" SG_ 1374 ISatElv1 "Satellite1 Elevation Angle";
BA_ "SysSignalName" SG_ 1374 ISatElv1 "SatElv1";
BA_ "CompuMethodName" SG_ 1374 ISatAz2 "SatAz2";
BA_ "ISignalName" SG_ 1374 ISatAz2 "ISatAz2";
BA_ "LongName" SG_ 1374 ISatAz2 "Satellite2 Azimuth Angle";
BA_ "SysSignalName" SG_ 1374 ISatAz2 "SatAz2";
BA_ "CompuMethodName" SG_ 1374 ISatID1 "SatID1";
BA_ "ISignalName" SG_ 1374 ISatID1 "ISatID1";
BA_ "LongName" SG_ 1374 ISatID1 "Satellite1 Id";
BA_ "SysSignalName" SG_ 1374 ISatID1 "SatID1";
BA_ "CompuMethodName" SG_ 1374 ISatCNO2 "SatCNO2";
BA_ "ISignalName" SG_ 1374 ISatCNO2 "ISatCNO2";
BA_ "LongName" SG_ 1374 ISatCNO2 "Satellite2 Cno";
BA_ "SysSignalName" SG_ 1374 ISatCNO2 "SatCNO2";
BA_ "CompuMethodName" SG_ 1374 ISatElv2 "SatElv2";
BA_ "ISignalName" SG_ 1374 ISatElv2 "ISatElv2";
BA_ "LongName" SG_ 1374 ISatElv2 "Satellite2 Elevation Angle";
BA_ "SysSignalName" SG_ 1374 ISatElv2 "SatElv2";
BA_ "CompuMethodName" SG_ 1374 ISatID2 "SatID2";
BA_ "ISignalName" SG_ 1374 ISatID2 "ISatID2";
BA_ "LongName" SG_ 1374 ISatID2 "Satellite2 Id";
BA_ "SysSignalName" SG_ 1374 ISatID2 "SatID2";
BA_ "CompuMethodName" SG_ 1375 ISatAz17 "SatAz17";
BA_ "ISignalName" SG_ 1375 ISatAz17 "ISatAz17";
BA_ "LongName" SG_ 1375 ISatAz17 "Satellite17 Azimuth Angle";
BA_ "SysSignalName" SG_ 1375 ISatAz17 "SatAz17";
BA_ "CompuMethodName" SG_ 1375 ISatCNO17 "SatCNO17";
BA_ "ISignalName" SG_ 1375 ISatCNO17 "ISatCNO17";
BA_ "LongName" SG_ 1375 ISatCNO17 "Satellite17 Cno";
BA_ "SysSignalName" SG_ 1375 ISatCNO17 "SatCNO17";
BA_ "CompuMethodName" SG_ 1375 ISatElv17 "SatElv17";
BA_ "ISignalName" SG_ 1375 ISatElv17 "ISatElv17";
BA_ "LongName" SG_ 1375 ISatElv17 "Satellite17 Elevation Angle";
BA_ "SysSignalName" SG_ 1375 ISatElv17 "SatElv17";
BA_ "CompuMethodName" SG_ 1375 ISatAz18 "SatAz18";
BA_ "ISignalName" SG_ 1375 ISatAz18 "ISatAz18";
BA_ "LongName" SG_ 1375 ISatAz18 "Satellite18 Azimuth Angle";
BA_ "SysSignalName" SG_ 1375 ISatAz18 "SatAz18";
BA_ "CompuMethodName" SG_ 1375 ISatID17 "SatID17";
BA_ "ISignalName" SG_ 1375 ISatID17 "ISatID17";
BA_ "LongName" SG_ 1375 ISatID17 "Satellite17 Id";
BA_ "SysSignalName" SG_ 1375 ISatID17 "SatID17";
BA_ "CompuMethodName" SG_ 1375 ISatCNO18 "SatCNO18";
BA_ "ISignalName" SG_ 1375 ISatCNO18 "ISatCNO18";
BA_ "LongName" SG_ 1375 ISatCNO18 "Satellite18 Cno";
BA_ "SysSignalName" SG_ 1375 ISatCNO18 "SatCNO18";
BA_ "CompuMethodName" SG_ 1375 ISatElv18 "SatElv18";
BA_ "ISignalName" SG_ 1375 ISatElv18 "ISatElv18";
BA_ "LongName" SG_ 1375 ISatElv18 "Satellite18 Elevation Angle";
BA_ "SysSignalName" SG_ 1375 ISatElv18 "SatElv18";
BA_ "CompuMethodName" SG_ 1375 ISatID18 "SatID18";
BA_ "ISignalName" SG_ 1375 ISatID18 "ISatID18";
BA_ "LongName" SG_ 1375 ISatID18 "Satellite18 Id";
BA_ "SysSignalName" SG_ 1375 ISatID18 "SatID18";
BA_ "CompuMethodName" SG_ 1382 ISatAz7 "SatAz7";
BA_ "ISignalName" SG_ 1382 ISatAz7 "ISatAz7";
BA_ "LongName" SG_ 1382 ISatAz7 "Satellite7 Azimuth Angle";
BA_ "SysSignalName" SG_ 1382 ISatAz7 "SatAz7";
BA_ "CompuMethodName" SG_ 1382 ISatCNO7 "SatCNO7";
BA_ "ISignalName" SG_ 1382 ISatCNO7 "ISatCNO7";
BA_ "LongName" SG_ 1382 ISatCNO7 "Satellite7 Cno";
BA_ "SysSignalName" SG_ 1382 ISatCNO7 "SatCNO7";
BA_ "CompuMethodName" SG_ 1382 ISatElv7 "SatElv7";
BA_ "ISignalName" SG_ 1382 ISatElv7 "ISatElv7";
BA_ "LongName" SG_ 1382 ISatElv7 "Satellite7 Elevation Angle";
BA_ "SysSignalName" SG_ 1382 ISatElv7 "SatElv7";
BA_ "CompuMethodName" SG_ 1382 ISatAz8 "SatAz8";
BA_ "ISignalName" SG_ 1382 ISatAz8 "ISatAz8";
BA_ "LongName" SG_ 1382 ISatAz8 "Satellite8 Azimuth Angle";
BA_ "SysSignalName" SG_ 1382 ISatAz8 "SatAz8";
BA_ "CompuMethodName" SG_ 1382 ISatID7 "SatID7";
BA_ "ISignalName" SG_ 1382 ISatID7 "ISatID7";
BA_ "LongName" SG_ 1382 ISatID7 "Satellite7 Id";
BA_ "SysSignalName" SG_ 1382 ISatID7 "SatID7";
BA_ "CompuMethodName" SG_ 1382 ISatCNO8 "SatCNO8";
BA_ "ISignalName" SG_ 1382 ISatCNO8 "ISatCNO8";
BA_ "LongName" SG_ 1382 ISatCNO8 "Satellite8 Cno";
BA_ "SysSignalName" SG_ 1382 ISatCNO8 "SatCNO8";
BA_ "CompuMethodName" SG_ 1382 ISatElv8 "SatElv8";
BA_ "ISignalName" SG_ 1382 ISatElv8 "ISatElv8";
BA_ "LongName" SG_ 1382 ISatElv8 "Satellite8 Elevation Angle";
BA_ "SysSignalName" SG_ 1382 ISatElv8 "SatElv8";
BA_ "CompuMethodName" SG_ 1382 ISatID8 "SatID8";
BA_ "ISignalName" SG_ 1382 ISatID8 "ISatID8";
BA_ "LongName" SG_ 1382 ISatID8 "Satellite8 Id";
BA_ "SysSignalName" SG_ 1382 ISatID8 "SatID8";
BA_ "CompuMethodName" SG_ 1383 ISatAz9 "SatAz9";
BA_ "ISignalName" SG_ 1383 ISatAz9 "ISatAz9";
BA_ "LongName" SG_ 1383 ISatAz9 "Satellite9 Azimuth Angle";
BA_ "SysSignalName" SG_ 1383 ISatAz9 "SatAz9";
BA_ "CompuMethodName" SG_ 1383 ISatCNO9 "SatCNO9";
BA_ "ISignalName" SG_ 1383 ISatCNO9 "ISatCNO9";
BA_ "LongName" SG_ 1383 ISatCNO9 "Satellite9 Cno";
BA_ "SysSignalName" SG_ 1383 ISatCNO9 "SatCNO9";
BA_ "CompuMethodName" SG_ 1383 ISatElv9 "SatElv9";
BA_ "ISignalName" SG_ 1383 ISatElv9 "ISatElv9";
BA_ "LongName" SG_ 1383 ISatElv9 "Satellite9 Elevation Angle";
BA_ "SysSignalName" SG_ 1383 ISatElv9 "SatElv9";
BA_ "CompuMethodName" SG_ 1383 ISatAz10 "SatAz10";
BA_ "ISignalName" SG_ 1383 ISatAz10 "ISatAz10";
BA_ "LongName" SG_ 1383 ISatAz10 "Satellite10 Azimuth Angle";
BA_ "SysSignalName" SG_ 1383 ISatAz10 "SatAz10";
BA_ "CompuMethodName" SG_ 1383 ISatID9 "SatID9";
BA_ "ISignalName" SG_ 1383 ISatID9 "ISatID9";
BA_ "LongName" SG_ 1383 ISatID9 "Satellite9 Id";
BA_ "SysSignalName" SG_ 1383 ISatID9 "SatID9";
BA_ "CompuMethodName" SG_ 1383 ISatCNO10 "SatCNO10";
BA_ "ISignalName" SG_ 1383 ISatCNO10 "ISatCNO10";
BA_ "LongName" SG_ 1383 ISatCNO10 "Satellite10 Cno";
BA_ "SysSignalName" SG_ 1383 ISatCNO10 "SatCNO10";
BA_ "CompuMethodName" SG_ 1383 ISatElv10 "SatElv10";
BA_ "ISignalName" SG_ 1383 ISatElv10 "ISatElv10";
BA_ "LongName" SG_ 1383 ISatElv10 "Satellite10 Elevation Angle";
BA_ "SysSignalName" SG_ 1383 ISatElv10 "SatElv10";
BA_ "CompuMethodName" SG_ 1383 ISatID10 "SatID10";
BA_ "ISignalName" SG_ 1383 ISatID10 "ISatID10";
BA_ "LongName" SG_ 1383 ISatID10 "Satellite10 Id";
BA_ "SysSignalName" SG_ 1383 ISatID10 "SatID10";
BA_ "CompuMethodName" SG_ 1384 ISatAz11 "SatAz11";
BA_ "ISignalName" SG_ 1384 ISatAz11 "ISatAz11";
BA_ "LongName" SG_ 1384 ISatAz11 "Satellite11 Azimuth Angle";
BA_ "SysSignalName" SG_ 1384 ISatAz11 "SatAz11";
BA_ "CompuMethodName" SG_ 1384 ISatCNO11 "SatCNO11";
BA_ "ISignalName" SG_ 1384 ISatCNO11 "ISatCNO11";
BA_ "LongName" SG_ 1384 ISatCNO11 "Satellite11 Cno";
BA_ "SysSignalName" SG_ 1384 ISatCNO11 "SatCNO11";
BA_ "CompuMethodName" SG_ 1384 ISatElv11 "SatElv11";
BA_ "ISignalName" SG_ 1384 ISatElv11 "ISatElv11";
BA_ "LongName" SG_ 1384 ISatElv11 "Satellite11 Elevation Angle";
BA_ "SysSignalName" SG_ 1384 ISatElv11 "SatElv11";
BA_ "CompuMethodName" SG_ 1384 ISatAz12 "SatAz12";
BA_ "ISignalName" SG_ 1384 ISatAz12 "ISatAz12";
BA_ "LongName" SG_ 1384 ISatAz12 "Satellite12 Azimuth Angle";
BA_ "SysSignalName" SG_ 1384 ISatAz12 "SatAz12";
BA_ "CompuMethodName" SG_ 1384 ISatID11 "SatID11";
BA_ "ISignalName" SG_ 1384 ISatID11 "ISatID11";
BA_ "LongName" SG_ 1384 ISatID11 "Satellite11 Id";
BA_ "SysSignalName" SG_ 1384 ISatID11 "SatID11";
BA_ "CompuMethodName" SG_ 1384 ISatCNO12 "SatCNO12";
BA_ "ISignalName" SG_ 1384 ISatCNO12 "ISatCNO12";
BA_ "LongName" SG_ 1384 ISatCNO12 "Satellite12 Cno";
BA_ "SysSignalName" SG_ 1384 ISatCNO12 "SatCNO12";
BA_ "CompuMethodName" SG_ 1384 ISatElv12 "SatElv12";
BA_ "ISignalName" SG_ 1384 ISatElv12 "ISatElv12";
BA_ "LongName" SG_ 1384 ISatElv12 "Satellite12 Elevation Angle";
BA_ "SysSignalName" SG_ 1384 ISatElv12 "SatElv12";
BA_ "CompuMethodName" SG_ 1384 ISatID12 "SatID12";
BA_ "ISignalName" SG_ 1384 ISatID12 "ISatID12";
BA_ "LongName" SG_ 1384 ISatID12 "Satellite12 Id";
BA_ "SysSignalName" SG_ 1384 ISatID12 "SatID12";
BA_ "CompuMethodName" SG_ 1385 ISatAz13 "SatAz13";
BA_ "ISignalName" SG_ 1385 ISatAz13 "ISatAz13";
BA_ "LongName" SG_ 1385 ISatAz13 "Satellite13 Azimuth Angle";
BA_ "SysSignalName" SG_ 1385 ISatAz13 "SatAz13";
BA_ "CompuMethodName" SG_ 1385 ISatCNO13 "SatCNO13";
BA_ "ISignalName" SG_ 1385 ISatCNO13 "ISatCNO13";
BA_ "LongName" SG_ 1385 ISatCNO13 "Satellite13 Cno";
BA_ "SysSignalName" SG_ 1385 ISatCNO13 "SatCNO13";
BA_ "CompuMethodName" SG_ 1385 ISatElv13 "SatElv13";
BA_ "ISignalName" SG_ 1385 ISatElv13 "ISatElv13";
BA_ "LongName" SG_ 1385 ISatElv13 "Satellite13 Elevation Angle";
BA_ "SysSignalName" SG_ 1385 ISatElv13 "SatElv13";
BA_ "CompuMethodName" SG_ 1385 ISatAz14 "SatAz14";
BA_ "ISignalName" SG_ 1385 ISatAz14 "ISatAz14";
BA_ "LongName" SG_ 1385 ISatAz14 "Satellite14 Azimuth Angle";
BA_ "SysSignalName" SG_ 1385 ISatAz14 "SatAz14";
BA_ "CompuMethodName" SG_ 1385 ISatID13 "SatID13";
BA_ "ISignalName" SG_ 1385 ISatID13 "ISatID13";
BA_ "LongName" SG_ 1385 ISatID13 "Satellite13 Id";
BA_ "SysSignalName" SG_ 1385 ISatID13 "SatID13";
BA_ "CompuMethodName" SG_ 1385 ISatCNO14 "SatCNO14";
BA_ "ISignalName" SG_ 1385 ISatCNO14 "ISatCNO14";
BA_ "LongName" SG_ 1385 ISatCNO14 "Satellite14 Cno";
BA_ "SysSignalName" SG_ 1385 ISatCNO14 "SatCNO14";
BA_ "CompuMethodName" SG_ 1385 ISatElv14 "SatElv14";
BA_ "ISignalName" SG_ 1385 ISatElv14 "ISatElv14";
BA_ "LongName" SG_ 1385 ISatElv14 "Satellite14 Elevation Angle";
BA_ "SysSignalName" SG_ 1385 ISatElv14 "SatElv14";
BA_ "CompuMethodName" SG_ 1385 ISatID14 "SatID14";
BA_ "ISignalName" SG_ 1385 ISatID14 "ISatID14";
BA_ "LongName" SG_ 1385 ISatID14 "Satellite14 Id";
BA_ "SysSignalName" SG_ 1385 ISatID14 "SatID14";
BA_ "CompuMethodName" SG_ 1386 ISatAz15 "SatAz15";
BA_ "ISignalName" SG_ 1386 ISatAz15 "ISatAz15";
BA_ "LongName" SG_ 1386 ISatAz15 "Satellite15 Azimuth Angle";
BA_ "SysSignalName" SG_ 1386 ISatAz15 "SatAz15";
BA_ "CompuMethodName" SG_ 1386 ISatCNO15 "SatCNO15";
BA_ "ISignalName" SG_ 1386 ISatCNO15 "ISatCNO15";
BA_ "LongName" SG_ 1386 ISatCNO15 "Satellite15 Cno";
BA_ "SysSignalName" SG_ 1386 ISatCNO15 "SatCNO15";
BA_ "CompuMethodName" SG_ 1386 ISatElv15 "SatElv15";
BA_ "ISignalName" SG_ 1386 ISatElv15 "ISatElv15";
BA_ "LongName" SG_ 1386 ISatElv15 "Satellite15 Elevation Angle";
BA_ "SysSignalName" SG_ 1386 ISatElv15 "SatElv15";
BA_ "CompuMethodName" SG_ 1386 ISatAz16 "SatAz16";
BA_ "ISignalName" SG_ 1386 ISatAz16 "ISatAz16";
BA_ "LongName" SG_ 1386 ISatAz16 "Satellite16 Azimuth Angle";
BA_ "SysSignalName" SG_ 1386 ISatAz16 "SatAz16";
BA_ "CompuMethodName" SG_ 1386 ISatID15 "SatID15";
BA_ "ISignalName" SG_ 1386 ISatID15 "ISatID15";
BA_ "LongName" SG_ 1386 ISatID15 "Satellite15 Id";
BA_ "SysSignalName" SG_ 1386 ISatID15 "SatID15";
BA_ "CompuMethodName" SG_ 1386 ISatCNO16 "SatCNO16";
BA_ "ISignalName" SG_ 1386 ISatCNO16 "ISatCNO16";
BA_ "LongName" SG_ 1386 ISatCNO16 "Satellite16 Cno";
BA_ "SysSignalName" SG_ 1386 ISatCNO16 "SatCNO16";
BA_ "CompuMethodName" SG_ 1386 ISatElv16 "SatElv16";
BA_ "ISignalName" SG_ 1386 ISatElv16 "ISatElv16";
BA_ "LongName" SG_ 1386 ISatElv16 "Satellite16 Elevation Angle";
BA_ "SysSignalName" SG_ 1386 ISatElv16 "SatElv16";
BA_ "CompuMethodName" SG_ 1386 ISatID16 "SatID16";
BA_ "ISignalName" SG_ 1386 ISatID16 "ISatID16";
BA_ "LongName" SG_ 1386 ISatID16 "Satellite16 Id";
BA_ "SysSignalName" SG_ 1386 ISatID16 "SatID16";
BA_ "CompuMethodName" SG_ 1387 ISatAz19 "SatAz19";
BA_ "ISignalName" SG_ 1387 ISatAz19 "ISatAz19";
BA_ "LongName" SG_ 1387 ISatAz19 "Satellite19 Azimuth Angle";
BA_ "SysSignalName" SG_ 1387 ISatAz19 "SatAz19";
BA_ "CompuMethodName" SG_ 1387 ISatCNO19 "SatCNO19";
BA_ "ISignalName" SG_ 1387 ISatCNO19 "ISatCNO19";
BA_ "LongName" SG_ 1387 ISatCNO19 "Satellite19 Cno";
BA_ "SysSignalName" SG_ 1387 ISatCNO19 "SatCNO19";
BA_ "CompuMethodName" SG_ 1387 ISatElv19 "SatElv19";
BA_ "ISignalName" SG_ 1387 ISatElv19 "ISatElv19";
BA_ "LongName" SG_ 1387 ISatElv19 "Satellite19 Elevation Angle";
BA_ "SysSignalName" SG_ 1387 ISatElv19 "SatElv19";
BA_ "CompuMethodName" SG_ 1387 ISatAz20 "SatAz20";
BA_ "ISignalName" SG_ 1387 ISatAz20 "ISatAz20";
BA_ "LongName" SG_ 1387 ISatAz20 "Satellite20 Azimuth Angle";
BA_ "SysSignalName" SG_ 1387 ISatAz20 "SatAz20";
BA_ "CompuMethodName" SG_ 1387 ISatID19 "SatID19";
BA_ "ISignalName" SG_ 1387 ISatID19 "ISatID19";
BA_ "LongName" SG_ 1387 ISatID19 "Satellite19 Id";
BA_ "SysSignalName" SG_ 1387 ISatID19 "SatID19";
BA_ "CompuMethodName" SG_ 1387 ISatCNO20 "SatCNO20";
BA_ "ISignalName" SG_ 1387 ISatCNO20 "ISatCNO20";
BA_ "LongName" SG_ 1387 ISatCNO20 "Satellite20 Cno";
BA_ "SysSignalName" SG_ 1387 ISatCNO20 "SatCNO20";
BA_ "CompuMethodName" SG_ 1387 ISatElv20 "SatElv20";
BA_ "ISignalName" SG_ 1387 ISatElv20 "ISatElv20";
BA_ "LongName" SG_ 1387 ISatElv20 "Satellite20 Elevation Angle";
BA_ "SysSignalName" SG_ 1387 ISatElv20 "SatElv20";
BA_ "CompuMethodName" SG_ 1387 ISatID20 "SatID20";
BA_ "ISignalName" SG_ 1387 ISatID20 "ISatID20";
BA_ "LongName" SG_ 1387 ISatID20 "Satellite20 Id";
BA_ "SysSignalName" SG_ 1387 ISatID20 "SatID20";
BA_ "CompuMethodName" SG_ 1388 ISatNum "SatNum";
BA_ "ISignalName" SG_ 1388 ISatNum "ISatNum";
BA_ "LongName" SG_ 1388 ISatNum "Satellites Number";
BA_ "SysSignalName" SG_ 1388 ISatNum "SatNum";
BA_ "CompuMethodName" SG_ 1388 ISvGroup "SvGroup";
BA_ "ISignalName" SG_ 1388 ISvGroup "ISvGroup";
BA_ "LongName" SG_ 1388 ISvGroup "Gpgsv Data Send Group";
BA_ "SysSignalName" SG_ 1388 ISvGroup "SvGroup";
BA_ "CompuMethodName" SG_ 1380 ISatAz3 "SatAz3";
BA_ "ISignalName" SG_ 1380 ISatAz3 "ISatAz3";
BA_ "LongName" SG_ 1380 ISatAz3 "Satellite3 Azimuth Angle";
BA_ "SysSignalName" SG_ 1380 ISatAz3 "SatAz3";
BA_ "CompuMethodName" SG_ 1380 ISatCNO3 "SatCNO3";
BA_ "ISignalName" SG_ 1380 ISatCNO3 "ISatCNO3";
BA_ "LongName" SG_ 1380 ISatCNO3 "Satellite3 Cno";
BA_ "SysSignalName" SG_ 1380 ISatCNO3 "SatCNO3";
BA_ "CompuMethodName" SG_ 1380 ISatElv3 "SatElv3";
BA_ "ISignalName" SG_ 1380 ISatElv3 "ISatElv3";
BA_ "LongName" SG_ 1380 ISatElv3 "Satellite3 Elevation Angle";
BA_ "SysSignalName" SG_ 1380 ISatElv3 "SatElv3";
BA_ "CompuMethodName" SG_ 1380 ISatAz4 "SatAz4";
BA_ "ISignalName" SG_ 1380 ISatAz4 "ISatAz4";
BA_ "LongName" SG_ 1380 ISatAz4 "Satellite4 Azimuth Angle";
BA_ "SysSignalName" SG_ 1380 ISatAz4 "SatAz4";
BA_ "CompuMethodName" SG_ 1380 ISatID3 "SatID3";
BA_ "ISignalName" SG_ 1380 ISatID3 "ISatID3";
BA_ "LongName" SG_ 1380 ISatID3 "Satellite3 Id";
BA_ "SysSignalName" SG_ 1380 ISatID3 "SatID3";
BA_ "CompuMethodName" SG_ 1380 ISatCNO4 "SatCNO4";
BA_ "ISignalName" SG_ 1380 ISatCNO4 "ISatCNO4";
BA_ "LongName" SG_ 1380 ISatCNO4 "Satellite4 Cno";
BA_ "SysSignalName" SG_ 1380 ISatCNO4 "SatCNO4";
BA_ "CompuMethodName" SG_ 1380 ISatElv4 "SatElv4";
BA_ "ISignalName" SG_ 1380 ISatElv4 "ISatElv4";
BA_ "LongName" SG_ 1380 ISatElv4 "Satellite4 Elevation Angle";
BA_ "SysSignalName" SG_ 1380 ISatElv4 "SatElv4";
BA_ "CompuMethodName" SG_ 1380 ISatID4 "SatID4";
BA_ "ISignalName" SG_ 1380 ISatID4 "ISatID4";
BA_ "LongName" SG_ 1380 ISatID4 "Satellite4 Id";
BA_ "SysSignalName" SG_ 1380 ISatID4 "SatID4";
BA_ "CompuMethodName" SG_ 298 IP2PExeAvlblV "P2PExeAvlblV";
BA_ "ISignalName" SG_ 298 IP2PExeAvlblV "IP2PExeAvlblV";
BA_ "LongName" SG_ 298 IP2PExeAvlblV "Point_To_Point_Execution_Available_Validity";
BA_ "SysSignalName" SG_ 298 IP2PExeAvlblV "P2PExeAvlblV";
BA_ "CompuMethodName" SG_ 298 IP2PExeAvlbl "P2PExeAvlbl";
BA_ "ISignalName" SG_ 298 IP2PExeAvlbl "IP2PExeAvlbl";
BA_ "LongName" SG_ 298 IP2PExeAvlbl "Point_To_Point_Execution_Available";
BA_ "SysSignalName" SG_ 298 IP2PExeAvlbl "P2PExeAvlbl";
BA_ "CompuMethodName" SG_ 1082 ICANprotocolinternalversion "CANprotocolinternalversion";
BA_ "ISignalName" SG_ 1082 ICANprotocolinternalversion "ICANprotocolinternalversion";
BA_ "LongName" SG_ 1082 ICANprotocolinternalversion "CANprotocolinternalversion";
BA_ "SysSignalName" SG_ 1082 ICANprotocolinternalversion "CANprotocolinternalversion";
BA_ "CompuMethodName" SG_ 1082 IDiffDataLinkBroken "DiffDataLinkBroken";
BA_ "ISignalName" SG_ 1082 IDiffDataLinkBroken "IDiffDataLinkBroken";
BA_ "LongName" SG_ 1082 IDiffDataLinkBroken "Diff_Data_Link_Broken";
BA_ "SysSignalName" SG_ 1082 IDiffDataLinkBroken "DiffDataLinkBroken";
BA_ "CompuMethodName" SG_ 1082 IGNSSAntennasBroken "GNSSAntennasBroken";
BA_ "ISignalName" SG_ 1082 IGNSSAntennasBroken "IGNSSAntennasBroken";
BA_ "LongName" SG_ 1082 IGNSSAntennasBroken "GNSSAntennasBroken";
BA_ "SysSignalName" SG_ 1082 IGNSSAntennasBroken "GNSSAntennasBroken";
BA_ "CompuMethodName" SG_ 1082 IGNSSAntennasInfo "GNSSAntennasInfo";
BA_ "ISignalName" SG_ 1082 IGNSSAntennasInfo "IGNSSAntennasInfo";
BA_ "LongName" SG_ 1082 IGNSSAntennasInfo "GNSSAntennasInfo";
BA_ "SysSignalName" SG_ 1082 IGNSSAntennasInfo "GNSSAntennasInfo";
BA_ "CompuMethodName" SG_ 1082 IVelnorthsigma "Velnorthsigma";
BA_ "ISignalName" SG_ 1082 IVelnorthsigma "IVelnorthsigma";
BA_ "LongName" SG_ 1082 IVelnorthsigma "Velnorthsigma";
BA_ "SysSignalName" SG_ 1082 IVelnorthsigma "Velnorthsigma";
BA_ "CompuMethodName" SG_ 1082 IVeleastsigma "Veleastsigma";
BA_ "ISignalName" SG_ 1082 IVeleastsigma "IVeleastsigma";
BA_ "LongName" SG_ 1082 IVeleastsigma "Veleastsigma";
BA_ "SysSignalName" SG_ 1082 IVeleastsigma "Veleastsigma";
BA_ "CompuMethodName" SG_ 766 ISatNoInAttitudeRTK "SatNoInAttitudeRTK";
BA_ "ISignalName" SG_ 766 ISatNoInAttitudeRTK "ISatNoInAttitudeRTK";
BA_ "LongName" SG_ 766 ISatNoInAttitudeRTK "SatNoInAttitudeRTK";
BA_ "SysSignalName" SG_ 766 ISatNoInAttitudeRTK "SatNoInAttitudeRTK";
BA_ "CompuMethodName" SG_ 766 ISatNoInPositionRTK "SatNoInPositionRTK";
BA_ "ISignalName" SG_ 766 ISatNoInPositionRTK "ISatNoInPositionRTK";
BA_ "LongName" SG_ 766 ISatNoInPositionRTK "SatNoInPositionRTK";
BA_ "SysSignalName" SG_ 766 ISatNoInPositionRTK "SatNoInPositionRTK";
BA_ "CompuMethodName" SG_ 766 IEastVelocityRTK "EastVelocityRTK";
BA_ "ISignalName" SG_ 766 IEastVelocityRTK "IEastVelocityRTK";
BA_ "LongName" SG_ 766 IEastVelocityRTK "EastVelocityRTK";
BA_ "SysSignalName" SG_ 766 IEastVelocityRTK "EastVelocityRTK";
BA_ "CompuMethodName" SG_ 766 INorthVelocityRTK "NorthVelocityRTK";
BA_ "ISignalName" SG_ 766 INorthVelocityRTK "INorthVelocityRTK";
BA_ "LongName" SG_ 766 INorthVelocityRTK "NorthVelocityRTK";
BA_ "SysSignalName" SG_ 766 INorthVelocityRTK "NorthVelocityRTK";
BA_ "CompuMethodName" SG_ 335 IDiffAgeInfo "DiffAgeInfo";
BA_ "ISignalName" SG_ 335 IDiffAgeInfo "IDiffAgeInfo";
BA_ "LongName" SG_ 335 IDiffAgeInfo "DiffAgeInfo";
BA_ "SysSignalName" SG_ 335 IDiffAgeInfo "DiffAgeInfo";
BA_ "CompuMethodName" SG_ 335 IPositionAttitudeStatus "PositionAttitudeStatus";
BA_ "ISignalName" SG_ 335 IPositionAttitudeStatus "IPositionAttitudeStatus";
BA_ "LongName" SG_ 335 IPositionAttitudeStatus "Position_And_Attitudestatus";
BA_ "SysSignalName" SG_ 335 IPositionAttitudeStatus "PositionAttitudeStatus";
BA_ "CompuMethodName" SG_ 335 IBaseLineLen "BaseLineLen";
BA_ "ISignalName" SG_ 335 IBaseLineLen "IBaseLineLen";
BA_ "LongName" SG_ 335 IBaseLineLen "BaseLineLength";
BA_ "SysSignalName" SG_ 335 IBaseLineLen "BaseLineLen";
BA_ "CompuMethodName" SG_ 335 IVeldownsigma "Veldownsigma";
BA_ "ISignalName" SG_ 335 IVeldownsigma "IVeldownsigma";
BA_ "LongName" SG_ 335 IVeldownsigma "Veldownsigma";
BA_ "SysSignalName" SG_ 335 IVeldownsigma "Veldownsigma";
BA_ "CompuMethodName" SG_ 335 IDownVelocityRTK "DownVelocityRTK";
BA_ "ISignalName" SG_ 335 IDownVelocityRTK "IDownVelocityRTK";
BA_ "LongName" SG_ 335 IDownVelocityRTK "DownVelocityRTK";
BA_ "SysSignalName" SG_ 335 IDownVelocityRTK "DownVelocityRTK";
BA_ "CompuMethodName" SG_ 887 IIAM_100ms_Group08_CRC "IAM_100ms_Group08_CRC";
BA_ "ISignalName" SG_ 887 IIAM_100ms_Group08_CRC "IIAM_100ms_Group08_CRC";
BA_ "LongName" SG_ 887 IIAM_100ms_Group08_CRC "AltSigma";
BA_ "SysSignalName" SG_ 887 IIAM_100ms_Group08_CRC "IAM_100ms_Group08_CRC";
BA_ "CompuMethodName" SG_ 887 IIAM_100ms_Group08_RC "IAM_100ms_Group08_RC";
BA_ "ISignalName" SG_ 887 IIAM_100ms_Group08_RC "IIAM_100ms_Group08_RC";
BA_ "LongName" SG_ 887 IIAM_100ms_Group08_RC "AltSigma";
BA_ "SysSignalName" SG_ 887 IIAM_100ms_Group08_RC "IAM_100ms_Group08_RC";
BA_ "CompuMethodName" SG_ 887 IIAM_100ms_Group08_Reserved1 "IAM_100ms_Group08_Reserved1";
BA_ "GenSigStartValue" SG_ 887 IIAM_100ms_Group08_Reserved1 15;
BA_ "ISignalName" SG_ 887 IIAM_100ms_Group08_Reserved1 "IIAM_100ms_Group08_Reserved1";
BA_ "SysSignalName" SG_ 887 IIAM_100ms_Group08_Reserved1 "IAM_100ms_Group08_Reserved1";
BA_ "CompuMethodName" SG_ 887 ILatSigma "LatSigma";
BA_ "ISignalName" SG_ 887 ILatSigma "ILatSigma";
BA_ "LongName" SG_ 887 ILatSigma "LatSigma";
BA_ "SysSignalName" SG_ 887 ILatSigma "LatSigma";
BA_ "CompuMethodName" SG_ 887 ILonSigma "LonSigma";
BA_ "ISignalName" SG_ 887 ILonSigma "ILonSigma";
BA_ "LongName" SG_ 887 ILonSigma "LonSigma";
BA_ "SysSignalName" SG_ 887 ILonSigma "LonSigma";
BA_ "CompuMethodName" SG_ 887 IAltSigma "AltSigma";
BA_ "ISignalName" SG_ 887 IAltSigma "IAltSigma";
BA_ "LongName" SG_ 887 IAltSigma "AltSigma";
BA_ "SysSignalName" SG_ 887 IAltSigma "AltSigma";
BA_ "CompuMethodName" SG_ 700 IIAMtoIPD_Rsrv01 "IAMtoIPD_Rsrv01";
BA_ "ISignalName" SG_ 700 IIAMtoIPD_Rsrv01 "IIAMtoIPD_Rsrv01";
BA_ "LongName" SG_ 700 IIAMtoIPD_Rsrv01 "IAM_to_IPD_Reserved01";
BA_ "SysSignalName" SG_ 700 IIAMtoIPD_Rsrv01 "IAMtoIPD_Rsrv01";
BA_ "CompuMethodName" SG_ 700 IIAMtoIPD_Rsrv05 "IAMtoIPD_Rsrv05";
BA_ "ISignalName" SG_ 700 IIAMtoIPD_Rsrv05 "IIAMtoIPD_Rsrv05";
BA_ "LongName" SG_ 700 IIAMtoIPD_Rsrv05 "IAM_to_IPD_Reserved05";
BA_ "SysSignalName" SG_ 700 IIAMtoIPD_Rsrv05 "IAMtoIPD_Rsrv05";
BA_ "CompuMethodName" SG_ 700 IIAMtoIPD_Rsrv04 "IAMtoIPD_Rsrv04";
BA_ "ISignalName" SG_ 700 IIAMtoIPD_Rsrv04 "IIAMtoIPD_Rsrv04";
BA_ "LongName" SG_ 700 IIAMtoIPD_Rsrv04 "IAM_to_IPD_Reserved04";
BA_ "SysSignalName" SG_ 700 IIAMtoIPD_Rsrv04 "IAMtoIPD_Rsrv04";
BA_ "CompuMethodName" SG_ 700 IIAMtoIPD_Rsrv02 "IAMtoIPD_Rsrv02";
BA_ "ISignalName" SG_ 700 IIAMtoIPD_Rsrv02 "IIAMtoIPD_Rsrv02";
BA_ "LongName" SG_ 700 IIAMtoIPD_Rsrv02 "IAM_to_IPD_Reserved02";
BA_ "SysSignalName" SG_ 700 IIAMtoIPD_Rsrv02 "IAMtoIPD_Rsrv02";
BA_ "CompuMethodName" SG_ 700 IIAMtoIPD_Rsrv07 "IAMtoIPD_Rsrv07";
BA_ "ISignalName" SG_ 700 IIAMtoIPD_Rsrv07 "IIAMtoIPD_Rsrv07";
BA_ "LongName" SG_ 700 IIAMtoIPD_Rsrv07 "IAM_to_IPD_Reserved07";
BA_ "SysSignalName" SG_ 700 IIAMtoIPD_Rsrv07 "IAMtoIPD_Rsrv07";
BA_ "CompuMethodName" SG_ 700 IIAMtoIPD_Rsrv06 "IAMtoIPD_Rsrv06";
BA_ "ISignalName" SG_ 700 IIAMtoIPD_Rsrv06 "IIAMtoIPD_Rsrv06";
BA_ "LongName" SG_ 700 IIAMtoIPD_Rsrv06 "IAM_to_IPD_Reserved06";
BA_ "SysSignalName" SG_ 700 IIAMtoIPD_Rsrv06 "IAMtoIPD_Rsrv06";
BA_ "CompuMethodName" SG_ 700 IIAMtoIPD_Rsrv09 "IAMtoIPD_Rsrv09";
BA_ "ISignalName" SG_ 700 IIAMtoIPD_Rsrv09 "IIAMtoIPD_Rsrv09";
BA_ "LongName" SG_ 700 IIAMtoIPD_Rsrv09 "IAM_to_IPD_Reserved09";
BA_ "SysSignalName" SG_ 700 IIAMtoIPD_Rsrv09 "IAMtoIPD_Rsrv09";
BA_ "CompuMethodName" SG_ 700 IIAMtoIPD_Rsrv08 "IAMtoIPD_Rsrv08";
BA_ "ISignalName" SG_ 700 IIAMtoIPD_Rsrv08 "IIAMtoIPD_Rsrv08";
BA_ "LongName" SG_ 700 IIAMtoIPD_Rsrv08 "IAM_to_IPD_Reserved08";
BA_ "SysSignalName" SG_ 700 IIAMtoIPD_Rsrv08 "IAMtoIPD_Rsrv08";
BA_ "CompuMethodName" SG_ 700 IIAMtoIPD_Rsrv10 "IAMtoIPD_Rsrv10";
BA_ "ISignalName" SG_ 700 IIAMtoIPD_Rsrv10 "IIAMtoIPD_Rsrv10";
BA_ "LongName" SG_ 700 IIAMtoIPD_Rsrv10 "IAM_to_IPD_Reserved10";
BA_ "SysSignalName" SG_ 700 IIAMtoIPD_Rsrv10 "IAMtoIPD_Rsrv10";
BA_ "CompuMethodName" SG_ 700 IIAMtoIPD_Rsrv11 "IAMtoIPD_Rsrv11";
BA_ "ISignalName" SG_ 700 IIAMtoIPD_Rsrv11 "IIAMtoIPD_Rsrv11";
BA_ "LongName" SG_ 700 IIAMtoIPD_Rsrv11 "IAM_to_IPD_Reserved11";
BA_ "SysSignalName" SG_ 700 IIAMtoIPD_Rsrv11 "IAMtoIPD_Rsrv11";
BA_ "CompuMethodName" SG_ 700 IIAMtoIPD_Rsrv12 "IAMtoIPD_Rsrv12";
BA_ "ISignalName" SG_ 700 IIAMtoIPD_Rsrv12 "IIAMtoIPD_Rsrv12";
BA_ "LongName" SG_ 700 IIAMtoIPD_Rsrv12 "IAM_to_IPD_Reserved12";
BA_ "SysSignalName" SG_ 700 IIAMtoIPD_Rsrv12 "IAMtoIPD_Rsrv12";
BA_ "CompuMethodName" SG_ 700 IIAMtoIPD_Rsrv03 "IAMtoIPD_Rsrv03";
BA_ "ISignalName" SG_ 700 IIAMtoIPD_Rsrv03 "IIAMtoIPD_Rsrv03";
BA_ "LongName" SG_ 700 IIAMtoIPD_Rsrv03 "IAM_to_IPD_Reserved03";
BA_ "SysSignalName" SG_ 700 IIAMtoIPD_Rsrv03 "IAMtoIPD_Rsrv03";
BA_ "CompuMethodName" SG_ 700 IIAMtoIPDResv15 "IAMtoIPDResv15";
BA_ "ISignalName" SG_ 700 IIAMtoIPDResv15 "IIAMtoIPDResv15";
BA_ "LongName" SG_ 700 IIAMtoIPDResv15 "IAMtoIPD Resver signal 15";
BA_ "SysSignalName" SG_ 700 IIAMtoIPDResv15 "IAMtoIPDResv15";
BA_ "CompuMethodName" SG_ 700 IIAMtoIPDResv13 "IAMtoIPDResv13";
BA_ "ISignalName" SG_ 700 IIAMtoIPDResv13 "IIAMtoIPDResv13";
BA_ "LongName" SG_ 700 IIAMtoIPDResv13 "IAMtoIPD Resver signal 13";
BA_ "SysSignalName" SG_ 700 IIAMtoIPDResv13 "IAMtoIPDResv13";
BA_ "CompuMethodName" SG_ 700 IIAMtoIPDResv14 "IAMtoIPDResv14";
BA_ "ISignalName" SG_ 700 IIAMtoIPDResv14 "IIAMtoIPDResv14";
BA_ "LongName" SG_ 700 IIAMtoIPDResv14 "IAMtoIPD Resver signal 14";
BA_ "SysSignalName" SG_ 700 IIAMtoIPDResv14 "IAMtoIPDResv14";
BA_ "CompuMethodName" SG_ 912 IIAM_ZONE_100ms_Group34_CRC "IAM_ZONE_100ms_Group34_CRC";
BA_ "ISignalName" SG_ 912 IIAM_ZONE_100ms_Group34_CRC "IIAM_ZONE_100ms_Group34_CRC";
BA_ "LongName" SG_ 912 IIAM_ZONE_100ms_Group34_CRC "Horizontal Dilution Of Position";
BA_ "SysSignalName" SG_ 912 IIAM_ZONE_100ms_Group34_CRC "IAM_ZONE_100ms_Group34_CRC";
BA_ "CompuMethodName" SG_ 912 IIAM_ZONE_100ms_Group34_RC "IAM_ZONE_100ms_Group34_RC";
BA_ "ISignalName" SG_ 912 IIAM_ZONE_100ms_Group34_RC "IIAM_ZONE_100ms_Group34_RC";
BA_ "LongName" SG_ 912 IIAM_ZONE_100ms_Group34_RC "Horizontal Dilution Of Position";
BA_ "SysSignalName" SG_ 912 IIAM_ZONE_100ms_Group34_RC "IAM_ZONE_100ms_Group34_RC";
BA_ "CompuMethodName" SG_ 912 IIAM_ZONE_100ms_Group34_Reserved0 "IAM_ZONE_100ms_Group34_Reserved1";
BA_ "GenSigStartValue" SG_ 912 IIAM_ZONE_100ms_Group34_Reserved0 15;
BA_ "ISignalName" SG_ 912 IIAM_ZONE_100ms_Group34_Reserved0 "IIAM_ZONE_100ms_Group34_Reserved1";
BA_ "SysSignalName" SG_ 912 IIAM_ZONE_100ms_Group34_Reserved0 "IAM_ZONE_100ms_Group34_Reserved1";
BA_ "SystemSignalLongSymbol" SG_ 912 IIAM_ZONE_100ms_Group34_Reserved0 "IIAM_ZONE_100ms_Group34_Reserved1";
BA_ "CompuMethodName" SG_ 912 IPdop "Pdop";
BA_ "ISignalName" SG_ 912 IPdop "IPdop";
BA_ "LongName" SG_ 912 IPdop "Position Dilution Of Precision";
BA_ "SysSignalName" SG_ 912 IPdop "Pdop";
BA_ "CompuMethodName" SG_ 912 IIAM_ZONE_100ms_Group34_Reserved1 "IAM_ZONE_100ms_Group34_Reserved2";
BA_ "GenSigStartValue" SG_ 912 IIAM_ZONE_100ms_Group34_Reserved1 3;
BA_ "ISignalName" SG_ 912 IIAM_ZONE_100ms_Group34_Reserved1 "IIAM_ZONE_100ms_Group34_Reserved2";
BA_ "SysSignalName" SG_ 912 IIAM_ZONE_100ms_Group34_Reserved1 "IAM_ZONE_100ms_Group34_Reserved2";
BA_ "SystemSignalLongSymbol" SG_ 912 IIAM_ZONE_100ms_Group34_Reserved1 "IIAM_ZONE_100ms_Group34_Reserved2";
BA_ "CompuMethodName" SG_ 912 IVdop "Vdop";
BA_ "ISignalName" SG_ 912 IVdop "IVdop";
BA_ "LongName" SG_ 912 IVdop "Vertical Dilution Of Precision";
BA_ "SysSignalName" SG_ 912 IVdop "Vdop";
BA_ "CompuMethodName" SG_ 912 IIAM_ZONE_100ms_Group34_Reserved2 "IAM_ZONE_100ms_Group34_Reserved3";
BA_ "GenSigStartValue" SG_ 912 IIAM_ZONE_100ms_Group34_Reserved2 3;
BA_ "ISignalName" SG_ 912 IIAM_ZONE_100ms_Group34_Reserved2 "IIAM_ZONE_100ms_Group34_Reserved3";
BA_ "SysSignalName" SG_ 912 IIAM_ZONE_100ms_Group34_Reserved2 "IAM_ZONE_100ms_Group34_Reserved3";
BA_ "SystemSignalLongSymbol" SG_ 912 IIAM_ZONE_100ms_Group34_Reserved2 "IIAM_ZONE_100ms_Group34_Reserved3";
BA_ "CompuMethodName" SG_ 912 IHdop "Hdop";
BA_ "ISignalName" SG_ 912 IHdop "IHdop";
BA_ "LongName" SG_ 912 IHdop "Horizontal Dilution Of Position";
BA_ "SysSignalName" SG_ 912 IHdop "Hdop";
BA_ "CompuMethodName" SG_ 912 IIAM_ZONE_100ms_Group34_Reserved3 "IAM_ZONE_100ms_Group34_Reserved4";
BA_ "GenSigStartValue" SG_ 912 IIAM_ZONE_100ms_Group34_Reserved3 3;
BA_ "ISignalName" SG_ 912 IIAM_ZONE_100ms_Group34_Reserved3 "IIAM_ZONE_100ms_Group34_Reserved4";
BA_ "SysSignalName" SG_ 912 IIAM_ZONE_100ms_Group34_Reserved3 "IAM_ZONE_100ms_Group34_Reserved4";
BA_ "SystemSignalLongSymbol" SG_ 912 IIAM_ZONE_100ms_Group34_Reserved3 "IIAM_ZONE_100ms_Group34_Reserved4";
BA_ "CompuMethodName" SG_ 874 IIAM_ZONE_100ms_Group40_CRC "IAM_ZONE_100ms_Group40_CRC";
BA_ "ISignalName" SG_ 874 IIAM_ZONE_100ms_Group40_CRC "IIAM_ZONE_100ms_Group40_CRC";
BA_ "LongName" SG_ 874 IIAM_ZONE_100ms_Group40_CRC "AltitudeRTK";
BA_ "SysSignalName" SG_ 874 IIAM_ZONE_100ms_Group40_CRC "IAM_ZONE_100ms_Group40_CRC";
BA_ "CompuMethodName" SG_ 874 IIAM_ZONE_100ms_Group40_RC "IAM_ZONE_100ms_Group40_RC";
BA_ "ISignalName" SG_ 874 IIAM_ZONE_100ms_Group40_RC "IIAM_ZONE_100ms_Group40_RC";
BA_ "LongName" SG_ 874 IIAM_ZONE_100ms_Group40_RC "AltitudeRTK";
BA_ "SysSignalName" SG_ 874 IIAM_ZONE_100ms_Group40_RC "IAM_ZONE_100ms_Group40_RC";
BA_ "CompuMethodName" SG_ 874 IIAM_ZONE_100ms_Group40_Reserved0 "IAM_ZONE_100ms_Group40_Reserved1";
BA_ "GenSigStartValue" SG_ 874 IIAM_ZONE_100ms_Group40_Reserved0 15;
BA_ "ISignalName" SG_ 874 IIAM_ZONE_100ms_Group40_Reserved0 "IIAM_ZONE_100ms_Group40_Reserved1";
BA_ "SysSignalName" SG_ 874 IIAM_ZONE_100ms_Group40_Reserved0 "IAM_ZONE_100ms_Group40_Reserved1";
BA_ "SystemSignalLongSymbol" SG_ 874 IIAM_ZONE_100ms_Group40_Reserved0 "IIAM_ZONE_100ms_Group40_Reserved1";
BA_ "CompuMethodName" SG_ 874 IAltitudeRTK "AltitudeRTK";
BA_ "ISignalName" SG_ 874 IAltitudeRTK "IAltitudeRTK";
BA_ "LongName" SG_ 874 IAltitudeRTK "AltitudeRTK";
BA_ "SysSignalName" SG_ 874 IAltitudeRTK "AltitudeRTK";
BA_ "CompuMethodName" SG_ 874 IHeadingRTK "HeadingRTK";
BA_ "ISignalName" SG_ 874 IHeadingRTK "IHeadingRTK";
BA_ "LongName" SG_ 874 IHeadingRTK "HeadingRTK";
BA_ "SysSignalName" SG_ 874 IHeadingRTK "HeadingRTK";
BA_ "CompuMethodName" SG_ 874 IIAM_ZONE_100ms_Group40_Reserved1 "IAM_ZONE_100ms_Group40_Reserved2";
BA_ "GenSigStartValue" SG_ 874 IIAM_ZONE_100ms_Group40_Reserved1 255;
BA_ "ISignalName" SG_ 874 IIAM_ZONE_100ms_Group40_Reserved1 "IIAM_ZONE_100ms_Group40_Reserved2";
BA_ "SysSignalName" SG_ 874 IIAM_ZONE_100ms_Group40_Reserved1 "IAM_ZONE_100ms_Group40_Reserved2";
BA_ "SystemSignalLongSymbol" SG_ 874 IIAM_ZONE_100ms_Group40_Reserved1 "IIAM_ZONE_100ms_Group40_Reserved2";
BA_ "CompuMethodName" SG_ 336 IIAM_20ms_Group32_CRC "IAM_20ms_Group32_CRC";
BA_ "ISignalName" SG_ 336 IIAM_20ms_Group32_CRC "IIAM_20ms_Group32_CRC";
BA_ "SysSignalName" SG_ 336 IIAM_20ms_Group32_CRC "IAM_20ms_Group32_CRC";
BA_ "CompuMethodName" SG_ 336 IIAM_20ms_Group32_RC "IAM_20ms_Group32_RC";
BA_ "ISignalName" SG_ 336 IIAM_20ms_Group32_RC "IIAM_20ms_Group32_RC";
BA_ "SysSignalName" SG_ 336 IIAM_20ms_Group32_RC "IAM_20ms_Group32_RC";
BA_ "CompuMethodName" SG_ 336 IRmtParkngAstParkngOutDircnSeln "RmtParkngAstParkngOutDircnSeln";
BA_ "ISignalName" SG_ 336 IRmtParkngAstParkngOutDircnSeln "IRmtParkngAstParkngOutDircnSeln";
BA_ "LongName" SG_ 336 IRmtParkngAstParkngOutDircnSeln "Remote Parking Assist Parking Out Direction Selection";
BA_ "SysSignalName" SG_ 336 IRmtParkngAstParkngOutDircnSeln "RmtParkngAstParkngOutDircnSeln";
BA_ "CompuMethodName" SG_ 336 IRmtParkngAstBtnSts "RmtParkngAstBtnSts";
BA_ "ISignalName" SG_ 336 IRmtParkngAstBtnSts "IRmtParkngAstBtnSts";
BA_ "LongName" SG_ 336 IRmtParkngAstBtnSts "Remote Parking Assist Button Status";
BA_ "SysSignalName" SG_ 336 IRmtParkngAstBtnSts "RmtParkngAstBtnSts";
BA_ "CompuMethodName" SG_ 336 IVehFwdSwReq "VehFwdSwReq";
BA_ "ISignalName" SG_ 336 IVehFwdSwReq "IVehFwdSwReq";
BA_ "LongName" SG_ 336 IVehFwdSwReq "Vehicle Forward Switch Request";
BA_ "SysSignalName" SG_ 336 IVehFwdSwReq "VehFwdSwReq";
BA_ "CompuMethodName" SG_ 336 IVehBkwdSwReq "VehBkwdSwReq";
BA_ "ISignalName" SG_ 336 IVehBkwdSwReq "IVehBkwdSwReq";
BA_ "LongName" SG_ 336 IVehBkwdSwReq "Vehicle Backward Switch Request";
BA_ "SysSignalName" SG_ 336 IVehBkwdSwReq "VehBkwdSwReq";
BA_ "CompuMethodName" SG_ 336 IRmtParkngAstDvcSts "RmtParkngAstDvcSts";
BA_ "ISignalName" SG_ 336 IRmtParkngAstDvcSts "IRmtParkngAstDvcSts";
BA_ "LongName" SG_ 336 IRmtParkngAstDvcSts "Remote Parking Assist Device Status";
BA_ "SysSignalName" SG_ 336 IRmtParkngAstDvcSts "RmtParkngAstDvcSts";
BA_ "CompuMethodName" SG_ 336 IIAM_20ms_Group32_Reserved1 "IAM_20ms_Group32_Reserved1";
BA_ "GenSigStartValue" SG_ 336 IIAM_20ms_Group32_Reserved1 255;
BA_ "ISignalName" SG_ 336 IIAM_20ms_Group32_Reserved1 "IIAM_20ms_Group32_Reserved1";
BA_ "SysSignalName" SG_ 336 IIAM_20ms_Group32_Reserved1 "IAM_20ms_Group32_Reserved1";
BA_ "CompuMethodName" SG_ 336 IIAM_20ms_Group32_Reserved2 "IAM_20ms_Group32_Reserved2";
BA_ "GenSigStartValue" SG_ 336 IIAM_20ms_Group32_Reserved2 255;
BA_ "ISignalName" SG_ 336 IIAM_20ms_Group32_Reserved2 "IIAM_20ms_Group32_Reserved2";
BA_ "SysSignalName" SG_ 336 IIAM_20ms_Group32_Reserved2 "IAM_20ms_Group32_Reserved2";
BA_ "CompuMethodName" SG_ 336 IIAM_20ms_Group32_Reserved3 "IAM_20ms_Group32_Reserved3";
BA_ "GenSigStartValue" SG_ 336 IIAM_20ms_Group32_Reserved3 255;
BA_ "ISignalName" SG_ 336 IIAM_20ms_Group32_Reserved3 "IIAM_20ms_Group32_Reserved3";
BA_ "SysSignalName" SG_ 336 IIAM_20ms_Group32_Reserved3 "IAM_20ms_Group32_Reserved3";
BA_ "CompuMethodName" SG_ 336 IIAM_20ms_Group32_Reserved4 "IAM_20ms_Group32_Reserved4";
BA_ "GenSigStartValue" SG_ 336 IIAM_20ms_Group32_Reserved4 255;
BA_ "ISignalName" SG_ 336 IIAM_20ms_Group32_Reserved4 "IIAM_20ms_Group32_Reserved4";
BA_ "SysSignalName" SG_ 336 IIAM_20ms_Group32_Reserved4 "IAM_20ms_Group32_Reserved4";
BA_ "CompuMethodName" SG_ 336 IIAM_20ms_Group32_Reserved5 "IAM_20ms_Group32_Reserved5";
BA_ "GenSigStartValue" SG_ 336 IIAM_20ms_Group32_Reserved5 255;
BA_ "ISignalName" SG_ 336 IIAM_20ms_Group32_Reserved5 "IIAM_20ms_Group32_Reserved5";
BA_ "SysSignalName" SG_ 336 IIAM_20ms_Group32_Reserved5 "IAM_20ms_Group32_Reserved5";
BA_ "CompuMethodName" SG_ 336 IIAM_20ms_Group32_Reserved6 "IAM_20ms_Group32_Reserved6";
BA_ "GenSigStartValue" SG_ 336 IIAM_20ms_Group32_Reserved6 255;
BA_ "ISignalName" SG_ 336 IIAM_20ms_Group32_Reserved6 "IIAM_20ms_Group32_Reserved6";
BA_ "SysSignalName" SG_ 336 IIAM_20ms_Group32_Reserved6 "IAM_20ms_Group32_Reserved6";
BA_ "CompuMethodName" SG_ 336 IIAM_20ms_Group32_Reserved7 "IAM_20ms_Group32_Reserved7";
BA_ "GenSigStartValue" SG_ 336 IIAM_20ms_Group32_Reserved7 255;
BA_ "ISignalName" SG_ 336 IIAM_20ms_Group32_Reserved7 "IIAM_20ms_Group32_Reserved7";
BA_ "SysSignalName" SG_ 336 IIAM_20ms_Group32_Reserved7 "IAM_20ms_Group32_Reserved7";
BA_ "CompuMethodName" SG_ 336 IIAM_20ms_Group32_Reserved8 "IAM_20ms_Group32_Reserved8";
BA_ "GenSigStartValue" SG_ 336 IIAM_20ms_Group32_Reserved8 255;
BA_ "ISignalName" SG_ 336 IIAM_20ms_Group32_Reserved8 "IIAM_20ms_Group32_Reserved8";
BA_ "SysSignalName" SG_ 336 IIAM_20ms_Group32_Reserved8 "IAM_20ms_Group32_Reserved8";
BA_ "CompuMethodName" SG_ 336 IIAM_20ms_Group32_Reserved9 "IAM_20ms_Group32_Reserved9";
BA_ "GenSigStartValue" SG_ 336 IIAM_20ms_Group32_Reserved9 255;
BA_ "ISignalName" SG_ 336 IIAM_20ms_Group32_Reserved9 "IIAM_20ms_Group32_Reserved9";
BA_ "SysSignalName" SG_ 336 IIAM_20ms_Group32_Reserved9 "IAM_20ms_Group32_Reserved9";
BA_ "CompuMethodName" SG_ 336 IIAM_20ms_Group32_Reserved10 "IAM_20ms_Group32_Reserved10";
BA_ "GenSigStartValue" SG_ 336 IIAM_20ms_Group32_Reserved10 255;
BA_ "ISignalName" SG_ 336 IIAM_20ms_Group32_Reserved10 "IIAM_20ms_Group32_Reserved10";
BA_ "SysSignalName" SG_ 336 IIAM_20ms_Group32_Reserved10 "IAM_20ms_Group32_Reserved10";
BA_ "CompuMethodName" SG_ 336 IIAM_20ms_Group32_Reserved11 "IAM_20ms_Group32_Reserved11";
BA_ "GenSigStartValue" SG_ 336 IIAM_20ms_Group32_Reserved11 255;
BA_ "ISignalName" SG_ 336 IIAM_20ms_Group32_Reserved11 "IIAM_20ms_Group32_Reserved11";
BA_ "SysSignalName" SG_ 336 IIAM_20ms_Group32_Reserved11 "IAM_20ms_Group32_Reserved11";
BA_ "CompuMethodName" SG_ 336 IIAM_20ms_Group32_Reserved12 "IAM_20ms_Group32_Reserved12";
BA_ "GenSigStartValue" SG_ 336 IIAM_20ms_Group32_Reserved12 255;
BA_ "ISignalName" SG_ 336 IIAM_20ms_Group32_Reserved12 "IIAM_20ms_Group32_Reserved12";
BA_ "SysSignalName" SG_ 336 IIAM_20ms_Group32_Reserved12 "IAM_20ms_Group32_Reserved12";
BA_ "CompuMethodName" SG_ 336 IIAM_20ms_Group32_Reserved13 "IAM_20ms_Group32_Reserved13";
BA_ "GenSigStartValue" SG_ 336 IIAM_20ms_Group32_Reserved13 255;
BA_ "ISignalName" SG_ 336 IIAM_20ms_Group32_Reserved13 "IIAM_20ms_Group32_Reserved13";
BA_ "SysSignalName" SG_ 336 IIAM_20ms_Group32_Reserved13 "IAM_20ms_Group32_Reserved13";
BA_ "CompuMethodName" SG_ 89 IPkUpPntID "PkUpPntID";
BA_ "ISignalName" SG_ 89 IPkUpPntID "IPkUpPntID";
BA_ "LongName" SG_ 89 IPkUpPntID "Pick Up Point Identification";
BA_ "SysSignalName" SG_ 89 IPkUpPntID "PkUpPntID";
BA_ "CompuMethodName" SG_ 89 IIAMReststs "IAMReststs";
BA_ "ISignalName" SG_ 89 IIAMReststs "IIAMReststs";
BA_ "LongName" SG_ 89 IIAMReststs "IAM rest status";
BA_ "SysSignalName" SG_ 89 IIAMReststs "IAMReststs";
BA_ "CompuMethodName" SG_ 1000 ITrfcForbidDist "TrfcForbidDist";
BA_ "ISignalName" SG_ 1000 ITrfcForbidDist "ITrfcForbidDist";
BA_ "LongName" SG_ 1000 ITrfcForbidDist "Traffic_Forbidden_Distance";
BA_ "SysSignalName" SG_ 1000 ITrfcForbidDist "TrfcForbidDist";
BA_ "CompuMethodName" SG_ 1000 ITrfcWrnngSignDist "TrfcWrnngSignDist";
BA_ "ISignalName" SG_ 1000 ITrfcWrnngSignDist "ITrfcWrnngSignDist";
BA_ "LongName" SG_ 1000 ITrfcWrnngSignDist "Traffic_Warning_Distance";
BA_ "SysSignalName" SG_ 1000 ITrfcWrnngSignDist "TrfcWrnngSignDist";
BA_ "CompuMethodName" SG_ 1000 ITrfcInfoSignDist "TrfcInfoSignDist";
BA_ "ISignalName" SG_ 1000 ITrfcInfoSignDist "ITrfcInfoSignDist";
BA_ "LongName" SG_ 1000 ITrfcInfoSignDist "Traffic_Information_Distance";
BA_ "SysSignalName" SG_ 1000 ITrfcInfoSignDist "TrfcInfoSignDist";
BA_ "CompuMethodName" SG_ 1000 ISmtKeyAuthnSubModRunSts "SmtKeyAuthnSubModRunSts";
BA_ "ISignalName" SG_ 1000 ISmtKeyAuthnSubModRunSts "ISmtKeyAuthnSubModRunSts";
BA_ "LongName" SG_ 1000 ISmtKeyAuthnSubModRunSts "Smart_Key__Authentication_Smart_Key_Module_Run_Status";
BA_ "SysSignalName" SG_ 1000 ISmtKeyAuthnSubModRunSts "SmtKeyAuthnSubModRunSts";
BA_ "CompuMethodName" SG_ 1000 ITgtRembParkngChosenSpcID "TgtRembParkngChosenSpcID";
BA_ "ISignalName" SG_ 1000 ITgtRembParkngChosenSpcID "ITgtRembParkngChosenSpcID";
BA_ "LongName" SG_ 1000 ITgtRembParkngChosenSpcID "Target Remember Parking Chosen Space Id";
BA_ "SysSignalName" SG_ 1000 ITgtRembParkngChosenSpcID "TgtRembParkngChosenSpcID";
BA_ "CompuMethodName" SG_ 1000 ICellularRSSI "CellularRSSI";
BA_ "ISignalName" SG_ 1000 ICellularRSSI "ICellularRSSI";
BA_ "LongName" SG_ 1000 ICellularRSSI "CellularRSSI";
BA_ "SysSignalName" SG_ 1000 ICellularRSSI "CellularRSSI";
BA_ "CompuMethodName" SG_ 811 IIAM_100ms_PDU18_CRC "IAM_100ms_PDU18_CRC";
BA_ "ISignalName" SG_ 811 IIAM_100ms_PDU18_CRC "IIAM_100ms_PDU18_CRC";
BA_ "LongName" SG_ 811 IIAM_100ms_PDU18_CRC "checksum of";
BA_ "SysSignalName" SG_ 811 IIAM_100ms_PDU18_CRC "IAM_100ms_PDU18_CRC";
BA_ "CompuMethodName" SG_ 811 IIAM_100ms_PDU18_RC "IAM_100ms_PDU18_RC";
BA_ "ISignalName" SG_ 811 IIAM_100ms_PDU18_RC "IIAM_100ms_PDU18_RC";
BA_ "LongName" SG_ 811 IIAM_100ms_PDU18_RC "rolling counter";
BA_ "SysSignalName" SG_ 811 IIAM_100ms_PDU18_RC "IAM_100ms_PDU18_RC";
BA_ "CompuMethodName" SG_ 811 IIAM_100ms_Group18_Reserved1 "IAM_100ms_Group18_Reserved1";
BA_ "GenSigStartValue" SG_ 811 IIAM_100ms_Group18_Reserved1 15;
BA_ "ISignalName" SG_ 811 IIAM_100ms_Group18_Reserved1 "IIAM_100ms_Group18_Reserved1";
BA_ "SysSignalName" SG_ 811 IIAM_100ms_Group18_Reserved1 "IAM_100ms_Group18_Reserved1";
BA_ "CompuMethodName" SG_ 811 IPitchRTK "PitchRTK";
BA_ "ISignalName" SG_ 811 IPitchRTK "IPitchRTK";
BA_ "LongName" SG_ 811 IPitchRTK "PitchRTK";
BA_ "SysSignalName" SG_ 811 IPitchRTK "PitchRTK";
BA_ "CompuMethodName" SG_ 811 IHeadingSigma "HeadingSigma";
BA_ "ISignalName" SG_ 811 IHeadingSigma "IHeadingSigma";
BA_ "LongName" SG_ 811 IHeadingSigma "HeadingSigma";
BA_ "SysSignalName" SG_ 811 IHeadingSigma "HeadingSigma";
BA_ "CompuMethodName" SG_ 811 IPitchSigma "PitchSigma";
BA_ "ISignalName" SG_ 811 IPitchSigma "IPitchSigma";
BA_ "LongName" SG_ 811 IPitchSigma "PitchSigma";
BA_ "SysSignalName" SG_ 811 IPitchSigma "PitchSigma";
BA_ "CompuMethodName" SG_ 1358 IKeyDeleResp "KeyDeleResp";
BA_ "ISignalName" SG_ 1358 IKeyDeleResp "IKeyDeleResp";
BA_ "LongName" SG_ 1358 IKeyDeleResp "Key Delete  Response";
BA_ "SysSignalName" SG_ 1358 IKeyDeleResp "KeyDeleResp";
BA_ "CompuMethodName" SG_ 1358 IAIParkngReq "AIParkngReq";
BA_ "ISignalName" SG_ 1358 IAIParkngReq "IAIParkngReq";
BA_ "LongName" SG_ 1358 IAIParkngReq "ParkingRequest";
BA_ "SysSignalName" SG_ 1358 IAIParkngReq "AIParkngReq";
BA_ "CompuMethodName" SG_ 810 IIAM_ZONE_100ms_Group57_CRC "IAM_ZONE_100ms_Group57_CRC";
BA_ "ISignalName" SG_ 810 IIAM_ZONE_100ms_Group57_CRC "IIAM_ZONE_100ms_Group57_CRC";
BA_ "LongName" SG_ 810 IIAM_ZONE_100ms_Group57_CRC "LongitudeRTK";
BA_ "SysSignalName" SG_ 810 IIAM_ZONE_100ms_Group57_CRC "IAM_ZONE_100ms_Group57_CRC";
BA_ "CompuMethodName" SG_ 810 IIAM_ZONE_100ms_Group57_RC "IAM_ZONE_100ms_Group57_RC";
BA_ "ISignalName" SG_ 810 IIAM_ZONE_100ms_Group57_RC "IIAM_ZONE_100ms_Group57_RC";
BA_ "LongName" SG_ 810 IIAM_ZONE_100ms_Group57_RC "LongitudeRTK";
BA_ "SysSignalName" SG_ 810 IIAM_ZONE_100ms_Group57_RC "IAM_ZONE_100ms_Group57_RC";
BA_ "CompuMethodName" SG_ 810 IIAM_ZONE_100ms_Group57_Reserved0 "IAM_ZONE_100ms_Group57_Reserved1";
BA_ "GenSigStartValue" SG_ 810 IIAM_ZONE_100ms_Group57_Reserved0 15;
BA_ "ISignalName" SG_ 810 IIAM_ZONE_100ms_Group57_Reserved0 "IIAM_ZONE_100ms_Group57_Reserved1";
BA_ "SysSignalName" SG_ 810 IIAM_ZONE_100ms_Group57_Reserved0 "IAM_ZONE_100ms_Group57_Reserved1";
BA_ "SystemSignalLongSymbol" SG_ 810 IIAM_ZONE_100ms_Group57_Reserved0 "IIAM_ZONE_100ms_Group57_Reserved1";
BA_ "CompuMethodName" SG_ 810 ILongitudeRTK "LongitudeRTK";
BA_ "ISignalName" SG_ 810 ILongitudeRTK "ILongitudeRTK";
BA_ "LongName" SG_ 810 ILongitudeRTK "LongitudeRTK";
BA_ "SysSignalName" SG_ 810 ILongitudeRTK "LongitudeRTK";
BA_ "CompuMethodName" SG_ 810 IIAM_ZONE_100ms_Group57_Reserved1 "IAM_ZONE_100ms_Group57_Reserved2";
BA_ "GenSigStartValue" SG_ 810 IIAM_ZONE_100ms_Group57_Reserved1 255;
BA_ "ISignalName" SG_ 810 IIAM_ZONE_100ms_Group57_Reserved1 "IIAM_ZONE_100ms_Group57_Reserved2";
BA_ "SysSignalName" SG_ 810 IIAM_ZONE_100ms_Group57_Reserved1 "IAM_ZONE_100ms_Group57_Reserved2";
BA_ "SystemSignalLongSymbol" SG_ 810 IIAM_ZONE_100ms_Group57_Reserved1 "IIAM_ZONE_100ms_Group57_Reserved2";
BA_ "CompuMethodName" SG_ 793 IIAM_ZONE_100ms_PDU35_CRC "IAM_ZONE_100ms_PDU35_CRC";
BA_ "ISignalName" SG_ 793 IIAM_ZONE_100ms_PDU35_CRC "IIAM_ZONE_100ms_PDU35_CRC";
BA_ "SysSignalName" SG_ 793 IIAM_ZONE_100ms_PDU35_CRC "IAM_ZONE_100ms_PDU35_CRC";
BA_ "CompuMethodName" SG_ 793 IIAM_ZONE_100ms_PDU35_RC "IAM_ZONE_100ms_PDU35_RC";
BA_ "ISignalName" SG_ 793 IIAM_ZONE_100ms_PDU35_RC "IIAM_ZONE_100ms_PDU35_RC";
BA_ "SysSignalName" SG_ 793 IIAM_ZONE_100ms_PDU35_RC "IAM_ZONE_100ms_PDU35_RC";
BA_ "CompuMethodName" SG_ 793 IIAM_ZONE_100ms_Group35_Reserved "IAM_ZONE_100ms_Group35_Reserved1";
BA_ "GenSigStartValue" SG_ 793 IIAM_ZONE_100ms_Group35_Reserved 15;
BA_ "ISignalName" SG_ 793 IIAM_ZONE_100ms_Group35_Reserved "IIAM_ZONE_100ms_Group35_Reserved1";
BA_ "SysSignalName" SG_ 793 IIAM_ZONE_100ms_Group35_Reserved "IAM_ZONE_100ms_Group35_Reserved1";
BA_ "SystemSignalLongSymbol" SG_ 793 IIAM_ZONE_100ms_Group35_Reserved "IIAM_ZONE_100ms_Group35_Reserved1";
BA_ "CompuMethodName" SG_ 793 IGNSSUTCTime "GNSSUTCTime";
BA_ "ISignalName" SG_ 793 IGNSSUTCTime "IGNSSUTCTime";
BA_ "LongName" SG_ 793 IGNSSUTCTime "Gnss Utc Time";
BA_ "SysSignalName" SG_ 793 IGNSSUTCTime "GNSSUTCTime";
BA_ "CompuMethodName" SG_ 793 IGNSSF9HCounter "GNSSF9HCounter";
BA_ "ISignalName" SG_ 793 IGNSSF9HCounter "IGNSSF9HCounter";
BA_ "LongName" SG_ 793 IGNSSF9HCounter "GNSSF9HCounter";
BA_ "SysSignalName" SG_ 793 IGNSSF9HCounter "GNSSF9HCounter";
BA_ "CompuMethodName" SG_ 773 IIAM_ZONE_100ms_Group13_CRC "IAM_ZONE_100ms_Group13_CRC";
BA_ "ISignalName" SG_ 773 IIAM_ZONE_100ms_Group13_CRC "IIAM_ZONE_100ms_Group13_CRC";
BA_ "LongName" SG_ 773 IIAM_ZONE_100ms_Group13_CRC "Gnss Fix Type";
BA_ "SysSignalName" SG_ 773 IIAM_ZONE_100ms_Group13_CRC "IAM_ZONE_100ms_Group13_CRC";
BA_ "CompuMethodName" SG_ 773 IIAM_ZONE_100ms_Group13_RC "IAM_ZONE_100ms_Group13_RC";
BA_ "ISignalName" SG_ 773 IIAM_ZONE_100ms_Group13_RC "IIAM_ZONE_100ms_Group13_RC";
BA_ "LongName" SG_ 773 IIAM_ZONE_100ms_Group13_RC "Gnss Fix Type";
BA_ "SysSignalName" SG_ 773 IIAM_ZONE_100ms_Group13_RC "IAM_ZONE_100ms_Group13_RC";
BA_ "CompuMethodName" SG_ 773 IIAM_ZONE_100ms_Group13_Reserved "IAM_ZONE_100ms_Group13_Reserved1";
BA_ "GenSigStartValue" SG_ 773 IIAM_ZONE_100ms_Group13_Reserved 3;
BA_ "ISignalName" SG_ 773 IIAM_ZONE_100ms_Group13_Reserved "IIAM_ZONE_100ms_Group13_Reserved1";
BA_ "SysSignalName" SG_ 773 IIAM_ZONE_100ms_Group13_Reserved "IAM_ZONE_100ms_Group13_Reserved1";
BA_ "SystemSignalLongSymbol" SG_ 773 IIAM_ZONE_100ms_Group13_Reserved "IIAM_ZONE_100ms_Group13_Reserved1";
BA_ "CompuMethodName" SG_ 773 IFixType "FixType";
BA_ "ISignalName" SG_ 773 IFixType "IFixType";
BA_ "LongName" SG_ 773 IFixType "Gnss Fix Type";
BA_ "SysSignalName" SG_ 773 IFixType "FixType";
BA_ "CompuMethodName" SG_ 773 IGNSSSeq "GNSSSeq";
BA_ "ISignalName" SG_ 773 IGNSSSeq "IGNSSSeq";
BA_ "LongName" SG_ 773 IGNSSSeq "Gnss Messages Sequence";
BA_ "SysSignalName" SG_ 773 IGNSSSeq "GNSSSeq";
BA_ "CompuMethodName" SG_ 773 IGNSSUTCTimeH "GNSSUTCTimeH";
BA_ "ISignalName" SG_ 773 IGNSSUTCTimeH "IGNSSUTCTimeH";
BA_ "LongName" SG_ 773 IGNSSUTCTimeH "Gnss Utc Time F9H";
BA_ "SysSignalName" SG_ 773 IGNSSUTCTimeH "GNSSUTCTimeH";
BA_ "CompuMethodName" SG_ 974 IIAM_100ms_Group56_CRC "IAM_100ms_Group56_CRC";
BA_ "ISignalName" SG_ 974 IIAM_100ms_Group56_CRC "IIAM_100ms_Group56_CRC";
BA_ "LongName" SG_ 974 IIAM_100ms_Group56_CRC "IAM GNSS signal status";
BA_ "SysSignalName" SG_ 974 IIAM_100ms_Group56_CRC "IAM_100ms_Group56_CRC";
BA_ "CompuMethodName" SG_ 974 IIAM_100ms_Group56_RC "IAM_100ms_Group56_RC";
BA_ "ISignalName" SG_ 974 IIAM_100ms_Group56_RC "IIAM_100ms_Group56_RC";
BA_ "LongName" SG_ 974 IIAM_100ms_Group56_RC "IAM GNSS signal status";
BA_ "SysSignalName" SG_ 974 IIAM_100ms_Group56_RC "IAM_100ms_Group56_RC";
BA_ "CompuMethodName" SG_ 974 IIAM_100ms_Group56_Reserved1 "IAM_100ms_Group56_Reserved1";
BA_ "GenSigStartValue" SG_ 974 IIAM_100ms_Group56_Reserved1 3;
BA_ "ISignalName" SG_ 974 IIAM_100ms_Group56_Reserved1 "IIAM_100ms_Group56_Reserved1";
BA_ "SysSignalName" SG_ 974 IIAM_100ms_Group56_Reserved1 "IAM_100ms_Group56_Reserved1";
BA_ "CompuMethodName" SG_ 974 IIAM_GNSS_Signal_Status "IAM_GNSS_Signal_Status";
BA_ "ISignalName" SG_ 974 IIAM_GNSS_Signal_Status "IIAM_GNSS_Signal_Status";
BA_ "LongName" SG_ 974 IIAM_GNSS_Signal_Status "IAM GNSS signal status";
BA_ "SysSignalName" SG_ 974 IIAM_GNSS_Signal_Status "IAM_GNSS_Signal_Status";
BA_ "CompuMethodName" SG_ 974 ILatitudeRTK "LatitudeRTK";
BA_ "ISignalName" SG_ 974 ILatitudeRTK "ILatitudeRTK";
BA_ "LongName" SG_ 974 ILatitudeRTK "LatitudeRTK";
BA_ "SysSignalName" SG_ 974 ILatitudeRTK "LatitudeRTK";
BA_ "CompuMethodName" SG_ 974 IIAM_100ms_Group56_Reserved2 "IAM_100ms_Group56_Reserved2";
BA_ "GenSigStartValue" SG_ 974 IIAM_100ms_Group56_Reserved2 255;
BA_ "ISignalName" SG_ 974 IIAM_100ms_Group56_Reserved2 "IIAM_100ms_Group56_Reserved2";
BA_ "SysSignalName" SG_ 974 IIAM_100ms_Group56_Reserved2 "IAM_100ms_Group56_Reserved2";
BA_ "CompuMethodName" SG_ 179 IAPPPlnngPathLongdP1 "APPPlnngPathLongdP1";
BA_ "ISignalName" SG_ 179 IAPPPlnngPathLongdP1 "IAPPPlnngPathLongdP1";
BA_ "LongName" SG_ 179 IAPPPlnngPathLongdP1 "App_Planning_Path_Longitude_P1";
BA_ "SysSignalName" SG_ 179 IAPPPlnngPathLongdP1 "APPPlnngPathLongdP1";
BA_ "CompuMethodName" SG_ 179 IAPPPlnngPathLatdP1 "APPPlnngPathLatdP1";
BA_ "ISignalName" SG_ 179 IAPPPlnngPathLatdP1 "IAPPPlnngPathLatdP1";
BA_ "LongName" SG_ 179 IAPPPlnngPathLatdP1 "App_Planning_Path_Latitude_P1";
BA_ "SysSignalName" SG_ 179 IAPPPlnngPathLatdP1 "APPPlnngPathLatdP1";
BA_ "CompuMethodName" SG_ 179 IAPPPlnngPathLongdP2 "APPPlnngPathLongdP2";
BA_ "ISignalName" SG_ 179 IAPPPlnngPathLongdP2 "IAPPPlnngPathLongdP2";
BA_ "LongName" SG_ 179 IAPPPlnngPathLongdP2 "App_Planning_Path_Longitude_P2";
BA_ "SysSignalName" SG_ 179 IAPPPlnngPathLongdP2 "APPPlnngPathLongdP2";
BA_ "CompuMethodName" SG_ 179 IAPPPlnngPathLatdP2 "APPPlnngPathLatdP2";
BA_ "ISignalName" SG_ 179 IAPPPlnngPathLatdP2 "IAPPPlnngPathLatdP2";
BA_ "LongName" SG_ 179 IAPPPlnngPathLatdP2 "App_Planning_Path_Latitude_P2";
BA_ "SysSignalName" SG_ 179 IAPPPlnngPathLatdP2 "APPPlnngPathLatdP2";
BA_ "CompuMethodName" SG_ 179 IAPPPlnngPathLongdP3 "APPPlnngPathLongdP3";
BA_ "ISignalName" SG_ 179 IAPPPlnngPathLongdP3 "IAPPPlnngPathLongdP3";
BA_ "LongName" SG_ 179 IAPPPlnngPathLongdP3 "App_Planning_Path_Longitude_P3";
BA_ "SysSignalName" SG_ 179 IAPPPlnngPathLongdP3 "APPPlnngPathLongdP3";
BA_ "CompuMethodName" SG_ 179 IAPPPlnngPathLatdP3 "APPPlnngPathLatdP3";
BA_ "ISignalName" SG_ 179 IAPPPlnngPathLatdP3 "IAPPPlnngPathLatdP3";
BA_ "LongName" SG_ 179 IAPPPlnngPathLatdP3 "App_Planning_Path_Latitude_P3";
BA_ "SysSignalName" SG_ 179 IAPPPlnngPathLatdP3 "APPPlnngPathLatdP3";
BA_ "CompuMethodName" SG_ 179 IAPPPlnngPathLongdP4 "APPPlnngPathLongdP4";
BA_ "ISignalName" SG_ 179 IAPPPlnngPathLongdP4 "IAPPPlnngPathLongdP4";
BA_ "LongName" SG_ 179 IAPPPlnngPathLongdP4 "App_Planning_Path_Longitude_P4";
BA_ "SysSignalName" SG_ 179 IAPPPlnngPathLongdP4 "APPPlnngPathLongdP4";
BA_ "CompuMethodName" SG_ 179 IAPPPlnngPathLatdP4 "APPPlnngPathLatdP4";
BA_ "ISignalName" SG_ 179 IAPPPlnngPathLatdP4 "IAPPPlnngPathLatdP4";
BA_ "LongName" SG_ 179 IAPPPlnngPathLatdP4 "App_Planning_Path_Latitude_P4";
BA_ "SysSignalName" SG_ 179 IAPPPlnngPathLatdP4 "APPPlnngPathLatdP4";
BA_ "CompuMethodName" SG_ 179 IAPPPlnngPathLongdP5 "APPPlnngPathLongdP5";
BA_ "ISignalName" SG_ 179 IAPPPlnngPathLongdP5 "IAPPPlnngPathLongdP5";
BA_ "LongName" SG_ 179 IAPPPlnngPathLongdP5 "App_Planning_Path_Longitude_P5";
BA_ "SysSignalName" SG_ 179 IAPPPlnngPathLongdP5 "APPPlnngPathLongdP5";
BA_ "CompuMethodName" SG_ 179 IAPPPlnngPathLatdP5 "APPPlnngPathLatdP5";
BA_ "ISignalName" SG_ 179 IAPPPlnngPathLatdP5 "IAPPPlnngPathLatdP5";
BA_ "LongName" SG_ 179 IAPPPlnngPathLatdP5 "App_Planning_Path_Latitude_P5";
BA_ "SysSignalName" SG_ 179 IAPPPlnngPathLatdP5 "APPPlnngPathLatdP5";
BA_ "CompuMethodName" SG_ 159 IAPPPlnngPathLongdP6 "APPPlnngPathLongdP6";
BA_ "ISignalName" SG_ 159 IAPPPlnngPathLongdP6 "IAPPPlnngPathLongdP6";
BA_ "LongName" SG_ 159 IAPPPlnngPathLongdP6 "App_Planning_Path_Longitude_P6";
BA_ "SysSignalName" SG_ 159 IAPPPlnngPathLongdP6 "APPPlnngPathLongdP6";
BA_ "CompuMethodName" SG_ 159 IAPPPlnngPathLatdP6 "APPPlnngPathLatdP6";
BA_ "ISignalName" SG_ 159 IAPPPlnngPathLatdP6 "IAPPPlnngPathLatdP6";
BA_ "LongName" SG_ 159 IAPPPlnngPathLatdP6 "App_Planning_Path_Latitude_P6";
BA_ "SysSignalName" SG_ 159 IAPPPlnngPathLatdP6 "APPPlnngPathLatdP6";
BA_ "CompuMethodName" SG_ 159 IAPPPlnngPathLongdP7 "APPPlnngPathLongdP7";
BA_ "ISignalName" SG_ 159 IAPPPlnngPathLongdP7 "IAPPPlnngPathLongdP7";
BA_ "LongName" SG_ 159 IAPPPlnngPathLongdP7 "App_Planning_Path_Longitude_P7";
BA_ "SysSignalName" SG_ 159 IAPPPlnngPathLongdP7 "APPPlnngPathLongdP7";
BA_ "CompuMethodName" SG_ 159 IAPPPlnngPathLatdP7 "APPPlnngPathLatdP7";
BA_ "ISignalName" SG_ 159 IAPPPlnngPathLatdP7 "IAPPPlnngPathLatdP7";
BA_ "LongName" SG_ 159 IAPPPlnngPathLatdP7 "App_Planning_Path_Latitude_P7";
BA_ "SysSignalName" SG_ 159 IAPPPlnngPathLatdP7 "APPPlnngPathLatdP7";
BA_ "CompuMethodName" SG_ 159 IAPPPlnngPathLongdP8 "APPPlnngPathLongdP8";
BA_ "ISignalName" SG_ 159 IAPPPlnngPathLongdP8 "IAPPPlnngPathLongdP8";
BA_ "LongName" SG_ 159 IAPPPlnngPathLongdP8 "App_Planning_Path_Longitude_P8";
BA_ "SysSignalName" SG_ 159 IAPPPlnngPathLongdP8 "APPPlnngPathLongdP8";
BA_ "CompuMethodName" SG_ 159 IAPPPlnngPathLatdP8 "APPPlnngPathLatdP8";
BA_ "ISignalName" SG_ 159 IAPPPlnngPathLatdP8 "IAPPPlnngPathLatdP8";
BA_ "LongName" SG_ 159 IAPPPlnngPathLatdP8 "App_Planning_Path_Latitude_P8";
BA_ "SysSignalName" SG_ 159 IAPPPlnngPathLatdP8 "APPPlnngPathLatdP8";
BA_ "CompuMethodName" SG_ 159 IAPPPlnngPathLatdP9 "APPPlnngPathLatdP9";
BA_ "ISignalName" SG_ 159 IAPPPlnngPathLatdP9 "IAPPPlnngPathLatdP9";
BA_ "LongName" SG_ 159 IAPPPlnngPathLatdP9 "App_Planning_Path_Latitude_P9";
BA_ "SysSignalName" SG_ 159 IAPPPlnngPathLatdP9 "APPPlnngPathLatdP9";
BA_ "CompuMethodName" SG_ 159 IAPPPlnngPathLongdP9 "APPPlnngPathLongdP9";
BA_ "ISignalName" SG_ 159 IAPPPlnngPathLongdP9 "IAPPPlnngPathLongdP9";
BA_ "LongName" SG_ 159 IAPPPlnngPathLongdP9 "App_Planning_Path_Longitude_P9";
BA_ "SysSignalName" SG_ 159 IAPPPlnngPathLongdP9 "APPPlnngPathLongdP9";
BA_ "CompuMethodName" SG_ 159 IAPPPlnngPathLongdP10 "APPPlnngPathLongdP10";
BA_ "ISignalName" SG_ 159 IAPPPlnngPathLongdP10 "IAPPPlnngPathLongdP10";
BA_ "LongName" SG_ 159 IAPPPlnngPathLongdP10 "App_Planning_Path_Longitude_P10";
BA_ "SysSignalName" SG_ 159 IAPPPlnngPathLongdP10 "APPPlnngPathLongdP10";
BA_ "CompuMethodName" SG_ 159 IAPPPlnngPathLatdP10 "APPPlnngPathLatdP10";
BA_ "ISignalName" SG_ 159 IAPPPlnngPathLatdP10 "IAPPPlnngPathLatdP10";
BA_ "LongName" SG_ 159 IAPPPlnngPathLatdP10 "App_Planning_Path_Latitude_P10";
BA_ "SysSignalName" SG_ 159 IAPPPlnngPathLatdP10 "APPPlnngPathLatdP10";
BA_ "CompuMethodName" SG_ 125 ISumnLoctnLatd "SumnLoctnLatd";
BA_ "ISignalName" SG_ 125 ISumnLoctnLatd "ISumnLoctnLatd";
BA_ "LongName" SG_ 125 ISumnLoctnLatd "Summon_Location_Latitude";
BA_ "SysSignalName" SG_ 125 ISumnLoctnLatd "SumnLoctnLatd";
BA_ "CompuMethodName" SG_ 125 IAutodDrvngSysCtrlReq "AutodDrvngSysCtrlReq";
BA_ "ISignalName" SG_ 125 IAutodDrvngSysCtrlReq "IAutodDrvngSysCtrlReq";
BA_ "LongName" SG_ 125 IAutodDrvngSysCtrlReq "Automated_Driving_System_Control_Request";
BA_ "SysSignalName" SG_ 125 IAutodDrvngSysCtrlReq "AutodDrvngSysCtrlReq";
BA_ "CompuMethodName" SG_ 125 ISumnLoctnLongd "SumnLoctnLongd";
BA_ "ISignalName" SG_ 125 ISumnLoctnLongd "ISumnLoctnLongd";
BA_ "LongName" SG_ 125 ISumnLoctnLongd "Summon_Location_Longitude";
BA_ "SysSignalName" SG_ 125 ISumnLoctnLongd "SumnLoctnLongd";
BA_ "CompuMethodName" SG_ 348 IFCWSnstvtLvl "FCWSnstvtLvl";
BA_ "GenSigStartValue" SG_ 348 IFCWSnstvtLvl 2;
BA_ "ISignalName" SG_ 348 IFCWSnstvtLvl "IFCWSnstvtLvl";
BA_ "LongName" SG_ 348 IFCWSnstvtLvl "Forward Collision Warning Sensitivity Level";
BA_ "SysSignalName" SG_ 348 IFCWSnstvtLvl "FCWSnstvtLvl";
BA_ "CompuMethodName" SG_ 348 IAEBDspCmd "AEBDspCmd";
BA_ "GenSigStartValue" SG_ 348 IAEBDspCmd 2;
BA_ "ISignalName" SG_ 348 IAEBDspCmd "IAEBDspCmd";
BA_ "LongName" SG_ 348 IAEBDspCmd "Autonomous Emergency Braking Display Command";
BA_ "SysSignalName" SG_ 348 IAEBDspCmd "AEBDspCmd";
BA_ "CompuMethodName" SG_ 348 IAEBMsgReq "AEBMsgReq";
BA_ "ISignalName" SG_ 348 IAEBMsgReq "IAEBMsgReq";
BA_ "LongName" SG_ 348 IAEBMsgReq "Autonomous Emergency Braking Message Request";
BA_ "SysSignalName" SG_ 348 IAEBMsgReq "AEBMsgReq";
BA_ "CompuMethodName" SG_ 348 IFCWDspCmd "FCWDspCmd";
BA_ "GenSigStartValue" SG_ 348 IFCWDspCmd 2;
BA_ "ISignalName" SG_ 348 IFCWDspCmd "IFCWDspCmd";
BA_ "LongName" SG_ 348 IFCWDspCmd "Forward Collision Warning Display Command";
BA_ "SysSignalName" SG_ 348 IFCWDspCmd "FCWDspCmd";
BA_ "CompuMethodName" SG_ 348 IFCWSysFltSts "FCWSysFltSts";
BA_ "ISignalName" SG_ 348 IFCWSysFltSts "IFCWSysFltSts";
BA_ "LongName" SG_ 348 IFCWSysFltSts "Forward Collision Warning System Fault Status";
BA_ "SysSignalName" SG_ 348 IFCWSysFltSts "FCWSysFltSts";
BA_ "CompuMethodName" SG_ 348 IFCWrnngSts "FCWrnngSts";
BA_ "ISignalName" SG_ 348 IFCWrnngSts "IFCWrnngSts";
BA_ "LongName" SG_ 348 IFCWrnngSts "Forward Collision Warning Status";
BA_ "SysSignalName" SG_ 348 IFCWrnngSts "FCWrnngSts";
BA_ "CompuMethodName" SG_ 348 IRembMapBldngQnty "RembMapBldngQnty";
BA_ "ISignalName" SG_ 348 IRembMapBldngQnty "IRembMapBldngQnty";
BA_ "LongName" SG_ 348 IRembMapBldngQnty "Remember Map Building Quantity";
BA_ "SysSignalName" SG_ 348 IRembMapBldngQnty "RembMapBldngQnty";
BA_ "CompuMethodName" SG_ 348 IRembMapBldngReq "RembMapBldngReq";
BA_ "ISignalName" SG_ 348 IRembMapBldngReq "IRembMapBldngReq";
BA_ "LongName" SG_ 348 IRembMapBldngReq "Remember Map Building Request";
BA_ "SysSignalName" SG_ 348 IRembMapBldngReq "RembMapBldngReq";
BA_ "CompuMethodName" SG_ 348 IRembParkngPrgs "RembParkngPrgs";
BA_ "ISignalName" SG_ 348 IRembParkngPrgs "IRembParkngPrgs";
BA_ "LongName" SG_ 348 IRembParkngPrgs "Remember Parking Progress";
BA_ "SysSignalName" SG_ 348 IRembParkngPrgs "RembParkngPrgs";
BA_ "CompuMethodName" SG_ 348 IMapListResp "MapListResp";
BA_ "ISignalName" SG_ 348 IMapListResp "IMapListResp";
BA_ "LongName" SG_ 348 IMapListResp "Map List Response";
BA_ "SysSignalName" SG_ 348 IMapListResp "MapListResp";
BA_ "CompuMethodName" SG_ 348 IAvlblMaps "AvlblMaps";
BA_ "ISignalName" SG_ 348 IAvlblMaps "IAvlblMaps";
BA_ "LongName" SG_ 348 IAvlblMaps "Available Maps";
BA_ "SysSignalName" SG_ 348 IAvlblMaps "AvlblMaps";
BA_ "CompuMethodName" SG_ 348 IRembBldMapReq "RembBldMapReq";
BA_ "ISignalName" SG_ 348 IRembBldMapReq "IRembBldMapReq";
BA_ "LongName" SG_ 348 IRembBldMapReq "Remember Build Map Request";
BA_ "SysSignalName" SG_ 348 IRembBldMapReq "RembBldMapReq";
BA_ "CompuMethodName" SG_ 348 IFCTSysFltSts "FCTSysFltSts";
BA_ "ISignalName" SG_ 348 IFCTSysFltSts "IFCTSysFltSts";
BA_ "LongName" SG_ 348 IFCTSysFltSts "FCTA/B System Fault status";
BA_ "SysSignalName" SG_ 348 IFCTSysFltSts "FCTSysFltSts";
BA_ "CompuMethodName" SG_ 348 IFCTSwSts "FCTSwSts";
BA_ "GenSigStartValue" SG_ 348 IFCTSwSts 1;
BA_ "ISignalName" SG_ 348 IFCTSwSts "IFCTSwSts";
BA_ "LongName" SG_ 348 IFCTSwSts "FCTA/B  Switch status";
BA_ "SysSignalName" SG_ 348 IFCTSwSts "FCTSwSts";
BA_ "CompuMethodName" SG_ 348 ILFCTWrnng "LFCTWrnng";
BA_ "ISignalName" SG_ 348 ILFCTWrnng "ILFCTWrnng";
BA_ "LongName" SG_ 348 ILFCTWrnng "Left_FCTA/B_Warning";
BA_ "SysSignalName" SG_ 348 ILFCTWrnng "LFCTWrnng";
BA_ "CompuMethodName" SG_ 348 IRFCTWrnng "RFCTWrnng";
BA_ "ISignalName" SG_ 348 IRFCTWrnng "IRFCTWrnng";
BA_ "LongName" SG_ 348 IRFCTWrnng "Right_FCTA/B_Warning";
BA_ "SysSignalName" SG_ 348 IRFCTWrnng "RFCTWrnng";
BA_ "CompuMethodName" SG_ 917 IAIPiloTIntervQuit "AIPiloTIntervQuit";
BA_ "ISignalName" SG_ 917 IAIPiloTIntervQuit "IAIPiloTIntervQuit";
BA_ "LongName" SG_ 917 IAIPiloTIntervQuit "Ai Pilot Intervene Quit";
BA_ "SysSignalName" SG_ 917 IAIPiloTIntervQuit "AIPiloTIntervQuit";
BA_ "CompuMethodName" SG_ 917 IAIParkngDsp "AIParkngDsp";
BA_ "ISignalName" SG_ 917 IAIParkngDsp "IAIParkngDsp";
BA_ "LongName" SG_ 917 IAIParkngDsp "Ai Parking Display";
BA_ "SysSignalName" SG_ 917 IAIParkngDsp "AIParkngDsp";
BA_ "CompuMethodName" SG_ 917 IAIParkngSts "AIParkngSts";
BA_ "ISignalName" SG_ 917 IAIParkngSts "IAIParkngSts";
BA_ "LongName" SG_ 917 IAIParkngSts "Ai Parking Status";
BA_ "SysSignalName" SG_ 917 IAIParkngSts "AIParkngSts";

VAL_ 1319 IAIParkngSpcID 0 "AIParkngSpcID_0_NoRequest" 1 "AIParkngSpcID_1_ParktoParkingSpaceID1" 2 "AIParkngSpcID_2_ParktoParkingSpaceID2" 3 "AIParkngSpcID_3_ParktoParkingSpaceID3" 4 "AIParkngSpcID_4_ParktoParkingSpaceID4" 5 "AIParkngSpcID_5_ParktoParkingSpaceID5" 6 "AIParkngSpcID_6_ParktoParkingSpaceID6" 7 "AIParkngSpcID_7_ParktoParkingSpaceID7" 8 "AIParkngSpcID_8_ParktoParkingSpaceID8" 9 "AIParkngSpcID_9_ParktoParkingSpaceID9" 10 "AIParkngSpcID_10_ParktoParkingSpaceID10" 11 "AIParkngSpcID_11_ParktoParkingSpaceID11" 12 "AIParkngSpcID_12_ParktoParkingSpaceID12" 13 "AIParkngSpcID_13_ParktoParkingSpaceID13" 14 "AIParkngSpcID_14_ParktoParkingSpaceID14" 15 "AIParkngSpcID_15_ParktoParkingSpaceID15" 16 "AIParkngSpcID_16_ParktoParkingSpaceID16" 17 "AIParkngSpcID_17_ParktoDIYSpace";
VAL_ 1001 IEPTClntPumpSta 0 "EPTCIntPumpSta_0_Initial" 1 "EPTCIntPumpSta_1__NormalOn" 2 "EPTCIntPumpSta_2_NormalOff" 3 "EPTCIntPumpSta_3_OverTem" 4 "EPTCIntPumpSta_4_OVerCrnt" 5 "EPTCIntPumpSta_5__Dry" 6 "EPTCIntPumpSta_6_Stall" 7 "EPTCIntPumpSta_7_CommErr" 8 "EPTCIntPumpSta_8_OpenCircle" 9 "EPTCIntPumpSta_9_ShortCircle" 10 "EPTCIntPumpSta_10_Driver_error" 11 "EPTCIntPumpSta_11_OverPwr";
VAL_ 1001 IESSClntPumpSta 0 "ESSCIntPumpSta_0_Initial" 1 "ESSCIntPumpSta_1_NormalOn" 2 "ESSCIntPumpSta_2_NormalOff" 3 "ESSCIntPumpSta_3_OverTem" 4 "ESSCIntPumpSta_4_OVerCrnt" 5 "ESSCIntPumpSta_5_Dry" 6 "ESSCIntPumpSta_6_Stall" 7 "ESSCIntPumpSta_7_CommErr" 8 "ESSCIntPumpSta_8_OpenCircle" 9 "ESSCIntPumpSta_9_ShortCircle" 10 "ESSCIntPumpSta_10_Driver_error" 11 "ESSCIntPumpSta_11_OverPwr";
VAL_ 1001 IEPTElecWtrPumpTrgtSpd 255 "EPTElecWtrPumpTrgtSpd_255_invalid";
VAL_ 1001 IESSElecWtrPumpTrgtSpd 255 "ESSElecWtrPumpTrgtSpd_255_invalid";
VAL_ 1001 ICoolngFanWorkSta 0 "CoolngFanWorkSta_0_Normal_Work" 1 "CoolngFanWorkSta_1_Cooling_Fan_Short_Circuit_to_GND" 2 "CoolngFanWorkSta_2_Cooling_Fan_Short_Circuit_to_Batt" 3 "CoolngFanWorkSta_3_Cooling_Fan_Open_Circuit" 4 "CoolngFanWorkSta_4_Cooling_Fan_PCB_over_temperature" 5 "CoolngFanWorkSta_5_Cooling_Fan_Stall_Detected" 6 "CoolngFanWorkSta_6_Cooling_Fan_PreDriver_error" 7 "CoolngFanWorkSta_7_Cooling_Fan_Over_Current" 8 "CoolngFanWorkSta_8_Cooling_Fan_Over_Voltage" 9 "CoolngFanWorkSta_9_Cooling_Fan_Under_Voltage" 10 "CoolngFanWorkSta_10_Cooling_Fan_Over_Speed" 11 "CoolngFanWorkSta_11_Cooling_Fan_PreDriver_over_temperature";
VAL_ 1001 ILowTemWtrPumpTrgtSpd 255 "LowTemWtrPumpTrgtSpd_255_invalid";
VAL_ 898 IFDRSts 0 "FDRSts_0_normal" 1 "FDRSts_1_blindness" 2 "FDRSts_2_misalignment" 3 "FDRSts_3_other_error";
VAL_ 1254 IFDR_NM_BSMtoRMS_BKPCANFD 0 "FDR_NM_BSMtoRMS_BKPCANFD_0_FDR_NM_BSMtoRMS_0_False" 1 "FDR_NM_BSMtoRMS_BKPCANFD_1_FDR_NM_BSMtoRMS_1_True";
VAL_ 1254 IFDR_NM_PBSMtoRMS_BKPCANFD 0 "FDR_NM_PBSMtoRMS_BKPCANFD_0_FDR_NM_PBSMtoRMS_0_False" 1 "FDR_NM_PBSMtoRMS_BKPCANFD_1_FDR_NM_PBSMtoRMS_1_True";
VAL_ 1254 IFDR_NM_RMStoNOS_BKPCANFD 0 "FDR_NM_RMStoNOS_BKPCANFD_0_FDR_NM_RMStoNOS_0_False" 1 "FDR_NM_RMStoNOS_BKPCANFD_1_FDR_NM_RMStoNOS_1_True";
VAL_ 1254 IFDR_NM_RSStoNOS_BKPCANFD 0 "FDR_NM_RSStoNOS_BKPCANFD_0_FDR_NM_RSStoNOS_0_False" 1 "FDR_NM_RSStoNOS_BKPCANFD_1_FDR_NM_RSStoNOS_1_True";
VAL_ 1254 IFDR_NM_RSStoRMS_BKPCANFD 0 "FDR_NM_RSStoRMS_BKPCANFD_0_FDR_NM_RSStoRMS_0_False" 1 "FDR_NM_RSStoRMS_BKPCANFD_1_FDR_NM_RSStoRMS_1_True";
VAL_ 1254 IFDR_NM_NOStoRMS_BKPCANFD 0 "FDR_NM_NOStoRMS_BKPCANFD_0_FDR_NM_NOStoRMS_0_False" 1 "FDR_NM_NOStoRMS_BKPCANFD_1_FDR_NM_NOStoRMS_1_True";
VAL_ 1254 IFDR_NM_NOSSta_BKPCANFD 0 "FDR_NM_NOSSta_BKPCANFD_0_FDR_NM_NOSSta_0_False" 1 "FDR_NM_NOSSta_BKPCANFD_1_FDR_NM_NOSSta_1_True";
VAL_ 1254 IFDR_NM_RMSSta_BKPCANFD 0 "FDR_NM_RMSSta_BKPCANFD_0_FDR_NM_RMSSta_0_False" 1 "FDR_NM_RMSSta_BKPCANFD_1_FDR_NM_RMSSta_1_True";
VAL_ 1254 IFDR_NWI_BKPCANFD 0 "FDR_NWI_BKPCANFD_0_NoWakeNetworkSource";
VAL_ 1254 IFDR_NOI_BKPCANFD 0 "FDR_NOI_BKPCANFD_0_NoRequest" 65535 "FDR_NOI_BKPCANFD_65535_AllNetworkOperationActive";
VAL_ 1254 IFDR_NKI_BKPCANFD 0 "FDR_NKI_BKPCANFD_0_NoRequest" 1 "FDR_NKI_BKPCANFD_1_PowerModeIsNonOFF";
VAL_ 139 IFDRTripCtrRstResp 0 "FDRTripCtrRstResp_0_Failed" 1 "FDRTripCtrRstResp_1_Success";
VAL_ 139 IFDRComKeyEnbResp 0 "FDRComKeyEnbResp_0_Failed" 1 "FDRComKeyEnbResp_1_Success";
VAL_ 958 IACCConfmSw 0 "ACCConfmSw_0_unavailable" 1 "ACCConfmSw_1_NoConfirm" 2 "ACCConfmSw_2_Confirm" 3 "ACCConfmSw_3_Reserve";
VAL_ 958 IELKWarning 0 "ELKWarning_0_LRoadedge" 1 "ELKWarning_1_RRoadedge" 2 "ELKWarning_2_LOncoming" 3 "ELKWarning_3_ROncoming" 4 "ELKWarning_4_LOvertaking" 5 "ELKWarning_5_ROvertaking" 6 "ELKWarning_6_no_warning" 7 "ELKWarning_7_Reserve2";
VAL_ 958 IACCDrvrTkovReq 0 "ACCDrvrTkovReq_0_False" 1 "ACCDrvrTkovReq_1_True";
VAL_ 956 IPilotSysMsg 0 "PilotSysMsg_0_No_display" 1 "PilotSysMsg_1_ACC_Active" 2 "PilotSysMsg_2_ACC_Exit" 3 "PilotSysMsg_3_LCC_Active" 4 "PilotSysMsg_4_LCC_UpgradeFromACC" 5 "PilotSysMsg_5_LCC_DegradationToACC" 6 "PilotSysMsg_6_LCC_Exit" 7 "PilotSysMsg_7_NOA_Active" 8 "PilotSysMsg_8_NOA_Upgrade" 9 "PilotSysMsg_9_NOA_DegradationToLCC" 10 "PilotSysMsg_10_NOA_DegradationToACC" 11 "PilotSysMsg_11_NOA_Exit" 12 "PilotSysMsg_12_Reserved" 13 "PilotSysMsg_13_Reserved" 14 "PilotSysMsg_14_Reserved" 15 "PilotSysMsg_15_Reserved";
VAL_ 956 ITLRMsgReq 0 "TLRMsgReq_0_NoDisplay" 1 "TLRMsgReq_1_Countdown" 2 "TLRMsgReq_2_Reserved" 3 "TLRMsgReq_3_Reserved";
VAL_ 956 ILane0_location 0 "Lane0_location_0_Left" 1 "Lane0_location_1_Right" 2 "Lane0_location_2_NextLeft" 3 "Lane0_location_3_NextRight";
VAL_ 956 ITLRSysSts 0 "TLRSysSts_0_Off" 1 "TLRSysSts_1_StandBy" 2 "TLRSysSts_2_Active" 3 "TLRSysSts_3_Error";
VAL_ 956 ILane1_location 0 "Lane1_location_0_Left" 1 "Lane1_location_1_Right" 2 "Lane1_location_2_NextLeft" 3 "Lane1_location_3_NextRight";
VAL_ 956 ITrgtSpdSrcSts_IPD 0 "TrgtSpdSrcSts_IPD_0_Undefined" 1 "TrgtSpdSrcSts_IPD_1_Camera" 2 "TrgtSpdSrcSts_IPD_2_Navigation" 3 "TrgtSpdSrcSts_IPD_3_Fault";
VAL_ 956 ISLIFWrnngMdResp 0 "SLIFWrnngMdResp_0__Unavailable" 1 "SLIFWrnngMdResp_1__Off" 2 "SLIFWrnngMdResp_2__Visual" 3 "SLIFWrnngMdResp_3___Audible";
VAL_ 956 ITLRWarning 0 "TLRWarning_0_NoRequest" 1 "TLRWarning_1_GreenLightStartAlert_lvl1" 2 "TLRWarning_2_GreenLightStartAlert_lvl2" 3 "TLRWarning_3_RedLightRunAlert_lvl1" 4 "TLRWarning_4_RedLightRunAlert_lvl2" 5 "TLRWarning_5_Reserved" 6 "TLRWarning_6_Reserved";
VAL_ 956 ITLRMdSwDspCmd 0 "TLRMdSwDspCmd_0_unavailable" 1 "TLRMdSwDspCmd_1_TLR_on" 2 "TLRMdSwDspCmd_2_TLR_off" 3 "TLRMdSwDspCmd_3_TLR_alert_off" 4 "TLRMdSwDspCmd_4_TLR_alert_on" 5 "TLRMdSwDspCmd_5_Reserved" 6 "TLRMdSwDspCmd_6_Reserved";
VAL_ 956 ISLIFAudWrnng_IPD 0 "SLIFAudWrnng_IPD_0__False" 1 "SLIFAudWrnng_IPD_1__True";
VAL_ 956 ISLIFUpdtIndResp_IPD 0 "SLIFUpdtIndResp_IPD_0__Off" 1 "SLIFUpdtIndResp_IPD_1__On";
VAL_ 956 ISLIFUpdtInd_IPD 0 "SLIFUpdtInd_IPD_0__False" 1 "SLIFUpdtInd_IPD_1__True";
VAL_ 956 ICCSpdVcCmdCnfm 0 "CCSpdVcCmdCnfm_0_NoResponse" 1 "CCSpdVcCmdCnfm_1_SpeedIsConfirmed" 2 "CCSpdVcCmdCnfm_2_DistanceIsConfirmed" 3 "CCSpdVcCmdCnfm_3_NotInTheRange" 4 "CCSpdVcCmdCnfm_4_AlreadyInMaximunRange" 5 "CCSpdVcCmdCnfm_5_AlreadyInMinimumRange" 6 "CCSpdVcCmdCnfm_6_ACCisActived" 7 "CCSpdVcCmdCnfm_7_ACCisDeactived";
VAL_ 307 IACCDrvrSelTrgtSpd 0 "ACCDrvrSelTrgtSpd_0_no_speed_set";
VAL_ 307 IACCGoNotfr 0 "ACCGoNotfr_0_False" 1 "ACCGoNotfr_1_True";
VAL_ 307 IACCDetObjDistLvl 0 "ACCDetObjDistLvl_0_NoGapSet" 1 "ACCDetObjDistLvl_1_DistanceLevel1" 2 "ACCDetObjDistLvl_2_DistanceLevel2" 3 "ACCDetObjDistLvl_3_DistanceLevel3" 4 "ACCDetObjDistLvl_4_DistanceLevel4" 5 "ACCDetObjDistLvl_5_DistanceLevel5" 6 "ACCDetObjDistLvl_6_reserved" 7 "ACCDetObjDistLvl_7_reserved";
VAL_ 307 IELKSysSts_IPD 0 "ELKSysSts_0_off" 1 "ELKSysSts_1_Passive" 2 "ELKSysSts_2_Stand_by" 3 "ELKSysSts_3_Active_Roadedge" 4 "ELKSysSts_4_Active_Oncoming" 5 "ELKSysSts_5_Active_Overtaking" 6 "ELKSysSts_6_Overrride" 7 "ELKSysSts_7_Error" 8 "ELKSysSts_8_Reserve";
VAL_ 307 IACCTJAMdSwDspCmd 0 "ACCTJAMdSwDspCmd_0_unavailable" 1 "ACCTJAMdSwDspCmd_1_ACC" 2 "ACCTJAMdSwDspCmd_2_TJA" 3 "ACCTJAMdSwDspCmd_3_SHWA" 4 "ACCTJAMdSwDspCmd_4_Off" 5 "ACCTJAMdSwDspCmd_5_Reserved" 6 "ACCTJAMdSwDspCmd_6_Reserved" 7 "ACCTJAMdSwDspCmd_7_Reserved";
VAL_ 307 IACCSeldTrgtDistLvl 0 "ACCSeldTrgtDistLvl_0_NoGapSet" 1 "ACCSeldTrgtDistLvl_1_DistanceLevel1" 2 "ACCSeldTrgtDistLvl_2_DistanceLevel2" 3 "ACCSeldTrgtDistLvl_3_DistanceLevel3" 4 "ACCSeldTrgtDistLvl_4_DistanceLevel4" 5 "ACCSeldTrgtDistLvl_5_DistanceLevel5";
VAL_ 307 IHandOffStrgWhlDetnSta 0 "HandOffStrgWhlDetnSta_0_Hands_Off_level_1" 1 "HandOffStrgWhlDetnSta_1_Hands_On" 2 "HandOffStrgWhlDetnSta_2_Hands_Off_level_2" 3 "HandOffStrgWhlDetnSta_3_Hands_Off_level_3";
VAL_ 307 IILCActvnDircnDspCmd 0 "ILCActvnDircnDspCmd_0_Unavailable" 1 "ILCActvnDircnDspCmd_1_IlcNotActive" 2 "ILCActvnDircnDspCmd_2_IlcActiveLeft" 3 "ILCActvnDircnDspCmd_3_IlcActiveRight";
VAL_ 307 IILCSwDspCmd 0 "ILCSwDspCmd_0_unavailable" 1 "ILCSwDspCmd_1_off" 2 "ILCSwDspCmd_2_on" 3 "ILCSwDspCmd_3_reserved";
VAL_ 307 IILCSysSts 0 "ILCSysSts_0_Off" 1 "ILCSysSts_1_Failure" 2 "ILCSysSts_2_Standby" 3 "ILCSysSts_3_Passive" 4 "ILCSysSts_4_ActiveRequest" 5 "ILCSysSts_5_ActiveControl" 6 "ILCSysSts_6_Reserved" 7 "ILCSysSts_7_Reserved";
VAL_ 307 IILCActvnVelDspCmd 0 "ILCActvnVelDspCmd_0_Unavailable" 1 "ILCActvnVelDspCmd_1_IlcNotActive" 2 "ILCActvnVelDspCmd_2_IlcAcceleration" 3 "ILCActvnVelDspCmd_3_IlcDeceleration";
VAL_ 307 IHandOffStrgWhlDetnStaV 0 "HandOffStrgWhlDetnStaV_0_Valid" 1 "HandOffStrgWhlDetnStaV_1_Invalid";
VAL_ 307 ILDWLKAAudReq 0 "LDWLKAAudReq_0_LDWLKAAudReq_0_no_request" 1 "LDWLKAAudReq_1_LDWLKAAudReq_1_level_1" 2 "LDWLKAAudReq_2_LDWLKAAudReq_2_level_2" 3 "LDWLKAAudReq_3_LDWLKAAudReq_3_level_3";
VAL_ 307 ILDWAdoWrnngDspCmd 0 "LDWAdoWrnngDspCmd_0_LDWAdoWrnngDspCmd_0_Unavailable" 1 "LDWAdoWrnngDspCmd_1_LDWAdoWrnngDspCmd_1_off" 2 "LDWAdoWrnngDspCmd_2_LDWAdoWrnngDspCmd_2_on";
VAL_ 307 ILDWLKADspCmd 0 "LDWLKADspCmd_0_LDWLKADspCmd_0_Unavailable" 1 "LDWLKADspCmd_1_LDWLKADspCmd_1_off" 2 "LDWLKADspCmd_2_LDWLKADspCmd_2_LDW" 3 "LDWLKADspCmd_3_LDWLKADspCmd_3_LDP" 4 "LDWLKADspCmd_4_LDWLKADspCmd_4_LKA";
VAL_ 307 ILKADrvrTkovReq 0 "LKADrvrTkovReq_0_False" 1 "LKADrvrTkovReq_1_True";
VAL_ 307 ILDWSnstvtLvl 0 "LDWSnstvtLvl_0_LDWSnstvtLvl_0_unavailable" 1 "LDWSnstvtLvl_1_LDWSnstvtLvl_1_Low" 2 "LDWSnstvtLvl_2_LDWSnstvtLvl_2_Standard" 3 "LDWSnstvtLvl_3_LDWSnstvtLvl_3_High";
VAL_ 307 ILDWLKAHptWrnngDspCmd 0 "LDWLKAHptWrnngDspCmd_0_LDWLKAHptWrnngDspCmd_0_unavailable" 1 "LDWLKAHptWrnngDspCmd_1_LDWLKAHptWrnngDspCmd_1_off" 2 "LDWLKAHptWrnngDspCmd_2_LDWLKAHptWrnngDspCmd_2_on";
VAL_ 307 IACCMsgReq 0 "ACCMsgReq_0_NoDisplay" 1 "ACCMsgReq_1_Speed_is_lower_than_boundary" 2 "ACCMsgReq_2_active_failed_because_of_Handoff_Prohibition" 3 "ACCMsgReq_3_go_notifier_between_10s_and_50s" 4 "ACCMsgReq_4_go_notifier_between_50s_and_300s" 5 "ACCMsgReq_5_system_fault" 6 "ACCMsgReq_6_Reserved" 7 "ACCMsgReq_7_TCS_or_VSE_off" 8 "ACCMsgReq_8_Brake_pedal_is_not_pressed_when_vehicle_is_standstill" 9 "ACCMsgReq_9_Brake_pedal_is_not_released_during_driving" 10 "ACCMsgReq_10_Speed_is_out_of_boundary" 11 "ACCMsgReq_11_EPB_applied" 12 "ACCMsgReq_12_shift_is_not_in_D" 13 "ACCMsgReq_13_door_or_bonnet_is_open" 14 "ACCMsgReq_14_Driver_Seatbelt_released" 15 "ACCMsgReq_15_Driver_mode_not_support" 16 "ACCMsgReq_16_Reserve" 17 "ACCMsgReq_17_Reserve" 18 "ACCMsgReq_18_Reserve" 19 "ACCMsgReq_19_Reserve" 20 "ACCMsgReq_20_Reserve" 21 "ACCMsgReq_21_Reserve" 22 "ACCMsgReq_22_Reserve" 23 "ACCMsgReq_23_Reserve" 24 "ACCMsgReq_24_Reserve" 25 "ACCMsgReq_25_Reserve" 26 "ACCMsgReq_26_Reserve" 27 "ACCMsgReq_27_Reserve" 28 "ACCMsgReq_28_Reserve" 29 "ACCMsgReq_29_Reserve" 30 "ACCMsgReq_30_Reserve" 31 "ACCMsgReq_31_Reserve";
VAL_ 747 IKeepPwrRsnFVCM 0 "KeepPwrRsnFVCM_0_Unknown" 1 "KeepPwrRsnFVCM_1_Off" 2 "KeepPwrRsnFVCM_2_On" 3 "KeepPwrRsnFVCM_3_Reserved" 4 "KeepPwrRsnFVCM_4_Reserved" 5 "KeepPwrRsnFVCM_5_Reserved" 6 "KeepPwrRsnFVCM_6_Reserved" 7 "KeepPwrRsnFVCM_7_Reserved" 8 "KeepPwrRsnFVCM_8_Reserved" 9 "KeepPwrRsnFVCM_9_GoingDown" 10 "KeepPwrRsnFVCM_10_off_SuperECO" 11 "KeepPwrRsnFVCM_11_Reserved" 12 "KeepPwrRsnFVCM_12_Reserved" 13 "KeepPwrRsnFVCM_13_Reserved" 14 "KeepPwrRsnFVCM_14_Reserved" 15 "KeepPwrRsnFVCM_15_Reserved";
VAL_ 747 ITLRTrafficLightsCircleDsp 0 "TLRTrafficLightsCircleDsp_0_NoDisplay" 1 "TLRTrafficLightsCircleDsp_1_red" 2 "TLRTrafficLightsCircleDsp_2_yellow" 3 "TLRTrafficLightsCircleDsp_3_green";
VAL_ 298 IP2PExeAvlblV 0 "P2PExeAvlblV_0_Valid" 1 "P2PExeAvlblV_1_Invalid";
VAL_ 298 IP2PExeAvlbl 0 "P2PExeAvlbl_0_unavailable" 1 "P2PExeAvlbl_1_available";
VAL_ 700 IIAMtoIPD_Rsrv01 0 "IAMtoIPD_Rsrv01_0_Reserved" 1 "IAMtoIPD_Rsrv01_1_Reserved" 2 "IAMtoIPD_Rsrv01_2_Reserved" 3 "IAMtoIPD_Rsrv01_3_Reserved";
VAL_ 700 IIAMtoIPD_Rsrv02 0 "IAMtoIPD_Rsrv01_0_Reserved" 1 "IAMtoIPD_Rsrv01_1_Reserved" 2 "IAMtoIPD_Rsrv01_2_Reserved" 3 "IAMtoIPD_Rsrv01_3_Reserved";
VAL_ 700 IIAMtoIPD_Rsrv03 0 "IAMtoIPD_Rsrv01_0_Reserved" 1 "IAMtoIPD_Rsrv01_1_Reserved" 2 "IAMtoIPD_Rsrv01_2_Reserved" 3 "IAMtoIPD_Rsrv01_3_Reserved";
VAL_ 336 IRmtParkngAstParkngOutDircnSeln 0 "RmtParkngAstParkngOutDircnSeln_0_none" 1 "RmtParkngAstParkngOutDircnSeln_1_FrontLeftCross" 2 "RmtParkngAstParkngOutDircnSeln_2_FrontLeftParallel" 3 "RmtParkngAstParkngOutDircnSeln_3_FrontOut" 4 "RmtParkngAstParkngOutDircnSeln_4_FrontRightCross" 5 "RmtParkngAstParkngOutDircnSeln_5_FrontRightParallel" 6 "RmtParkngAstParkngOutDircnSeln_6_BackOut" 7 "RmtParkngAstParkngOutDircnSeln_7_BackLeftCross" 8 "RmtParkngAstParkngOutDircnSeln_8_BackRightCross";
VAL_ 336 IRmtParkngAstBtnSts 0 "RmtParkngAstBtnSts_0_NotPressed" 1 "RmtParkngAstBtnSts_1_Pressed";
VAL_ 336 IVehFwdSwReq 0 "VehFwdSwReq_0_NoReq" 1 "VehFwdSwReq_1_Slow" 2 "VehFwdSwReq_2_Normal" 3 "VehFwdSwReq_3_Fast";
VAL_ 336 IVehBkwdSwReq 0 "VehBkwdSwReq_0_NoReq" 1 "VehBkwdSwReq_1_Slow" 2 "VehBkwdSwReq_2_Normal" 3 "VehBkwdSwReq_3_Fast";
VAL_ 336 IRmtParkngAstDvcSts 0 "RmtParkngAstDvcSts_0_RD_Inactive" 1 "RmtParkngAstDvcSts_1_RD_Ready" 2 "RmtParkngAstDvcSts_2_RD_Active" 3 "RmtParkngAstDvcSts_3_RD_Fault" 4 "RmtParkngAstDvcSts_4_Reserved";
VAL_ 89 IIAMReststs 0 "IAMReststs_0_reserved" 1 "IAMReststs_1_Restarting";
VAL_ 1000 ISmtKeyAuthnSubModRunSts 0 "SmtKeyAuthnSubModRunSts_0_Initialization" 1 "SmtKeyAuthnSubModRunSts_1_Running" 2 "SmtKeyAuthnSubModRunSts_2_ResponseSucess" 3 "SmtKeyAuthnSubModRunSts_3_Failure_Attack" 4 "SmtKeyAuthnSubModRunSts_4_Failure_NoChallenge" 5 "SmtKeyAuthnSubModRunSts_5_Failure_NoCipher" 6 "SmtKeyAuthnSubModRunSts_6_Reserved" 7 "SmtKeyAuthnSubModRunSts_7_Reserved";
VAL_ 1000 ITgtRembParkngChosenSpcID 0 "TgtRembParkngChosenSpcID_0_TgtParkngSpcID_0_NoTargetId" 1 "TgtRembParkngChosenSpcID_1_TgtParkngSpcID_1_TargetId1" 2 "TgtRembParkngChosenSpcID_2_TgtParkngSpcID_2_TargetId2" 3 "TgtRembParkngChosenSpcID_3_TgtParkngSpcID_3_TargetId3" 4 "TgtRembParkngChosenSpcID_4_TgtParkngSpcID_4_TargetId4" 5 "TgtRembParkngChosenSpcID_5_TgtParkngSpcID_5_TargetId5" 6 "TgtRembParkngChosenSpcID_6_TgtParkngSpcID_6_TargetId6" 7 "TgtRembParkngChosenSpcID_7_TgtParkngSpcID_7_TargetId7" 8 "TgtRembParkngChosenSpcID_8_TgtParkngSpcID_8_TargetId8";
VAL_ 1358 IKeyDeleResp 0 "KeyDeleResp_0_default" 1 "KeyDeleResp_1_success" 2 "KeyDeleResp_2_IAM_No_key" 3 "KeyDeleResp_3_IAMsystemfault" 4 "KeyDeleResp_4_TSPfault" 5 "KeyDeleResp_5_timeout" 6 "KeyDeleResp_6_TSP_No_key" 7 "KeyDeleResp_7_VehicleMinusCloud_Link_Failure" 15 "KeyDeleResp_15_reserve";
VAL_ 1358 IAIParkngReq 0 "AIParkngReq_0_NoRequest" 1 "AIParkngReq_1_Start_Parking_in" 2 "AIParkngReq_2_Start_Parking_out" 3 "AIParkngReq_3_Pause" 4 "AIParkngReq_4_Continue" 5 "AIParkngReq_5_Cancel" 7 "AIParkngReq_7_Left_Parking_out" 8 "AIParkngReq_8_Right_Parking_out" 9 "AIParkngReq_9_Fast_Parking" 10 "AIParkngReq_10_Line_out_System_Start" 11 "AIParkngReq_11_Line_back_System_Start" 12 "AIParkngReq_12_Call_to_Position_X" 13 "AIParkngReq_13_StartParkingScanningManualDriving" 14 "AIParkngReq_14_Remote_turn_left" 15 "AIParkngReq_15_Remote_turn_right" 16 "AIParkngReq_16_RememberBuildMap" 17 "AIParkngReq_17_Remember_Park_In" 18 "AIParkngReq_18_Remember_Summon" 19 "AIParkngReq_19_Start_Remember_Parking" 20 "AIParkngReq_20_Keep_Going_Forword" 21 "AIParkngReq_21_Keep_Going_Back" 22 "AIParkngReq_22_Start_AVP_in" 23 "AIParkngReq_23_Start_AVP_out" 24 "AIParkngReq_24_Back_Left_Parking_out" 25 "AIParkngReq_25_Back_Right_Parking_out" 26 "AIParkngReq_26_Start_NRCD" 27 "AIParkngReq_27_Front_Left_Cross_Park_Out" 28 "AIParkngReq_28_Front_Left_Parallel_ParkOut" 29 "AIParkngReq_29_Front_Out_Park_Out" 30 "AIParkngReq_30_Front_Right_Cross_ParkOut" 31 "AIParkngReq_31_Front_Right_Parallel_ParkOut" 32 "AIParkngReq_32_Back_Out_Park_Out" 33 "AIParkngReq_33_Back_Left_Cross_ParkOut" 34 "AIParkngReq_34_Back_Right_Cross_ParkOut" 35 "AIParkngReq_35_Start_Confirm" 36 "AIParkngReq_36_Start_RPI" 37 "AIParkngReq_37_Start_RPI_Super" 38 "AIParkngReq_38_Confirm" 39 "AIParkngReq_39_Quit" 40 "AIParkngReq_40_Start_RADS" 41 "AIParkngReq_41_Start_NPA" 42 "AIParkngReq_42_Recover_Remember_Park_in_XEquals1" 43 "AIParkngReq_43_Park_in_nearby_slot_XEquals1" 128 "AIParkngReq_128_Wakeup_network_XEquals8";
VAL_ 773 IFixType 0 "FixType_0_nofix" 1 "FixType_1_2dfix" 2 "FixType_2_3dfix";
VAL_ 974 IIAM_GNSS_Signal_Status 0 "IAM_GNSS_Signal_Status_0_Normal" 1 "IAM_GNSS_Signal_Status_1_Failure";
VAL_ 125 IAutodDrvngSysCtrlReq 1 "AutodDrvngSysCtrlReq_01_CancelAutomatedDrivingSystem" 17 "AutodDrvngSysCtrlReq_17_CallToLocationX" 33 "AutodDrvngSysCtrlReq_33_ParkToParkingSpaceIdX" 48 "AutodDrvngSysCtrlReq_48_ParkingInSystemStart" 50 "AutodDrvngSysCtrlReq_50_CancelParkingOrSummon" 51 "AutodDrvngSysCtrlReq_51_ParkingOutSystemStartLeftSide" 52 "AutodDrvngSysCtrlReq_52_LineOutSystemStart" 53 "AutodDrvngSysCtrlReq_53_LineBackSystemStart" 54 "AutodDrvngSysCtrlReq_54_ParkingOutSystemStartRightSide";
VAL_ 348 IFCWSnstvtLvl 0 "FCWSnstvtLvl_0_Unavailable" 1 "FCWSnstvtLvl_1_level1_low" 2 "FCWSnstvtLvl_2_level2_middle" 3 "FCWSnstvtLvl_3_level3_high";
VAL_ 348 IAEBDspCmd 0 "AEBDspCmd_0_unavailable" 1 "AEBDspCmd_1_off" 2 "AEBDspCmd_2_on";
VAL_ 348 IAEBMsgReq 0 "AEBMsgReq_0_NoDisplay" 1 "AEBMsgReq_1_UnableToActiveAeb" 2 "AEBMsgReq_2_Active" 3 "AEBMsgReq_3_AebIsInErrorMode" 4 "AEBMsgReq_4_AebIsSwitchedOn" 5 "AEBMsgReq_5_AebIsSwitchedOff" 6 "AEBMsgReq_6_RadarError" 7 "AEBMsgReq_7_reserved";
VAL_ 348 IFCWDspCmd 0 "FCWDspCmd_0_unavailable" 1 "FCWDspCmd_1_off" 2 "FCWDspCmd_2_on";
VAL_ 348 IFCWSysFltSts 0 "FCWSysFltSts_0_NoError" 1 "FCWSysFltSts_1_PerformanceDegradation" 2 "FCWSysFltSts_2_SystemTemporaryUnvailable" 3 "FCWSysFltSts_3_ServiceRequired" 4 "FCWSysFltSts_4_Reserved" 5 "FCWSysFltSts_5_Reserved" 6 "FCWSysFltSts_6_Reserved" 7 "FCWSysFltSts_7_Reserved";
VAL_ 348 IFCWrnngSts 0 "FCWrnngSts_0_NoRequest" 1 "FCWrnngSts_1_level1_low" 2 "FCWrnngSts_2_level2_middle" 3 "FCWrnngSts_3_level3_high";
VAL_ 348 IRembMapBldngQnty 0 "RembMapBldngQnty_0_No_Response" 1 "RembMapBldngQnty_1_1" 2 "RembMapBldngQnty_2_2" 3 "RembMapBldngQnty_3_Reserved";
VAL_ 348 IRembMapBldngReq 0 "RembMapBldngReq_0_No_Request" 1 "RembMapBldngReq_1_Remember_MapBuilding_Parking_out_Request" 2 "RembMapBldngReq_2_Remember_MapBuilding_Parking_In_Request" 3 "RembMapBldngReq_3_Reserved";
VAL_ 348 IRembBldMapReq 0 "RembBldMapReq_0_No_Request" 1 "RembBldMapReq_1_Remember_BuildMap__Parking_out_Request" 2 "RembBldMapReq_2_Remember_BuildMap__Parking_In_Request";
VAL_ 348 IFCTSysFltSts 0 "FCTSysFltSts_0_No_Error" 1 "FCTSysFltSts_1_System_Temporary_Unvailable" 2 "FCTSysFltSts_2_Service_Required" 3 "FCTSysFltSts_3_Service_Required";
VAL_ 348 IFCTSwSts 0 "FCTSwSts_0_unavaliable" 1 "FCTSwSts_1_driver_switch_FCTA_off" 2 "FCTSwSts_2_driver_switch_FCTA_on" 3 "FCTSwSts_3_driver_switch_FCTB__FCTA__on" 4 "FCTSwSts_4_Reserved" 5 "FCTSwSts_FunctionStatus_5_Reserved" 6 "FCTSwSts_FunctionStatus_6_Reserved" 7 "FCTSwSts_FunctionStatus_7_Reserved";
VAL_ 348 ILFCTWrnng 0 "LFCTAWrnng_0_no_warning" 1 "LFCTAWrnng_1_warning_level_1" 2 "LFCTAWrnng_2_warning_level_2" 3 "LFCTBActive_3_Active" 4 "LFCTAWrnng_4_reserved" 5 "LFCTAWrnng_5_reserved" 6 "LFCTAWrnng_6_reserved";
VAL_ 348 IRFCTWrnng 0 "RFCTAWrnng_0_no_warning" 1 "RFCTAWrnng_1_warning_level_1" 2 "RFCTAWrnng_2_warning_level_2" 3 "RFCTBActive_3_Active" 4 "RFCTAWrnng_4_reserved" 5 "RFCTAWrnng_5_reserved" 6 "RFCTAWrnng_6_reserved";
VAL_ 917 IAIPiloTIntervQuit 0 "AIPiloTIntervQuit_0_No_display" 1 "AIPiloTIntervQuit_1_SystemFailed_AIPilotIsQuit" 2 "AIPiloTIntervQuit_2_TrunkOpen_TakeOverPlease" 3 "AIPiloTIntervQuit_3_SeatbeltReleased_AIPilotIsQuit" 4 "AIPiloTIntervQuit_4_EPBSwitchPressed_AIPilotIsQuit" 5 "AIPiloTIntervQuit_5_DoorsOpen_AIPilotIsQuit" 6 "AIPiloTIntervQuit_6_HoodOpen_AIPilotIsQuit" 7 "AIPiloTIntervQuit_7_please_parking_the_vehicle" 8 "AIPiloTIntervQuit_8_VehicleSpeedIsTooFast_AIPilotIsQuit" 9 "AIPiloTIntervQuit_9_ESP_active_AIPilotIsQuit" 10 "AIPiloTIntervQuit_10_ParkingTimeOver15min_AIPilotIsQuit" 11 "AIPiloTIntervQuit_11_AIPilotIsQuit" 12 "AIPiloTIntervQuit_12_Camera_is_blocked_ACCIsQuit" 13 "AIPiloTIntervQuit_13_The_end_of_NOA" 14 "AIPiloTIntervQuit_14_NOA_is_not_available_at_the_front_XXM" 15 "AIPiloTIntervQuit_15_NOA_is_finished_at_the_front_XXM" 16 "AIPiloTIntervQuit_16_Waiting_for_timeout__AIPilotIsQuit" 17 "AIPiloTIntervQuit_17_Too_long_time_to_step_on_the_accelerator_TakeOverPlease" 18 "AIPiloTIntervQuit_18_ESP_is_closed_TakeOverPlease" 19 "AIPiloTIntervQuit_19_Reserved_1" 20 "AIPiloTIntervQuit_20_Reserved_2" 21 "AIPiloTIntervQuit_21_Reserved_3" 22 "AIPiloTIntervQuit_22_Reserved_4" 23 "AIPiloTIntervQuit_23_Reserved_5" 24 "AIPiloTIntervQuit_24_Reserved_6" 25 "AIPiloTIntervQuit_25_Reserved_7" 26 "AIPiloTIntervQuit_26_Reserved_8" 27 "AIPiloTIntervQuit_27_Reserved_9" 28 "AIPiloTIntervQuit_28_Reserved_10" 29 "AIPiloTIntervQuit_29_Reserved_11" 30 "AIPiloTIntervQuit_30_Reserved_12" 31 "AIPiloTIntervQuit_31_Reserved_13" 32 "AIPiloTIntervQuit_32_Reserved_14" 33 "AIPiloTIntervQuit_33_Reserved_15" 34 "AIPiloTIntervQuit_34_Reserved_16" 35 "AIPiloTIntervQuit_35_Reserved_17" 36 "AIPiloTIntervQuit_36_Reserved_18" 37 "AIPiloTIntervQuit_37_Reserved_19" 38 "AIPiloTIntervQuit_38_Reserved_20" 39 "AIPiloTIntervQuit_39_Reserved_21" 40 "AIPiloTIntervQuit_40_Reserved_22" 41 "AIPiloTIntervQuit_41_Reserved_23" 42 "AIPiloTIntervQuit_42_Reserved_24" 43 "AIPiloTIntervQuit_43_Reserved_25" 44 "AIPiloTIntervQuit_44_Reserved_26" 45 "AIPiloTIntervQuit_45_Reserved_27" 46 "AIPiloTIntervQuit_46_Reserved_28" 47 "AIPiloTIntervQuit_47_Reserved_29" 48 "AIPiloTIntervQuit_48_Reserved_30" 49 "AIPiloTIntervQuit_49_Reserved_31" 50 "AIPiloTIntervQuit_50_Reserved_32" 51 "AIPiloTIntervQuit_51_Reserved_33" 52 "AIPiloTIntervQuit_52_Reserved_34" 53 "AIPiloTIntervQuit_53_Reserved_35" 54 "AIPiloTIntervQuit_54_Reserved_36" 55 "AIPiloTIntervQuit_55_Reserved_37" 56 "AIPiloTIntervQuit_56_Reserved_38" 57 "AIPiloTIntervQuit_57_Reserved_39" 58 "AIPiloTIntervQuit_58_Reserved_40" 59 "AIPiloTIntervQuit_59_Reserved_41" 60 "AIPiloTIntervQuit_60_Reserved_42" 61 "AIPiloTIntervQuit_61_Reserved_43" 62 "AIPiloTIntervQuit_62_Reserved_44" 63 "AIPiloTIntervQuit_63_Reserved_45";
VAL_ 917 IAIParkngDsp 0 "AIParkngDsp_0_NoDisplay" 1 "AIParkngDsp_1_BrakePedalStepDownArtificiallyAutoParkingHasExitedTakeOverPlease" 2 "AIParkngDsp_2_SelfTestTimeoutAutoParkingHasExitedTakeOverPlease" 3 "AIParkngDsp_3_FlameoutTimeoutAutoParkingHasExitedTakeOverPlease" 4 "AIParkngDsp_4_BluetoothdisconnectedAutoParkingHasExitedTakeOverPlease" 5 "AIParkngDsp_5_NotUseOnPublicRoadMapBuildingfailed" 6 "AIParkngDsp_6_ElectricLockCompleted" 7 "AIParkngDsp_7_FailedLockCarAutoParkingHasExitedTakeOverPlease" 8 "AIParkngDsp_8_VehicleSelfTestFailureAutoParkingHasExitedTakeOverPlease" 9 "AIParkngDsp_9_FlameoutFailedAutoParkingHasExitedTakeOverPlease" 10 "AIParkngDsp_10_AutoParkingHasStopped" 11 "AIParkngDsp_11_FailedToCancelAutoParkingTryAgainOrTakeOver" 12 "AIParkngDsp_12_SystemFailedAutoParkingCancel" 13 "AIParkngDsp_13_NotUseOnPublicRoadTakeOverPlease" 14 "AIParkngDsp_14_WirelessCharginglocationIsSelectedpleaseslowdownandstop" 15 "AIParkngDsp_15_SystemTimeOutAutoParkingCancel" 16 "AIParkngDsp_16_AutoParkingIsSuspendedPressButtonToContiuneOrSelectAPPToContinueParkingIn" 17 "AIParkngDsp_17_SteeringWheelInterveneAutoParkingCancel" 18 "AIParkngDsp_18_PressContinueToPointAtWLC" 19 "AIParkngDsp_19_SheftLevelInterveneAutoParkingCancel" 20 "AIParkngDsp_20_CanntPointAtWLC" 21 "AIParkngDsp_21_ParkingDistanceIsBeyondLimitationAutoParkingCancel" 22 "AIParkngDsp_22_NumberOfAdjustmentsExceedsLimitationAutoParkingCancel" 23 "AIParkngDsp_23_AutoParkingRespondsToAccelerationDecelerateTobelow15kph" 24 "AIParkngDsp_24_VehicleSpeedHighAutoParkingCancel" 25 "AIParkngDsp_25_DoorsOrHoodOrTrunklidIsOpenMapBuildingfailed" 26 "AIParkngDsp_26_TrunkIsOpenAutoParkingCancel" 27 "AIParkngDsp_27_HoodIsOpenAutoParkingCancel" 28 "AIParkngDsp_28_AParkingSpaceIsFoundSelectOneOrStopPlease" 29 "AIParkngDsp_29_PressToStartParkingOrGetOffInPGearToSelectAPPOrKeyToContinueParkingIn" 30 "AIParkngDsp_30_Pleasebackupafterarrivingyourspace" 31 "AIParkngDsp_31_SearchForParkingSpaceSurroundingEnvironmentCarefully" 33 "AIParkngDsp_33_AutoParkingFinish" 34 "AIParkngDsp_34_AutoParkingCancelTakeOverPlease" 35 "AIParkngDsp_35_VehicleSpeedExceedDrivingRangeTakeOverPlease" 36 "AIParkngDsp_36_IntelligentParkingSurroundingEnvironmentCarefully" 37 "AIParkngDsp_37_ReleaseBrakePedalAndAutoParkingContinue" 38 "AIParkngDsp_38_ChargerIschargingAutoParkingCancel" 39 "AIParkngDsp_39_ExteriorMirrorIsAbnormalTakeOverPlease" 40 "AIParkngDsp_40_CameraIsBlockedTakeOverPlease" 41 "AIParkngDsp_41_EnvironmentIsAbnormalTakeOverPlease" 42 "AIParkngDsp_42_EncounteringObstaclesParkingIsSuspended" 43 "AIParkngDsp_43_ReversingtoolongMapBuildingfailed" 44 "AIParkngDsp_44_DoorIsOpen" 45 "AIParkngDsp_45_PowerButtonIsPressedAutoParkingCancel" 46 "AIParkngDsp_46_ObstaclesInParkingSpaceChangeOnePlease" 47 "AIParkngDsp_47_VehicleSpeedHigh" 48 "AIParkngDsp_48_SteeringWheelInterveneAutoParkingPaused" 49 "AIParkngDsp_49_PressToStartParkingOrGetOffToSelectAPPOrKeyToContinueParkingIn" 50 "AIParkngDsp_50_ObstaclesInTheTargetParkingSpaceRemove" 51 "AIParkngDsp_51_NotinspaceMapBuildingfailed" 52 "AIParkngDsp_52_PleaseHangPGear" 53 "AIParkngDsp_53_WaitMapFileUpgradeCompleted" 54 "AIParkngDsp_54_WaitAppUpgradeCompleted" 55 "AIParkngDsp_55_VehicleIsStart" 56 "AIParkngDsp_56_AirbagIsExpandedAutoParkingUnavailable" 57 "AIParkngDsp_57_TirePresureInormalAutoParkingUnavailable" 58 "AIParkngDsp_58_Aboutoparkinthespace" 59 "AIParkngDsp_59_MemoryparkingBeAwareOfSurroundings" 60 "AIParkngDsp_60_LongPressAndSearching" 61 "AIParkngDsp_61_AbnormalEnvironmentFunctionExit" 62 "AIParkngDsp_62_SteeringWheelTurnedArtificiallyTakeOver" 63 "AIParkngDsp_63_VehicleSlowDownAndStopPleaseReleaseAcceleratorPedal" 64 "AIParkngDsp_64_LongPressButtonToContinueParkIn" 65 "AIParkngDsp_65_APFunctionPausingPressTheButtonToContinue" 66 "AIParkngDsp_66_APFunctionPausingPressContinueButtonToContinue" 67 "AIParkngDsp_67_ExecutingRemoteCarMovingPleaseSetWheelAngleAndMovingDirecitonThenLongPressTheButton" 68 "AIParkngDsp_68_PassTheCrossingBeAwareOfSurroundings" 69 "AIParkngDsp_69_RemoteCarMovingPausingLongPressTheButtonToContinue" 70 "AIParkngDsp_70_Thedecelerationbeltisbumpy" 71 "AIParkngDsp_71_ParkingInFailedDoUWantToContinueSearchParkingSpace" 72 "AIParkngDsp_72_ThereAreXXXLeftPathLearningDistance" 73 "AIParkngDsp_73_NoLeftPathLearningDistanceAndOutOfLimitLearningFailed" 74 "AIParkngDsp_74_Turnleftahead" 75 "AIParkngDsp_75_Turnrightahead" 76 "AIParkngDsp_76_IntelligentMapEstablishing" 77 "AIParkngDsp_77_IntelligentMapEstablished" 78 "AIParkngDsp_78_LocalizationInitialized" 79 "AIParkngDsp_79_LocationInitializingPleaseDriveTheCarToStartPointOfEstablishedPath" 80 "AIParkngDsp_80_ParkingToThatDirectionIsDifficultPleaseChangeAnotherDirection" 81 "AIParkngDsp_81_CarDeviatingThePlanningPathPleaseSetCarStraight" 82 "AIParkngDsp_82_AvoidingBeAwareOfSurroundings" 83 "AIParkngDsp_83_FunctionDegradedToManulDrivingBecauseOfSystemTimeOut" 84 "AIParkngDsp_84_AVPParkingLotExistingAroundTheDestination" 85 "AIParkngDsp_85_PleaseDriveTheCarToSpecifiedLocation" 86 "AIParkngDsp_86_SloplargeMapBuildingfailed" 87 "AIParkngDsp_87_CarHasArrivedAtTheMeetingSpotPleaseTakeOver" 88 "AIParkngDsp_88_UnableToPassPleaseTakeOver" 89 "AIParkngDsp_89_MapVersionMismatchingPleaseUpdateMapVersion" 90 "AIParkngDsp_90_PathLocationLostPleaseTakeOver" 91 "AIParkngDsp_91_VideoChannelOccupiedCannotOpen360SorroundedView" 92 "AIParkngDsp_92_ConnectionDisconnectPleaseTakeOver" 93 "AIParkngDsp_93_IfSettingCarSpotFirstStopTheCarAndThenSettingTheSpot" 94 "AIParkngDsp_94_MapDownloading" 95 "AIParkngDsp_95_PositioningInitializationFailed" 96 "AIParkngDsp_96_PleasePutIntoGearPAndGetDownWithTheMobilePhoneToConnectTheVehicle" 97 "AIParkngDsp_97_PleasePutIntoGearPAndGetDownWithTheMobilePhoneToConnectTheVehicle" 98 "AIParkngDsp_98_AVPFunctionFinished" 99 "AIParkngDsp_99_AVPFunctionFailed" 100 "AIParkngDsp_100_SystemFailedMapBuildingfailed" 101 "AIParkngDsp_101_TheInternetDisable" 102 "AIParkngDsp_102_TimeOut" 103 "AIParkngDsp_103_MapDownloadingfailed" 104 "AIParkngDsp_104_Pleasemakesurethatyouhaveparkedinthestoragespaceandkeepthevehiclestationaryfor3seconds" 105 "AIParkngDsp_105_IntelligentMapBuildingfailed" 106 "AIParkngDsp_106_SpeedistoohighMapBuildingfailed" 107 "AIParkngDsp_107_DistancetooshortMapBuildingfailed" 108 "AIParkngDsp_108_DrivingonrampBeAwareOfSurroundings" 109 "AIParkngDsp_109_Theparkinginmaphasfailledandtheparkingoutmaphassucceed" 110 "AIParkngDsp_110_Themapisbeinggeneratedtheusercanleavenormallyandthepowerwillbeautomaticallypoweredoffaftercompletion" 111 "AIParkngDsp_111_PlschangeOthSpc" 113 "AIParkngDsp_113_ThereAre50LeftPathLearningDistance" 114 "AIParkngDsp_114_ThereAre10LeftPathLearningDistance" 115 "AIParkngDsp_115_SlowdowntobelowXXXPlease" 116 "AIParkngDsp_116_SloplargePleaseTakeOver" 117 "AIParkngDsp_117_BrakesteponPleaseTakeOver" 118 "AIParkngDsp_118_BeltRleasePleaseTakeOver" 119 "AIParkngDsp_119_TargetspacenotavailableOtherspaceforyou" 120 "AIParkngDsp_120_PayattentiontoenvironmentPlease" 121 "AIParkngDsp_121_PayattentiontoThecollisionriskPlease" 122 "AIParkngDsp_122_Reserved" 123 "AIParkngDsp_123_Reserved" 124 "AIParkngDsp_124_Reserved" 125 "AIParkngDsp_125_Reserved" 126 "AIParkngDsp_126_Reserved" 127 "AIParkngDsp_127_Reserved" 128 "AIParkngDsp_128_ParkoutByourselfPlease" 129 "AIParkngDsp_129_DistanceTooShort" 130 "AIParkngDsp_130_ExcessiveSlop" 131 "AIParkngDsp_131_LackOfFeatures" 132 "AIParkngDsp_132_DistanceTooLong" 133 "AIParkngDsp_133_TimeTooLong" 134 "AIParkngDsp_134_VerificationTooLong" 135 "AIParkngDsp_135_WriteInFailure" 136 "AIParkngDsp_136_Reserved" 137 "AIParkngDsp_137_Reserved" 138 "AIParkngDsp_138_Reserved" 139 "AIParkngDsp_139_Reserved" 140 "AIParkngDsp_140_Reserved" 141 "AIParkngDsp_141_Reserved" 142 "AIParkngDsp_142_Reserved" 143 "AIParkngDsp_143_Reserved" 144 "AIParkngDsp_144_DnagerTakeoverPlease" 145 "AIParkngDsp_145_DnagerTakeoverPlease" 146 "AIParkngDsp_146_ReverseParkingPayattentiontoenvironmentPlease" 147 "AIParkngDsp_147_ApplybrakeClickstartreversing" 148 "AIParkngDsp_148_trailisabouttoendTakeoverPlease" 149 "AIParkngDsp_149_trailisendTakeoverPlease" 150 "AIParkngDsp_150_FunctionexitTakeoverPlease" 151 "AIParkngDsp_151_PayattentiontoenvironmentPlease" 152 "AIParkngDsp_152_Completedhorizontaledging" 153 "AIParkngDsp_153_PleasePushPedel" 154 "AIParkngDsp_154_UnexpectedOperationInsideVehicle" 155 "AIParkngDsp_155_Reserved" 156 "AIParkngDsp_156_Reserved" 157 "AIParkngDsp_157_Reserved" 158 "AIParkngDsp_158_Reserved" 159 "AIParkngDsp_159_Reserved" 160 "AIParkngDsp_160_Reserved" 161 "AIParkngDsp_161_Reserved" 162 "AIParkngDsp_162_Reserved" 163 "AIParkngDsp_163_Reserved" 164 "AIParkngDsp_164_Reserved" 165 "AIParkngDsp_165_Reserved" 166 "AIParkngDsp_166_Reserved" 167 "AIParkngDsp_167_Reserved" 168 "AIParkngDsp_168_Reserved" 169 "AIParkngDsp_169_Reserved" 170 "AIParkngDsp_170_Reserved" 171 "AIParkngDsp_171_Reserved" 172 "AIParkngDsp_172_Reserved" 173 "AIParkngDsp_173_Reserved" 174 "AIParkngDsp_174_Reserved" 175 "AIParkngDsp_175_Reserved" 176 "AIParkngDsp_176_Reserved" 177 "AIParkngDsp_177_Reserved" 178 "AIParkngDsp_178_Reserved" 179 "AIParkngDsp_179_Reserved" 180 "AIParkngDsp_180_Reserved" 181 "AIParkngDsp_181_Reserved" 182 "AIParkngDsp_182_Reserved" 183 "AIParkngDsp_183_Reserved" 184 "AIParkngDsp_184_Reserved" 185 "AIParkngDsp_185_Reserved" 186 "AIParkngDsp_186_Reserved" 187 "AIParkngDsp_187_Reserved" 188 "AIParkngDsp_188_Reserved" 189 "AIParkngDsp_189_Reserved" 190 "AIParkngDsp_190_Reserved" 191 "AIParkngDsp_191_Reserved" 192 "AIParkngDsp_192_Reserved" 193 "AIParkngDsp_193_Reserved" 194 "AIParkngDsp_194_Reserved" 195 "AIParkngDsp_195_Reserved" 196 "AIParkngDsp_196_Reserved" 197 "AIParkngDsp_197_Reserved" 198 "AIParkngDsp_198_Reserved" 199 "AIParkngDsp_199_Reserved" 200 "AIParkngDsp_200_Reserved" 201 "AIParkngDsp_201_Reserved" 202 "AIParkngDsp_202_Reserved" 203 "AIParkngDsp_203_Reserved" 204 "AIParkngDsp_204_Reserved" 205 "AIParkngDsp_205_Reserved" 206 "AIParkngDsp_206_Reserved" 207 "AIParkngDsp_207_Reserved" 208 "AIParkngDsp_208_Reserved" 209 "AIParkngDsp_209_Reserved" 210 "AIParkngDsp_210_Reserved" 211 "AIParkngDsp_211_Reserved" 212 "AIParkngDsp_212_Reserved" 213 "AIParkngDsp_213_Reserved" 214 "AIParkngDsp_214_Reserved" 215 "AIParkngDsp_215_Reserved" 216 "AIParkngDsp_216_Reserved" 217 "AIParkngDsp_217_Reserved" 218 "AIParkngDsp_218_Reserved" 219 "AIParkngDsp_219_Reserved" 220 "AIParkngDsp_220_Reserved" 221 "AIParkngDsp_221_Reserved" 222 "AIParkngDsp_222_Reserved" 223 "AIParkngDsp_223_Reserved" 224 "AIParkngDsp_224_Reserved" 225 "AIParkngDsp_225_Reserved" 226 "AIParkngDsp_226_Reserved" 227 "AIParkngDsp_227_Reserved" 228 "AIParkngDsp_228_Reserved" 229 "AIParkngDsp_229_Reserved" 230 "AIParkngDsp_230_Reserved" 231 "AIParkngDsp_231_Reserved" 232 "AIParkngDsp_232_Reserved" 233 "AIParkngDsp_233_Reserved" 234 "AIParkngDsp_234_Reserved" 235 "AIParkngDsp_235_Reserved" 236 "AIParkngDsp_236_Reserved" 237 "AIParkngDsp_237_Reserved" 238 "AIParkngDsp_238_Reserved" 239 "AIParkngDsp_239_Reserved" 240 "AIParkngDsp_240_Reserved" 241 "AIParkngDsp_241_Reserved" 242 "AIParkngDsp_242_Reserved" 243 "AIParkngDsp_243_Reserved" 244 "AIParkngDsp_244_Reserved" 245 "AIParkngDsp_245_Reserved" 246 "AIParkngDsp_246_Reserved" 247 "AIParkngDsp_247_Reserved" 248 "AIParkngDsp_248_Reserved" 249 "AIParkngDsp_249_Reserved" 250 "AIParkngDsp_250_Reserved" 251 "AIParkngDsp_251_Reserved" 252 "AIParkngDsp_252_Reserved" 253 "AIParkngDsp_253_Reserved" 254 "AIParkngDsp_254_Reserved" 255 "AIParkngDsp_255_Reserved";
VAL_ 917 IAIParkngSts 0 "AIParkngSts_0_Off" 1 "AIParkngSts_1_ParkingDisable" 2 "AIParkngSts_2_ParkingJudging" 3 "AIParkngSts_3_SummonDisable" 4 "AIParkngSts_4_SummonJudging" 5 "AIParkngSts_5_MapBuilding" 6 "AIParkngSts_6_MapBuilding_APA_DrivingConfirming" 7 "AIParkngSts_7_LineMoving" 8 "AIParkngSts_8_LineMovePausing" 9 "AIParkngSts_9_MapBuilding_APA_ParkingInParking_ficm" 10 "AIParkngSts_10_ManualParkingInScanningParking_ficm" 11 "AIParkngSts_11_ManualParkingInScanningParking_ipk" 12 "AIParkngSts_12_LineMoveActive" 13 "AIParkngSts_13_SummonPausing" 14 "AIParkngSts_14_LVP_APA_Pausing" 15 "AIParkngSts_15_RememberParkingOut" 16 "AIParkngSts_16_Reserved" 17 "AIParkngSts_17_RememberParkOutPausing" 18 "AIParkngSts_18_LVP_ParkingInScanning_ficm" 19 "AIParkngSts_19_ParkingInScanning_app" 20 "AIParkngSts_20_ParkingInScanPausing" 21 "AIParkngSts_21_ParkingInSpaceConfirming" 22 "AIParkngSts_22_ParkingInParking_ficm" 23 "AIParkngSts_23_ParkingInParking_app" 24 "AIParkngSts_24_ParkingInParkPausing" 25 "AIParkngSts_25_ParkingOutParking_ficm" 26 "AIParkngSts_26_ParkingOutParking_app" 27 "AIParkngSts_27_ParkingOutPausing" 28 "AIParkngSts_28_ParkingOutParking_key" 29 "AIParkngSts_29_ParkingInParking_key" 30 "AIParkngSts_30_LVP_RemenberParkInSpaceConfirming" 31 "AIParkngSts_31_OtherFunctionConflictg" 32 "AIParkngSts_33_Reserved" 33 "AIParkngSts_33_AVPMapLoading" 34 "AIParkngSts_34_AVPCrusing" 35 "AIParkngSts_35_AVParkNaving" 36 "AIParkngSts_36_AVParkNavPausing" 37 "AIParkngSts_37_AVParking" 38 "AIParkngSts_38_AVParkPausing" 39 "AIParkngSts_39_AVParkingout" 40 "AIParkngSts_40_AVParkoutPausing" 41 "AIParkngSts_41_APAParkoutPreactive" 42 "AIParkngSts_42_Suspend" 43 "AIParkngSts_43_ManualDrivingConfirming" 44 "AIParkngSts_44_ConfirmingMobile" 45 "AIParkngSts_45_ParkingStandby" 46 "AIParkngSts_46_LVPStandby_confirming" 47 "AIParkngSts_47_MapBuilding_APA_ParkingDisable" 48 "AIParkngSts_48_Reserved" 49 "AIParkngSts_49_ManualParkingInScanningParking_wlc" 50 "AIParkngSts_50_MapBuilding_APA_Suspend" 51 "AIParkngSts_51_MapSuspend" 52 "AIParkngSts_52_MapBuilding_APA_ParkingJudging" 53 "AIParkngSts_53_LVPStandby" 54 "AIParkngSts_54_LVPPreactive" 55 "AIParkngSts_55_LVPParkingPreactive" 56 "AIParkngSts_56_LVPCruising" 57 "AIParkngSts_57_LVP_APA_Suspend" 58 "AIParkngSts_58_LVPComplete" 59 "AIParkngSts_59_MapBuildingComplete" 60 "AIParkngSts_60_MapBuildingFailure" 61 "AIParkngSts_61_MapCheck" 62 "AIParkngSts_62_MapBuilding_APA_ParkingInParkPausing" 63 "AIParkngSts_63_ParkoutMapBuildingComplete" 64 "AIParkngSts_64_ParkoutMapBuilding" 65 "AIParkngSts_65_LineMoveFailure" 66 "AIParkngSts_66_LVPFailure" 67 "AIParkngSts_67_AVP_Park_in_Preactive" 68 "AIParkngSts_68_AVP_Park_out_Preactive" 69 "AIParkngSts_69_LVP_APA_ParkingIN" 70 "AIParkngSts_70_RPAParkingoutPreactive" 71 "AIParkngSts_71_ParkingoutPausing_RPA" 72 "AIParkngSts_72_ManualConfirming_Key" 73 "AIParkngSts_73_ParkingInParkPausing_key" 74 "AIParkngSts_74_Suspend_key" 75 "AIParkngSts_75_OneClickAdjust" 76 "AIParkngSts_76_OneClickAdjustPausing" 77 "AIParkngSts_77_FunctionFailed" 78 "AIParkngSts_78_Reserved" 79 "AIParkngSts_79_Reserved" 80 "AIParkngSts_80_Reserved" 81 "AIParkngSts_81_Reserved" 82 "AIParkngSts_82_Reserved" 83 "AIParkngSts_83_Reserved" 84 "AIParkngSts_84_Reserved" 85 "AIParkngSts_85_Reserved" 86 "AIParkngSts_86_Reserved" 87 "AIParkngSts_87_Reserved" 88 "AIParkngSts_88_Reserved" 89 "AIParkngSts_89_Reserved" 90 "AIParkngSts_90_Reserved" 91 "AIParkngSts_91_Reserved" 92 "AIParkngSts_92_Reserved" 93 "AIParkngSts_93_Reserved" 94 "AIParkngSts_94_Reserved" 95 "AIParkngSts_95_Reserved" 96 "AIParkngSts_96_Reserved" 97 "AIParkngSts_97_Reserved" 98 "AIParkngSts_98_Reserved" 99 "AIParkngSts_99_Reserved" 100 "AIParkngSts_100_Reserved" 101 "AIParkngSts_101_Reserved" 102 "AIParkngSts_102_Reserved" 103 "AIParkngSts_103_Reserved" 104 "AIParkngSts_104_Reserved" 105 "AIParkngSts_105_Reserved" 106 "AIParkngSts_106_Reserved" 107 "AIParkngSts_107_Reserved" 108 "AIParkngSts_108_Reserved" 109 "AIParkngSts_109_Reserved" 110 "AIParkngSts_110_Reserved" 111 "AIParkngSts_111_Reserved" 112 "AIParkngSts_112_Reserved" 113 "AIParkngSts_113_Reserved" 114 "AIParkngSts_114_Reserved" 115 "AIParkngSts_115_Reserved" 116 "AIParkngSts_116_Reserved" 117 "AIParkngSts_117_Reserved" 118 "AIParkngSts_118_Reserved" 119 "AIParkngSts_119_Reserved" 120 "AIParkngSts_120_Reserved" 121 "AIParkngSts_121_Reserved" 122 "AIParkngSts_122_Reserved" 123 "AIParkngSts_123_Reserved" 124 "AIParkngSts_124_Reserved" 125 "AIParkngSts_125_Reserved" 126 "AIParkngSts_126_Reserved" 127 "AIParkngSts_127_Reserved" 128 "AIParkngSts_128_Reserved" 129 "AIParkngSts_129_Reserved" 130 "AIParkngSts_130_Reserved" 131 "AIParkngSts_131_Reserved" 132 "AIParkngSts_132_Reserved" 133 "AIParkngSts_133_Reserved" 134 "AIParkngSts_134_Reserved" 135 "AIParkngSts_135_Reserved" 136 "AIParkngSts_136_Reserved" 137 "AIParkngSts_137_Reserved" 138 "AIParkngSts_138_Reserved" 139 "AIParkngSts_139_Reserved" 140 "AIParkngSts_140_Reserved" 141 "AIParkngSts_141_Reserved" 142 "AIParkngSts_142_Reserved" 143 "AIParkngSts_143_Reserved" 144 "AIParkngSts_144_Reserved" 145 "AIParkngSts_145_Reserved" 146 "AIParkngSts_146_Reserved" 147 "AIParkngSts_147_Reserved" 148 "AIParkngSts_148_Reserved" 149 "AIParkngSts_149_Reserved" 150 "AIParkngSts_150_Reserved" 151 "AIParkngSts_151_Reserved" 152 "AIParkngSts_152_Reserved" 153 "AIParkngSts_153_Reserved" 154 "AIParkngSts_154_Reserved" 155 "AIParkngSts_155_Reserved" 156 "AIParkngSts_156_Reserved" 157 "AIParkngSts_157_Reserved" 158 "AIParkngSts_158_Reserved" 159 "AIParkngSts_159_Reserved" 160 "AIParkngSts_160_Reserved" 161 "AIParkngSts_161_Reserved" 162 "AIParkngSts_162_Reserved" 163 "AIParkngSts_163_Reserved" 164 "AIParkngSts_164_Reserved" 165 "AIParkngSts_165_Reserved" 166 "AIParkngSts_166_Reserved" 167 "AIParkngSts_167_Reserved" 168 "AIParkngSts_168_Reserved" 169 "AIParkngSts_169_Reserved" 170 "AIParkngSts_170_Reserved" 171 "AIParkngSts_171_Reserved" 172 "AIParkngSts_172_Reserved" 173 "AIParkngSts_173_Reserved" 174 "AIParkngSts_174_Reserved" 175 "AIParkngSts_175_Reserved" 176 "AIParkngSts_176_Reserved" 177 "AIParkngSts_177_Reserved" 178 "AIParkngSts_178_Reserved" 179 "AIParkngSts_179_Reserved" 180 "AIParkngSts_180_Reserved" 181 "AIParkngSts_181_Reserved" 182 "AIParkngSts_182_Reserved" 183 "AIParkngSts_183_Reserved" 184 "AIParkngSts_184_Reserved" 185 "AIParkngSts_185_Reserved" 186 "AIParkngSts_186_Reserved" 187 "AIParkngSts_187_Reserved" 188 "AIParkngSts_188_Reserved" 189 "AIParkngSts_189_Reserved" 190 "AIParkngSts_190_Reserved" 191 "AIParkngSts_191_Reserved" 192 "AIParkngSts_192_Reserved" 193 "AIParkngSts_193_Reserved" 194 "AIParkngSts_194_Reserved" 195 "AIParkngSts_195_Reserved" 196 "AIParkngSts_196_Reserved" 197 "AIParkngSts_197_Reserved" 198 "AIParkngSts_198_Reserved" 199 "AIParkngSts_199_Reserved" 200 "AIParkngSts_200_Reserved" 201 "AIParkngSts_201_Reserved" 202 "AIParkngSts_202_Reserved" 203 "AIParkngSts_203_Reserved" 204 "AIParkngSts_204_Reserved" 205 "AIParkngSts_205_Reserved" 206 "AIParkngSts_206_Reserved" 207 "AIParkngSts_207_Reserved" 208 "AIParkngSts_208_Reserved" 209 "AIParkngSts_209_Reserved" 210 "AIParkngSts_210_Reserved" 211 "AIParkngSts_211_Reserved" 212 "AIParkngSts_212_Reserved" 213 "AIParkngSts_213_Reserved" 214 "AIParkngSts_214_Reserved" 215 "AIParkngSts_215_Reserved" 216 "AIParkngSts_216_Reserved" 217 "AIParkngSts_217_Reserved" 218 "AIParkngSts_218_Reserved" 219 "AIParkngSts_219_Reserved" 220 "AIParkngSts_220_Reserved" 221 "AIParkngSts_221_Reserved" 222 "AIParkngSts_222_Reserved" 223 "AIParkngSts_223_Reserved" 224 "AIParkngSts_224_Reserved" 225 "AIParkngSts_225_Reserved" 226 "AIParkngSts_226_Reserved" 227 "AIParkngSts_227_Reserved" 228 "AIParkngSts_228_Reserved" 229 "AIParkngSts_229_Reserved" 230 "AIParkngSts_230_Reserved" 231 "AIParkngSts_231_Reserved" 232 "AIParkngSts_232_Reserved" 233 "AIParkngSts_233_Reserved" 234 "AIParkngSts_234_Reserved" 235 "AIParkngSts_235_Reserved" 236 "AIParkngSts_236_Reserved" 237 "AIParkngSts_237_Reserved" 238 "AIParkngSts_238_Reserved" 239 "AIParkngSts_239_Reserved" 240 "AIParkngSts_240_Reserved" 241 "AIParkngSts_241_Reserved" 242 "AIParkngSts_242_Reserved" 243 "AIParkngSts_243_Reserved" 244 "AIParkngSts_244_Reserved" 245 "AIParkngSts_245_Reserved" 246 "AIParkngSts_246_Reserved" 247 "AIParkngSts_247_Reserved" 248 "AIParkngSts_248_Reserved" 249 "AIParkngSts_249_Reserved" 250 "AIParkngSts_250_Reserved" 251 "AIParkngSts_251_Reserved" 252 "AIParkngSts_252_Reserved" 253 "AIParkngSts_253_Reserved" 254 "AIParkngSts_254_Reserved" 255 "AIParkngSts_255_Reserved";
SIG_GROUP_ 898 IFDR_100ms_Group01 1 : IFDRSts IFDR_100ms_Group01_CRC IFDR_100ms_Group01_RC IFDR_100ms_Group01_Reserved1 IFDR_100ms_Group01_Reserved2 IFDR_100ms_Group01_Reserved3 IFDR_100ms_Group01_Reserved4 IFDR_100ms_Group01_Reserved5 IFDR_100ms_Group01_Reserved6 IFDR_100ms_Group01_Reserved7;
SIG_GROUP_ 307 IFVCM_20ms_Group02 1 : IACCDetObjDistLvl IACCDrvrSelTrgtSpd IACCGoNotfr IACCMsgReq IACCSeldTrgtDistLvl IACCTJAMdSwDspCmd IELKSysSts_IPD IFVCM_20ms_Group02_CRC IFVCM_20ms_Group02_RC IFVCM_20ms_Group02_Reserved1 IFVCM_20ms_Group02_Reserved10 IFVCM_20ms_Group02_Reserved11 IFVCM_20ms_Group02_Reserved2 IFVCM_20ms_Group02_Reserved3 IFVCM_20ms_Group02_Reserved4 IFVCM_20ms_Group02_Reserved5 IFVCM_20ms_Group02_Reserved6 IFVCM_20ms_Group02_Reserved7 IFVCM_20ms_Group02_Reserved8 IFVCM_20ms_Group02_Reserved9 IHandOffStrgWhlDetnSta IHandOffStrgWhlDetnStaV IILCActvnDircnDspCmd IILCActvnVelDspCmd IILCSwDspCmd IILCSysSts ILDWAdoWrnngDspCmd ILDWLKAAudReq ILDWLKADspCmd ILDWLKAHptWrnngDspCmd ILDWSnstvtLvl ILKADrvrTkovReq;
SIG_GROUP_ 747 IFVCM_50ms_Group03 1 : IFVCM_50ms_Group03_CRC IFVCM_50ms_Group03_RC IFVCM_50ms_Group03_Reserved1 IFVCM_50ms_Group03_Reserved10 IFVCM_50ms_Group03_Reserved2 IFVCM_50ms_Group03_Reserved3 IFVCM_50ms_Group03_Reserved4 IFVCM_50ms_Group03_Reserved5 IFVCM_50ms_Group03_Reserved6 IFVCM_50ms_Group03_Reserved7 IFVCM_50ms_Group03_Reserved8 IFVCM_50ms_Group03_Reserved9 IKeepPwrRsnFVCM ITLRTrafficLightsCircleDsp;
SIG_GROUP_ 887 IIAM_100ms_Group08 1 : IAltSigma IIAM_100ms_Group08_CRC IIAM_100ms_Group08_RC IIAM_100ms_Group08_Reserved1 ILatSigma ILonSigma;
SIG_GROUP_ 912 IIAM_ZONE_100ms_Group34 1 : IHdop IIAM_ZONE_100ms_Group34_CRC IIAM_ZONE_100ms_Group34_RC IIAM_ZONE_100ms_Group34_Reserved0 IIAM_ZONE_100ms_Group34_Reserved1 IIAM_ZONE_100ms_Group34_Reserved2 IIAM_ZONE_100ms_Group34_Reserved3 IPdop IVdop;
SIG_GROUP_ 874 IIAM_ZONE_100ms_Group40 1 : IAltitudeRTK IHeadingRTK IIAM_ZONE_100ms_Group40_CRC IIAM_ZONE_100ms_Group40_RC IIAM_ZONE_100ms_Group40_Reserved0 IIAM_ZONE_100ms_Group40_Reserved1;
SIG_GROUP_ 336 IIAM_20ms_Group32 1 : IIAM_20ms_Group32_CRC IIAM_20ms_Group32_RC IIAM_20ms_Group32_Reserved1 IIAM_20ms_Group32_Reserved10 IIAM_20ms_Group32_Reserved11 IIAM_20ms_Group32_Reserved12 IIAM_20ms_Group32_Reserved13 IIAM_20ms_Group32_Reserved2 IIAM_20ms_Group32_Reserved3 IIAM_20ms_Group32_Reserved4 IIAM_20ms_Group32_Reserved5 IIAM_20ms_Group32_Reserved6 IIAM_20ms_Group32_Reserved7 IIAM_20ms_Group32_Reserved8 IIAM_20ms_Group32_Reserved9 IRmtParkngAstBtnSts IRmtParkngAstDvcSts IRmtParkngAstParkngOutDircnSeln IVehBkwdSwReq IVehFwdSwReq;
SIG_GROUP_ 811 IIAM_100ms_Group18 1 : IHeadingSigma IIAM_100ms_Group18_Reserved1 IIAM_100ms_PDU18_CRC IIAM_100ms_PDU18_RC IPitchRTK IPitchSigma;
SIG_GROUP_ 810 IIAM_ZONE_100ms_Group57 1 : IIAM_ZONE_100ms_Group57_CRC IIAM_ZONE_100ms_Group57_RC IIAM_ZONE_100ms_Group57_Reserved0 IIAM_ZONE_100ms_Group57_Reserved1 ILongitudeRTK;
SIG_GROUP_ 793 IIAM_ZONE_100ms_Group35 1 : IGNSSF9HCounter IGNSSUTCTime IIAM_ZONE_100ms_Group35_Reserved IIAM_ZONE_100ms_PDU35_CRC IIAM_ZONE_100ms_PDU35_RC;
SIG_GROUP_ 773 IIAM_ZONE_100ms_Group13 1 : IFixType IGNSSSeq IGNSSUTCTimeH IIAM_ZONE_100ms_Group13_CRC IIAM_ZONE_100ms_Group13_RC IIAM_ZONE_100ms_Group13_Reserved;
SIG_GROUP_ 974 IIAM_100ms_Group56 1 : IIAM_100ms_Group56_CRC IIAM_100ms_Group56_RC IIAM_100ms_Group56_Reserved1 IIAM_100ms_Group56_Reserved2 IIAM_GNSS_Signal_Status ILatitudeRTK;
